VERSION ""

NS_ :

BS_:

BU_: HVESP01 HVESS

BO_ 2499750245 HVESP01_EstOcv_1: 8 HVESP01
 SG_ HVESP01_estOcv_01_1 m0: 8|14@1+ (0.001,0) [0|16.383] "Ah"  HVESP01
 SG_ HVESP01_estOcv_02_1 m0: 22|14@1+ (0.001,0) [0|16.383] "Ah"  HVESP01
 SG_ HVESP01_estOcv_03_1 m0: 36|14@1+ (0.001,0) [0|16.383] "Ah"  HVESP01
 SG_ HVESP01_estOcv_04_1 m0: 50|14@1+ (0.001,0) [0|16.383] "Ah"  HVESP01
 SG_ HVESP01_estOcv_05_1 m1: 8|14@1+ (0.001,0) [0|16.383] "Ah"  HVESP01
 SG_ HVESP01_estOcv_06_1 m1: 22|14@1+ (0.001,0) [0|16.383] "Ah"  HVESP01
 SG_ HVESP01_estOcv_07_1 m1: 36|14@1+ (0.001,0) [0|16.383] "Ah"  HVESP01
 SG_ HVESP01_estOcv_08_1 m1: 50|14@1+ (0.001,0) [0|16.383] "Ah"  HVESP01
 SG_ HVESP01_estOcv_09_1 m2: 8|14@1+ (0.001,0) [0|16.383] "Ah"  HVESP01
 SG_ HVESP01_estOcv_10_1 m2: 22|14@1+ (0.001,0) [0|16.383] "Ah"  HVESP01
 SG_ HVESP01_estOcv_11_1 m2: 36|14@1+ (0.001,0) [0|16.383] "Ah"  HVESP01
 SG_ HVESP01_estOcv_12_1 m2: 50|14@1+ (0.001,0) [0|16.383] "Ah"  HVESP01
 SG_ HVESP01_estOcv_13_1 m3: 8|14@1+ (0.001,0) [0|16.383] "Ah"  HVESP01
 SG_ HVESP01_estOcv_14_1 m3: 22|14@1+ (0.001,0) [0|16.383] "Ah"  HVESP01
 SG_ HVESP01_estOcv_15_1 m3: 36|14@1+ (0.001,0) [0|16.383] "Ah"  HVESP01
 SG_ HVESP01_estOcv_16_1 m3: 50|14@1+ (0.001,0) [0|16.383] "Ah"  HVESP01
 SG_ HVESP01_estOcv_17_1 m4: 8|14@1+ (0.001,0) [0|16.383] "Ah"  HVESP01
 SG_ HVESP01_estOcv_18_1 m4: 22|14@1+ (0.001,0) [0|16.383] "Ah"  HVESP01
 SG_ HVESP01_estOcv_19_1 m4: 36|14@1+ (0.001,0) [0|16.383] "Ah"  HVESP01
 SG_ HVESP01_estOcv_20_1 m4: 50|14@1+ (0.001,0) [0|16.383] "Ah"  HVESP01
 SG_ HVESP01_estOcv_21_1 m5: 8|14@1+ (0.001,0) [0|16.383] "Ah"  HVESP01
 SG_ HVESP01_estOcv_22_1 m5: 22|14@1+ (0.001,0) [0|16.383] "Ah"  HVESP01
 SG_ HVESP01_estOcv_23_1 m5: 36|14@1+ (0.001,0) [0|16.383] "Ah"  HVESP01
 SG_ HVESP01_estOcv_24_1 m5: 50|14@1+ (0.001,0) [0|16.383] "Ah"  HVESP01
 SG_ HVESP01_estOcv_25_1 m6: 8|14@1+ (0.001,0) [0|16.383] "Ah"  HVESP01
 SG_ HVESP01_estOcv_26_1 m6: 22|14@1+ (0.001,0) [0|16.383] "Ah"  HVESP01
 SG_ HVESP01_estOcv_27_1 m6: 36|14@1+ (0.001,0) [0|16.383] "Ah"  HVESP01
 SG_ HVESP01_estOcv_28_1 m6: 50|14@1+ (0.001,0) [0|16.383] "Ah"  HVESP01
 SG_ HVESP01_estOcv_29_1 m7: 8|14@1+ (0.001,0) [0|16.383] "Ah"  HVESP01
 SG_ HVESP01_estOcv_30_1 m7: 22|14@1+ (0.001,0) [0|16.383] "Ah"  HVESP01
 SG_ HVESP01_estOcv_31_1 m7: 36|14@1+ (0.001,0) [0|16.383] "Ah"  HVESP01
 SG_ HVESP01_estOcv_32_1 m7: 50|14@1+ (0.001,0) [0|16.383] "Ah"  HVESP01
 SG_ HVESP01_estOcv_33_1 m8: 8|14@1+ (0.001,0) [0|16.383] "Ah"  HVESP01
 SG_ HVESP01_estOcv_34_1 m8: 22|14@1+ (0.001,0) [0|16.383] "Ah"  HVESP01
 SG_ HVESP01_estOcv_35_1 m8: 36|14@1+ (0.001,0) [0|16.383] "Ah"  HVESP01
 SG_ HVESP01_estOcv_36_1 m8: 50|14@1+ (0.001,0) [0|16.383] "Ah"  HVESP01
 SG_ HVESP01_estOcv_37_1 m9: 8|14@1+ (0.001,0) [0|16.383] "Ah"  HVESP01
 SG_ HVESP01_estOcv_38_1 m9: 22|14@1+ (0.001,0) [0|16.383] "Ah"  HVESP01
 SG_ HVESP01_estOcv_39_1 m9: 36|14@1+ (0.001,0) [0|16.383] "Ah"  HVESP01
 SG_ HVESP01_estOcv_40_1 m9: 50|14@1+ (0.001,0) [0|16.383] "Ah"  HVESP01
 SG_ HVESP01_estOcv_41_1 m10: 8|14@1+ (0.001,0) [0|16.383] "Ah"  HVESP01
 SG_ HVESP01_estOcv_42_1 m10: 22|14@1+ (0.001,0) [0|16.383] "Ah"  HVESP01
 SG_ HVESP01_estOcv_43_1 m10: 36|14@1+ (0.001,0) [0|16.383] "Ah"  HVESP01
 SG_ HVESP01_estOcv_44_1 m10: 50|14@1+ (0.001,0) [0|16.383] "Ah"  HVESP01
 SG_ HVESP01_estOcv_45_1 m11: 8|14@1+ (0.001,0) [0|16.383] "Ah"  HVESP01
 SG_ HVESP01_estOcv_46_1 m11: 22|14@1+ (0.001,0) [0|16.383] "Ah"  HVESP01
 SG_ HVESP01_estOcv_47_1 m11: 36|14@1+ (0.001,0) [0|16.383] "Ah"  HVESP01
 SG_ HVESP01_estOcv_48_1 m11: 50|14@1+ (0.001,0) [0|16.383] "Ah"  HVESP01
 SG_ HVESP01_estOcv_49_1 m12: 8|14@1+ (0.001,0) [0|16.383] "Ah"  HVESP01
 SG_ HVESP01_estOcv_50_1 m12: 22|14@1+ (0.001,0) [0|16.383] "Ah"  HVESP01
 SG_ HVESP01_estOcv_51_1 m12: 36|14@1+ (0.001,0) [0|16.383] "Ah"  HVESP01
 SG_ HVESP01_estOcv_52_1 m12: 50|14@1+ (0.001,0) [0|16.383] "Ah"  HVESP01
 SG_ HVESP01_estOcv_53_1 m13: 8|14@1+ (0.001,0) [0|16.383] "Ah"  HVESP01
 SG_ HVESP01_estOcv_54_1 m13: 22|14@1+ (0.001,0) [0|16.383] "Ah"  HVESP01
 SG_ HVESP01_estOcv_55_1 m13: 36|14@1+ (0.001,0) [0|16.383] "Ah"  HVESP01
 SG_ HVESP01_estOcv_56_1 m13: 50|14@1+ (0.001,0) [0|16.383] "Ah"  HVESP01
 SG_ HVESP01_estOcv_57_1 m14: 8|14@1+ (0.001,0) [0|16.383] "Ah"  HVESP01
 SG_ HVESP01_estOcv_58_1 m14: 22|14@1+ (0.001,0) [0|16.383] "Ah"  HVESP01
 SG_ HVESP01_estOcv_59_1 m14: 36|14@1+ (0.001,0) [0|16.383] "Ah"  HVESP01
 SG_ HVESP01_estOcv_60_1 m14: 50|14@1+ (0.001,0) [0|16.383] "Ah"  HVESP01
 SG_ HVESP01_estOcv_61_1 m15: 8|14@1+ (0.001,0) [0|16.383] "Ah"  HVESP01
 SG_ HVESP01_estOcv_62_1 m15: 22|14@1+ (0.001,0) [0|16.383] "Ah"  HVESP01
 SG_ HVESP01_estOcv_63_1 m15: 36|14@1+ (0.001,0) [0|16.383] "Ah"  HVESP01
 SG_ HVESP01_estOcv_64_1 m15: 50|14@1+ (0.001,0) [0|16.383] "Ah"  HVESP01
 SG_ HVESP01_estOcv_65_1 m16: 8|14@1+ (0.001,0) [0|16.383] "Ah"  HVESP01
 SG_ HVESP01_estOcv_66_1 m16: 22|14@1+ (0.001,0) [0|16.383] "Ah"  HVESP01
 SG_ HVESP01_estOcv_67_1 m16: 36|14@1+ (0.001,0) [0|16.383] "Ah"  HVESP01
 SG_ HVESP01_estOcv_68_1 m16: 50|14@1+ (0.001,0) [0|16.383] "Ah"  HVESP01
 SG_ HVESP01_estOcv_69_1 m17: 8|14@1+ (0.001,0) [0|16.383] "Ah"  HVESP01
 SG_ HVESP01_estOcv_70_1 m17: 22|14@1+ (0.001,0) [0|16.383] "Ah"  HVESP01
 SG_ HVESP01_estOcv_71_1 m17: 36|14@1+ (0.001,0) [0|16.383] "Ah"  HVESP01
 SG_ HVESP01_estOcv_72_1 m17: 50|14@1+ (0.001,0) [0|16.383] "Ah"  HVESP01
 SG_ HVESP01_estOcv_73_1 m18: 8|14@1+ (0.001,0) [0|16.383] "Ah"  HVESP01
 SG_ HVESP01_estOcv_74_1 m18: 22|14@1+ (0.001,0) [0|16.383] "Ah"  HVESP01
 SG_ HVESP01_estOcv_75_1 m18: 36|14@1+ (0.001,0) [0|16.383] "Ah"  HVESP01
 SG_ HVESP01_estOcv_76_1 m18: 50|14@1+ (0.001,0) [0|16.383] "Ah"  HVESP01
 SG_ HVESP01_estOcv_77_1 m19: 8|14@1+ (0.001,0) [0|16.383] "Ah"  HVESP01
 SG_ HVESP01_estOcv_78_1 m19: 22|14@1+ (0.001,0) [0|16.383] "Ah"  HVESP01
 SG_ HVESP01_estOcv_79_1 m19: 36|14@1+ (0.001,0) [0|16.383] "Ah"  HVESP01
 SG_ HVESP01_estOcv_80_1 m19: 50|14@1+ (0.001,0) [0|16.383] "Ah"  HVESP01
 SG_ HVESP01_estOcv_81_1 m20: 8|14@1+ (0.001,0) [0|16.383] "Ah"  HVESP01
 SG_ HVESP01_estOcv_82_1 m20: 22|14@1+ (0.001,0) [0|16.383] "Ah"  HVESP01
 SG_ HVESP01_estOcv_83_1 m20: 36|14@1+ (0.001,0) [0|16.383] "Ah"  HVESP01
 SG_ HVESP01_estOcv_84_1 m20: 50|14@1+ (0.001,0) [0|16.383] "Ah"  HVESP01
 SG_ HVESP01_estOcv_85_1 m21: 8|14@1+ (0.001,0) [0|16.383] "Ah"  HVESP01
 SG_ HVESP01_estOcv_86_1 m21: 22|14@1+ (0.001,0) [0|16.383] "Ah"  HVESP01
 SG_ HVESP01_estOcv_87_1 m21: 36|14@1+ (0.001,0) [0|16.383] "Ah"  HVESP01
 SG_ HVESP01_estOcv_88_1 m21: 50|14@1+ (0.001,0) [0|16.383] "Ah"  HVESP01
 SG_ HVESP01_estOcv_89_1 m22: 8|14@1+ (0.001,0) [0|16.383] "Ah"  HVESP01
 SG_ HVESP01_estOcv_90_1 m22: 22|14@1+ (0.001,0) [0|16.383] "Ah"  HVESP01
 SG_ HVESP01_estOcv_91_1 m22: 36|14@1+ (0.001,0) [0|16.383] "Ah"  HVESP01
 SG_ HVESP01_estOcv_92_1 m22: 50|14@1+ (0.001,0) [0|16.383] "Ah"  HVESP01
 SG_ HVESP01_estOcv_93_1 m23: 8|14@1+ (0.001,0) [0|16.383] "Ah"  HVESP01
 SG_ HVESP01_estOcv_94_1 m23: 22|14@1+ (0.001,0) [0|16.383] "Ah"  HVESP01
 SG_ HVESP01_estOcv_95_1 m23: 36|14@1+ (0.001,0) [0|16.383] "Ah"  HVESP01
 SG_ HVESP01_estOcv_96_1 m23: 50|14@1+ (0.001,0) [0|16.383] "Ah"  HVESP01
 SG_ HVESP01_estOcv_97_1 m24: 8|14@1+ (0.001,0) [0|16.383] "Ah"  HVESP01
 SG_ HVESP01_estOcv_98_1 m24: 22|14@1+ (0.001,0) [0|16.383] "Ah"  HVESP01
 SG_ HVESP01_estOcv_99_1 m24: 36|14@1+ (0.001,0) [0|16.383] "Ah"  HVESP01
 SG_ HVESP01_estOcv_100_1 m24: 50|14@1+ (0.001,0) [0|16.383] "Ah"  HVESP01
 SG_ HVESP01_estOcv_101_1 m25: 8|14@1+ (0.001,0) [0|16.383] "Ah"  HVESP01
 SG_ HVESP01_estOcv_102_1 m25: 22|14@1+ (0.001,0) [0|16.383] "Ah"  HVESP01
 SG_ HVESP01_estOcv_103_1 m25: 36|14@1+ (0.001,0) [0|16.383] "Ah"  HVESP01
 SG_ HVESP01_estOcv_104_1 m25: 50|14@1+ (0.001,0) [0|16.383] "Ah"  HVESP01
 SG_ HVESP01_estOcv_105_1 m26: 8|14@1+ (0.001,0) [0|16.383] "Ah"  HVESP01
 SG_ HVESP01_estOcv_106_1 m26: 22|14@1+ (0.001,0) [0|16.383] "Ah"  HVESP01
 SG_ HVESP01_estOcv_107_1 m26: 36|14@1+ (0.001,0) [0|16.383] "Ah"  HVESP01
 SG_ HVESP01_estOcv_108_1 m26: 50|14@1+ (0.001,0) [0|16.383] "Ah"  HVESP01
 SG_ HVESP01_estOcv_109_1 m27: 8|14@1+ (0.001,0) [0|16.383] "Ah"  HVESP01
 SG_ HVESP01_estOcv_110_1 m27: 22|14@1+ (0.001,0) [0|16.383] "Ah"  HVESP01
 SG_ HVESP01_estOcv_111_1 m27: 36|14@1+ (0.001,0) [0|16.383] "Ah"  HVESP01
 SG_ HVESP01_estOcv_112_1 m27: 50|14@1+ (0.001,0) [0|16.383] "Ah"  HVESP01
 SG_ HVESP01_estOcv_113_1 m28: 8|14@1+ (0.001,0) [0|16.383] "Ah"  HVESP01
 SG_ HVESP01_estOcv_114_1 m28: 22|14@1+ (0.001,0) [0|16.383] "Ah"  HVESP01
 SG_ HVESP01_estOcv_115_1 m28: 36|14@1+ (0.001,0) [0|16.383] "Ah"  HVESP01
 SG_ HVESP01_estOcv_116_1 m28: 50|14@1+ (0.001,0) [0|16.383] "Ah"  HVESP01
 SG_ HVESP01_estOcv_117_1 m29: 8|14@1+ (0.001,0) [0|16.383] "Ah"  HVESP01
 SG_ HVESP01_estOcv_118_1 m29: 22|14@1+ (0.001,0) [0|16.383] "Ah"  HVESP01
 SG_ HVESP01_estOcv_119_1 m29: 36|14@1+ (0.001,0) [0|16.383] "Ah"  HVESP01
 SG_ HVESP01_estOcv_120_1 m29: 50|14@1+ (0.001,0) [0|16.383] "Ah"  HVESP01
 SG_ HVESP01_estOcv_121_1 m30: 8|14@1+ (0.001,0) [0|16.383] "Ah"  HVESP01
 SG_ HVESP01_estOcv_122_1 m30: 22|14@1+ (0.001,0) [0|16.383] "Ah"  HVESP01
 SG_ HVESP01_estOcv_123_1 m30: 36|14@1+ (0.001,0) [0|16.383] "Ah"  HVESP01
 SG_ HVESP01_estOcv_124_1 m30: 50|14@1+ (0.001,0) [0|16.383] "Ah"  HVESP01
 SG_ HVESP01_estOcv_125_1 m31: 8|14@1+ (0.001,0) [0|16.383] "Ah"  HVESP01
 SG_ HVESP01_estOcv_126_1 m31: 22|14@1+ (0.001,0) [0|16.383] "Ah"  HVESP01
 SG_ HVESP01_estOcv_127_1 m31: 36|14@1+ (0.001,0) [0|16.383] "Ah"  HVESP01
 SG_ HVESP01_estOcv_128_1 m31: 50|14@1+ (0.001,0) [0|16.383] "Ah"  HVESP01
 SG_ HVESP01_estOcv_129_1 m32: 8|14@1+ (0.001,0) [0|16.383] "Ah"  HVESP01
 SG_ HVESP01_estOcv_130_1 m32: 22|14@1+ (0.001,0) [0|16.383] "Ah"  HVESP01
 SG_ HVESP01_estOcv_131_1 m32: 36|14@1+ (0.001,0) [0|16.383] "Ah"  HVESP01
 SG_ HVESP01_estOcv_132_1 m32: 50|14@1+ (0.001,0) [0|16.383] "Ah"  HVESP01
 SG_ HVESP01_estOcv_133_1 m33: 8|14@1+ (0.001,0) [0|16.383] "Ah"  HVESP01
 SG_ HVESP01_estOcv_134_1 m33: 22|14@1+ (0.001,0) [0|16.383] "Ah"  HVESP01
 SG_ HVESP01_estOcv_135_1 m33: 36|14@1+ (0.001,0) [0|16.383] "Ah"  HVESP01
 SG_ HVESP01_estOcv_136_1 m33: 50|14@1+ (0.001,0) [0|16.383] "Ah"  HVESP01
 SG_ HVESP01_estOcv_137_1 m34: 8|14@1+ (0.001,0) [0|16.383] "Ah"  HVESP01
 SG_ HVESP01_estOcv_138_1 m34: 22|14@1+ (0.001,0) [0|16.383] "Ah"  HVESP01
 SG_ HVESP01_estOcv_139_1 m34: 36|14@1+ (0.001,0) [0|16.383] "Ah"  HVESP01
 SG_ HVESP01_estOcv_140_1 m34: 50|14@1+ (0.001,0) [0|16.383] "Ah"  HVESP01
 SG_ HVESP01_estOcv_141_1 m35: 8|14@1+ (0.001,0) [0|16.383] "Ah"  HVESP01
 SG_ HVESP01_estOcv_142_1 m35: 22|14@1+ (0.001,0) [0|16.383] "Ah"  HVESP01
 SG_ HVESP01_estOcv_143_1 m35: 36|14@1+ (0.001,0) [0|16.383] "Ah"  HVESP01
 SG_ HVESP01_estOcv_144_1 m35: 50|14@1+ (0.001,0) [0|16.383] "Ah"  HVESP01
 SG_ HVESP01_estOcv_145_1 m36: 8|14@1+ (0.001,0) [0|16.383] "Ah"  HVESP01
 SG_ HVESP01_estOcv_146_1 m36: 22|14@1+ (0.001,0) [0|16.383] "Ah"  HVESP01
 SG_ HVESP01_estOcv_147_1 m36: 36|14@1+ (0.001,0) [0|16.383] "Ah"  HVESP01
 SG_ HVESP01_estOcv_148_1 m36: 50|14@1+ (0.001,0) [0|16.383] "Ah"  HVESP01
 SG_ HVESP01_estOcv_149_1 m37: 8|14@1+ (0.001,0) [0|16.383] "Ah"  HVESP01
 SG_ HVESP01_estOcv_150_1 m37: 22|14@1+ (0.001,0) [0|16.383] "Ah"  HVESP01
 SG_ HVESP01_estOcv_151_1 m37: 36|14@1+ (0.001,0) [0|16.383] "Ah"  HVESP01
 SG_ HVESP01_estOcv_152_1 m37: 50|14@1+ (0.001,0) [0|16.383] "Ah"  HVESP01
 SG_ HVESP01_estOcv_153_1 m38: 8|14@1+ (0.001,0) [0|16.383] "Ah"  HVESP01
 SG_ HVESP01_estOcv_154_1 m38: 22|14@1+ (0.001,0) [0|16.383] "Ah"  HVESP01
 SG_ HVESP01_estOcv_155_1 m38: 36|14@1+ (0.001,0) [0|16.383] "Ah"  HVESP01
 SG_ HVESP01_estOcv_156_1 m38: 50|14@1+ (0.001,0) [0|16.383] "Ah"  HVESP01
 SG_ HVESP01_estOcv_157_1 m39: 8|14@1+ (0.001,0) [0|16.383] "Ah"  HVESP01
 SG_ HVESP01_estOcv_158_1 m39: 22|14@1+ (0.001,0) [0|16.383] "Ah"  HVESP01
 SG_ HVESP01_estOcv_159_1 m39: 36|14@1+ (0.001,0) [0|16.383] "Ah"  HVESP01
 SG_ HVESP01_estOcv_160_1 m39: 50|14@1+ (0.001,0) [0|16.383] "Ah"  HVESP01
 SG_ HVESP01_estOcv_161_1 m40: 8|14@1+ (0.001,0) [0|16.383] "Ah"  HVESP01
 SG_ HVESP01_estOcv_162_1 m40: 22|14@1+ (0.001,0) [0|16.383] "Ah"  HVESP01
 SG_ HVESP01_estOcv_163_1 m40: 36|14@1+ (0.001,0) [0|16.383] "Ah"  HVESP01
 SG_ HVESP01_estOcv_164_1 m40: 50|14@1+ (0.001,0) [0|16.383] "Ah"  HVESP01
 SG_ HVESP01_estOcv_165_1 m41: 8|14@1+ (0.001,0) [0|16.383] "Ah"  HVESP01
 SG_ HVESP01_estOcv_166_1 m41: 22|14@1+ (0.001,0) [0|16.383] "Ah"  HVESP01
 SG_ HVESP01_estOcv_167_1 m41: 36|14@1+ (0.001,0) [0|16.383] "Ah"  HVESP01
 SG_ HVESP01_estOcv_168_1 m41: 50|14@1+ (0.001,0) [0|16.383] "Ah"  HVESP01
 SG_ HVESP01_estOcv_169_1 m42: 8|14@1+ (0.001,0) [0|16.383] "Ah"  HVESP01
 SG_ HVESP01_estOcv_170_1 m42: 22|14@1+ (0.001,0) [0|16.383] "Ah"  HVESP01
 SG_ HVESP01_estOcv_171_1 m42: 36|14@1+ (0.001,0) [0|16.383] "Ah"  HVESP01
 SG_ HVESP01_estOcv_172_1 m42: 50|14@1+ (0.001,0) [0|16.383] "Ah"  HVESP01
 SG_ HVESP01_estOcv_173_1 m43: 8|14@1+ (0.001,0) [0|16.383] "Ah"  HVESP01
 SG_ HVESP01_estOcv_174_1 m43: 22|14@1+ (0.001,0) [0|16.383] "Ah"  HVESP01
 SG_ HVESP01_estOcv_175_1 m43: 36|14@1+ (0.001,0) [0|16.383] "Ah"  HVESP01
 SG_ HVESP01_estOcv_176_1 m43: 50|14@1+ (0.001,0) [0|16.383] "Ah"  HVESP01
 SG_ HVESP01_estOcv_177_1 m44: 8|14@1+ (0.001,0) [0|16.383] "Ah"  HVESP01
 SG_ HVESP01_estOcv_178_1 m44: 22|14@1+ (0.001,0) [0|16.383] "Ah"  HVESP01
 SG_ HVESP01_estOcv_179_1 m44: 36|14@1+ (0.001,0) [0|16.383] "Ah"  HVESP01
 SG_ HVESP01_estOcv_180_1 m44: 50|14@1+ (0.001,0) [0|16.383] "Ah"  HVESP01
 SG_ HVESP01_estOcv_181_1 m45: 8|14@1+ (0.001,0) [0|16.383] "Ah"  HVESP01
 SG_ HVESP01_estOcv_182_1 m45: 22|14@1+ (0.001,0) [0|16.383] "Ah"  HVESP01
 SG_ HVESP01_estOcv_183_1 m45: 36|14@1+ (0.001,0) [0|16.383] "Ah"  HVESP01
 SG_ HVESP01_estOcv_184_1 m45: 50|14@1+ (0.001,0) [0|16.383] "Ah"  HVESP01
 SG_ HVESP01_estOcv_185_1 m46: 8|14@1+ (0.001,0) [0|16.383] "Ah"  HVESP01
 SG_ HVESP01_estOcv_186_1 m46: 22|14@1+ (0.001,0) [0|16.383] "Ah"  HVESP01
 SG_ HVESP01_estOcv_187_1 m46: 36|14@1+ (0.001,0) [0|16.383] "Ah"  HVESP01
 SG_ HVESP01_estOcv_188_1 m46: 50|14@1+ (0.001,0) [0|16.383] "Ah"  HVESP01
 SG_ HVESP01_estOcv_189_1 m47: 8|14@1+ (0.001,0) [0|16.383] "Ah"  HVESP01
 SG_ HVESP01_estOcv_190_1 m47: 22|14@1+ (0.001,0) [0|16.383] "Ah"  HVESP01
 SG_ HVESP01_estOcv_191_1 m47: 36|14@1+ (0.001,0) [0|16.383] "Ah"  HVESP01
 SG_ HVESP01_estOcv_192_1 m47: 50|14@1+ (0.001,0) [0|16.383] "Ah"  HVESP01
 SG_ multiplexoreo_1 M: 0|8@1+ (1,0) [0|255] ""  HVESP01

BO_ 2499750246 HVESP01_EstOcv_2: 8 HVESP01
 SG_ HVESP01_estOcv_01_2 m0: 8|14@1+ (0.001,0) [0|16.383] "Ah"  HVESP01
 SG_ HVESP01_estOcv_02_2 m0: 22|14@1+ (0.001,0) [0|16.383] "Ah"  HVESP01
 SG_ HVESP01_estOcv_03_2 m0: 36|14@1+ (0.001,0) [0|16.383] "Ah"  HVESP01
 SG_ HVESP01_estOcv_04_2 m0: 50|14@1+ (0.001,0) [0|16.383] "Ah"  HVESP01
 SG_ HVESP01_estOcv_05_2 m1: 8|14@1+ (0.001,0) [0|16.383] "Ah"  HVESP01
 SG_ HVESP01_estOcv_06_2 m1: 22|14@1+ (0.001,0) [0|16.383] "Ah"  HVESP01
 SG_ HVESP01_estOcv_07_2 m1: 36|14@1+ (0.001,0) [0|16.383] "Ah"  HVESP01
 SG_ HVESP01_estOcv_08_2 m1: 50|14@1+ (0.001,0) [0|16.383] "Ah"  HVESP01
 SG_ HVESP01_estOcv_09_2 m2: 8|14@1+ (0.001,0) [0|16.383] "Ah"  HVESP01
 SG_ HVESP01_estOcv_10_2 m2: 22|14@1+ (0.001,0) [0|16.383] "Ah"  HVESP01
 SG_ HVESP01_estOcv_11_2 m2: 36|14@1+ (0.001,0) [0|16.383] "Ah"  HVESP01
 SG_ HVESP01_estOcv_12_2 m2: 50|14@1+ (0.001,0) [0|16.383] "Ah"  HVESP01
 SG_ HVESP01_estOcv_13_2 m3: 8|14@1+ (0.001,0) [0|16.383] "Ah"  HVESP01
 SG_ HVESP01_estOcv_14_2 m3: 22|14@1+ (0.001,0) [0|16.383] "Ah"  HVESP01
 SG_ HVESP01_estOcv_15_2 m3: 36|14@1+ (0.001,0) [0|16.383] "Ah"  HVESP01
 SG_ HVESP01_estOcv_16_2 m3: 50|14@1+ (0.001,0) [0|16.383] "Ah"  HVESP01
 SG_ HVESP01_estOcv_17_2 m4: 8|14@1+ (0.001,0) [0|16.383] "Ah"  HVESP01
 SG_ HVESP01_estOcv_18_2 m4: 22|14@1+ (0.001,0) [0|16.383] "Ah"  HVESP01
 SG_ HVESP01_estOcv_19_2 m4: 36|14@1+ (0.001,0) [0|16.383] "Ah"  HVESP01
 SG_ HVESP01_estOcv_20_2 m4: 50|14@1+ (0.001,0) [0|16.383] "Ah"  HVESP01
 SG_ HVESP01_estOcv_21_2 m5: 8|14@1+ (0.001,0) [0|16.383] "Ah"  HVESP01
 SG_ HVESP01_estOcv_22_2 m5: 22|14@1+ (0.001,0) [0|16.383] "Ah"  HVESP01
 SG_ HVESP01_estOcv_23_2 m5: 36|14@1+ (0.001,0) [0|16.383] "Ah"  HVESP01
 SG_ HVESP01_estOcv_24_2 m5: 50|14@1+ (0.001,0) [0|16.383] "Ah"  HVESP01
 SG_ HVESP01_estOcv_25_2 m6: 8|14@1+ (0.001,0) [0|16.383] "Ah"  HVESP01
 SG_ HVESP01_estOcv_26_2 m6: 22|14@1+ (0.001,0) [0|16.383] "Ah"  HVESP01
 SG_ HVESP01_estOcv_27_2 m6: 36|14@1+ (0.001,0) [0|16.383] "Ah"  HVESP01
 SG_ HVESP01_estOcv_28_2 m6: 50|14@1+ (0.001,0) [0|16.383] "Ah"  HVESP01
 SG_ HVESP01_estOcv_29_2 m7: 8|14@1+ (0.001,0) [0|16.383] "Ah"  HVESP01
 SG_ HVESP01_estOcv_30_2 m7: 22|14@1+ (0.001,0) [0|16.383] "Ah"  HVESP01
 SG_ HVESP01_estOcv_31_2 m7: 36|14@1+ (0.001,0) [0|16.383] "Ah"  HVESP01
 SG_ HVESP01_estOcv_32_2 m7: 50|14@1+ (0.001,0) [0|16.383] "Ah"  HVESP01
 SG_ HVESP01_estOcv_33_2 m8: 8|14@1+ (0.001,0) [0|16.383] "Ah"  HVESP01
 SG_ HVESP01_estOcv_34_2 m8: 22|14@1+ (0.001,0) [0|16.383] "Ah"  HVESP01
 SG_ HVESP01_estOcv_35_2 m8: 36|14@1+ (0.001,0) [0|16.383] "Ah"  HVESP01
 SG_ HVESP01_estOcv_36_2 m8: 50|14@1+ (0.001,0) [0|16.383] "Ah"  HVESP01
 SG_ HVESP01_estOcv_37_2 m9: 8|14@1+ (0.001,0) [0|16.383] "Ah"  HVESP01
 SG_ HVESP01_estOcv_38_2 m9: 22|14@1+ (0.001,0) [0|16.383] "Ah"  HVESP01
 SG_ HVESP01_estOcv_39_2 m9: 36|14@1+ (0.001,0) [0|16.383] "Ah"  HVESP01
 SG_ HVESP01_estOcv_40_2 m9: 50|14@1+ (0.001,0) [0|16.383] "Ah"  HVESP01
 SG_ HVESP01_estOcv_41_2 m10: 8|14@1+ (0.001,0) [0|16.383] "Ah"  HVESP01
 SG_ HVESP01_estOcv_42_2 m10: 22|14@1+ (0.001,0) [0|16.383] "Ah"  HVESP01
 SG_ HVESP01_estOcv_43_2 m10: 36|14@1+ (0.001,0) [0|16.383] "Ah"  HVESP01
 SG_ HVESP01_estOcv_44_2 m10: 50|14@1+ (0.001,0) [0|16.383] "Ah"  HVESP01
 SG_ HVESP01_estOcv_45_2 m11: 8|14@1+ (0.001,0) [0|16.383] "Ah"  HVESP01
 SG_ HVESP01_estOcv_46_2 m11: 22|14@1+ (0.001,0) [0|16.383] "Ah"  HVESP01
 SG_ HVESP01_estOcv_47_2 m11: 36|14@1+ (0.001,0) [0|16.383] "Ah"  HVESP01
 SG_ HVESP01_estOcv_48_2 m11: 50|14@1+ (0.001,0) [0|16.383] "Ah"  HVESP01
 SG_ HVESP01_estOcv_49_2 m12: 8|14@1+ (0.001,0) [0|16.383] "Ah"  HVESP01
 SG_ HVESP01_estOcv_50_2 m12: 22|14@1+ (0.001,0) [0|16.383] "Ah"  HVESP01
 SG_ HVESP01_estOcv_51_2 m12: 36|14@1+ (0.001,0) [0|16.383] "Ah"  HVESP01
 SG_ HVESP01_estOcv_52_2 m12: 50|14@1+ (0.001,0) [0|16.383] "Ah"  HVESP01
 SG_ HVESP01_estOcv_53_2 m13: 8|14@1+ (0.001,0) [0|16.383] "Ah"  HVESP01
 SG_ HVESP01_estOcv_54_2 m13: 22|14@1+ (0.001,0) [0|16.383] "Ah"  HVESP01
 SG_ HVESP01_estOcv_55_2 m13: 36|14@1+ (0.001,0) [0|16.383] "Ah"  HVESP01
 SG_ HVESP01_estOcv_56_2 m13: 50|14@1+ (0.001,0) [0|16.383] "Ah"  HVESP01
 SG_ HVESP01_estOcv_57_2 m14: 8|14@1+ (0.001,0) [0|16.383] "Ah"  HVESP01
 SG_ HVESP01_estOcv_58_2 m14: 22|14@1+ (0.001,0) [0|16.383] "Ah"  HVESP01
 SG_ HVESP01_estOcv_59_2 m14: 36|14@1+ (0.001,0) [0|16.383] "Ah"  HVESP01
 SG_ HVESP01_estOcv_60_2 m14: 50|14@1+ (0.001,0) [0|16.383] "Ah"  HVESP01
 SG_ HVESP01_estOcv_61_2 m15: 8|14@1+ (0.001,0) [0|16.383] "Ah"  HVESP01
 SG_ HVESP01_estOcv_62_2 m15: 22|14@1+ (0.001,0) [0|16.383] "Ah"  HVESP01
 SG_ HVESP01_estOcv_63_2 m15: 36|14@1+ (0.001,0) [0|16.383] "Ah"  HVESP01
 SG_ HVESP01_estOcv_64_2 m15: 50|14@1+ (0.001,0) [0|16.383] "Ah"  HVESP01
 SG_ HVESP01_estOcv_65_2 m16: 8|14@1+ (0.001,0) [0|16.383] "Ah"  HVESP01
 SG_ HVESP01_estOcv_66_2 m16: 22|14@1+ (0.001,0) [0|16.383] "Ah"  HVESP01
 SG_ HVESP01_estOcv_67_2 m16: 36|14@1+ (0.001,0) [0|16.383] "Ah"  HVESP01
 SG_ HVESP01_estOcv_68_2 m16: 50|14@1+ (0.001,0) [0|16.383] "Ah"  HVESP01
 SG_ HVESP01_estOcv_69_2 m17: 8|14@1+ (0.001,0) [0|16.383] "Ah"  HVESP01
 SG_ HVESP01_estOcv_70_2 m17: 22|14@1+ (0.001,0) [0|16.383] "Ah"  HVESP01
 SG_ HVESP01_estOcv_71_2 m17: 36|14@1+ (0.001,0) [0|16.383] "Ah"  HVESP01
 SG_ HVESP01_estOcv_72_2 m17: 50|14@1+ (0.001,0) [0|16.383] "Ah"  HVESP01
 SG_ HVESP01_estOcv_73_2 m18: 8|14@1+ (0.001,0) [0|16.383] "Ah"  HVESP01
 SG_ HVESP01_estOcv_74_2 m18: 22|14@1+ (0.001,0) [0|16.383] "Ah"  HVESP01
 SG_ HVESP01_estOcv_75_2 m18: 36|14@1+ (0.001,0) [0|16.383] "Ah"  HVESP01
 SG_ HVESP01_estOcv_76_2 m18: 50|14@1+ (0.001,0) [0|16.383] "Ah"  HVESP01
 SG_ HVESP01_estOcv_77_2 m19: 8|14@1+ (0.001,0) [0|16.383] "Ah"  HVESP01
 SG_ HVESP01_estOcv_78_2 m19: 22|14@1+ (0.001,0) [0|16.383] "Ah"  HVESP01
 SG_ HVESP01_estOcv_79_2 m19: 36|14@1+ (0.001,0) [0|16.383] "Ah"  HVESP01
 SG_ HVESP01_estOcv_80_2 m19: 50|14@1+ (0.001,0) [0|16.383] "Ah"  HVESP01
 SG_ HVESP01_estOcv_81_2 m20: 8|14@1+ (0.001,0) [0|16.383] "Ah"  HVESP01
 SG_ HVESP01_estOcv_82_2 m20: 22|14@1+ (0.001,0) [0|16.383] "Ah"  HVESP01
 SG_ HVESP01_estOcv_83_2 m20: 36|14@1+ (0.001,0) [0|16.383] "Ah"  HVESP01
 SG_ HVESP01_estOcv_84_2 m20: 50|14@1+ (0.001,0) [0|16.383] "Ah"  HVESP01
 SG_ HVESP01_estOcv_85_2 m21: 8|14@1+ (0.001,0) [0|16.383] "Ah"  HVESP01
 SG_ HVESP01_estOcv_86_2 m21: 22|14@1+ (0.001,0) [0|16.383] "Ah"  HVESP01
 SG_ HVESP01_estOcv_87_2 m21: 36|14@1+ (0.001,0) [0|16.383] "Ah"  HVESP01
 SG_ HVESP01_estOcv_88_2 m21: 50|14@1+ (0.001,0) [0|16.383] "Ah"  HVESP01
 SG_ HVESP01_estOcv_89_2 m22: 8|14@1+ (0.001,0) [0|16.383] "Ah"  HVESP01
 SG_ HVESP01_estOcv_90_2 m22: 22|14@1+ (0.001,0) [0|16.383] "Ah"  HVESP01
 SG_ HVESP01_estOcv_91_2 m22: 36|14@1+ (0.001,0) [0|16.383] "Ah"  HVESP01
 SG_ HVESP01_estOcv_92_2 m22: 50|14@1+ (0.001,0) [0|16.383] "Ah"  HVESP01
 SG_ HVESP01_estOcv_93_2 m23: 8|14@1+ (0.001,0) [0|16.383] "Ah"  HVESP01
 SG_ HVESP01_estOcv_94_2 m23: 22|14@1+ (0.001,0) [0|16.383] "Ah"  HVESP01
 SG_ HVESP01_estOcv_95_2 m23: 36|14@1+ (0.001,0) [0|16.383] "Ah"  HVESP01
 SG_ HVESP01_estOcv_96_2 m23: 50|14@1+ (0.001,0) [0|16.383] "Ah"  HVESP01
 SG_ HVESP01_estOcv_97_2 m24: 8|14@1+ (0.001,0) [0|16.383] "Ah"  HVESP01
 SG_ HVESP01_estOcv_98_2 m24: 22|14@1+ (0.001,0) [0|16.383] "Ah"  HVESP01
 SG_ HVESP01_estOcv_99_2 m24: 36|14@1+ (0.001,0) [0|16.383] "Ah"  HVESP01
 SG_ HVESP01_estOcv_100_2 m24: 50|14@1+ (0.001,0) [0|16.383] "Ah"  HVESP01
 SG_ HVESP01_estOcv_101_2 m25: 8|14@1+ (0.001,0) [0|16.383] "Ah"  HVESP01
 SG_ HVESP01_estOcv_102_2 m25: 22|14@1+ (0.001,0) [0|16.383] "Ah"  HVESP01
 SG_ HVESP01_estOcv_103_2 m25: 36|14@1+ (0.001,0) [0|16.383] "Ah"  HVESP01
 SG_ HVESP01_estOcv_104_2 m25: 50|14@1+ (0.001,0) [0|16.383] "Ah"  HVESP01
 SG_ HVESP01_estOcv_105_2 m26: 8|14@1+ (0.001,0) [0|16.383] "Ah"  HVESP01
 SG_ HVESP01_estOcv_106_2 m26: 22|14@1+ (0.001,0) [0|16.383] "Ah"  HVESP01
 SG_ HVESP01_estOcv_107_2 m26: 36|14@1+ (0.001,0) [0|16.383] "Ah"  HVESP01
 SG_ HVESP01_estOcv_108_2 m26: 50|14@1+ (0.001,0) [0|16.383] "Ah"  HVESP01
 SG_ HVESP01_estOcv_109_2 m27: 8|14@1+ (0.001,0) [0|16.383] "Ah"  HVESP01
 SG_ HVESP01_estOcv_110_2 m27: 22|14@1+ (0.001,0) [0|16.383] "Ah"  HVESP01
 SG_ HVESP01_estOcv_111_2 m27: 36|14@1+ (0.001,0) [0|16.383] "Ah"  HVESP01
 SG_ HVESP01_estOcv_112_2 m27: 50|14@1+ (0.001,0) [0|16.383] "Ah"  HVESP01
 SG_ HVESP01_estOcv_113_2 m28: 8|14@1+ (0.001,0) [0|16.383] "Ah"  HVESP01
 SG_ HVESP01_estOcv_114_2 m28: 22|14@1+ (0.001,0) [0|16.383] "Ah"  HVESP01
 SG_ HVESP01_estOcv_115_2 m28: 36|14@1+ (0.001,0) [0|16.383] "Ah"  HVESP01
 SG_ HVESP01_estOcv_116_2 m28: 50|14@1+ (0.001,0) [0|16.383] "Ah"  HVESP01
 SG_ HVESP01_estOcv_117_2 m29: 8|14@1+ (0.001,0) [0|16.383] "Ah"  HVESP01
 SG_ HVESP01_estOcv_118_2 m29: 22|14@1+ (0.001,0) [0|16.383] "Ah"  HVESP01
 SG_ HVESP01_estOcv_119_2 m29: 36|14@1+ (0.001,0) [0|16.383] "Ah"  HVESP01
 SG_ HVESP01_estOcv_120_2 m29: 50|14@1+ (0.001,0) [0|16.383] "Ah"  HVESP01
 SG_ HVESP01_estOcv_121_2 m30: 8|14@1+ (0.001,0) [0|16.383] "Ah"  HVESP01
 SG_ HVESP01_estOcv_122_2 m30: 22|14@1+ (0.001,0) [0|16.383] "Ah"  HVESP01
 SG_ HVESP01_estOcv_123_2 m30: 36|14@1+ (0.001,0) [0|16.383] "Ah"  HVESP01
 SG_ HVESP01_estOcv_124_2 m30: 50|14@1+ (0.001,0) [0|16.383] "Ah"  HVESP01
 SG_ HVESP01_estOcv_125_2 m31: 8|14@1+ (0.001,0) [0|16.383] "Ah"  HVESP01
 SG_ HVESP01_estOcv_126_2 m31: 22|14@1+ (0.001,0) [0|16.383] "Ah"  HVESP01
 SG_ HVESP01_estOcv_127_2 m31: 36|14@1+ (0.001,0) [0|16.383] "Ah"  HVESP01
 SG_ HVESP01_estOcv_128_2 m31: 50|14@1+ (0.001,0) [0|16.383] "Ah"  HVESP01
 SG_ HVESP01_estOcv_129_2 m32: 8|14@1+ (0.001,0) [0|16.383] "Ah"  HVESP01
 SG_ HVESP01_estOcv_130_2 m32: 22|14@1+ (0.001,0) [0|16.383] "Ah"  HVESP01
 SG_ HVESP01_estOcv_131_2 m32: 36|14@1+ (0.001,0) [0|16.383] "Ah"  HVESP01
 SG_ HVESP01_estOcv_132_2 m32: 50|14@1+ (0.001,0) [0|16.383] "Ah"  HVESP01
 SG_ HVESP01_estOcv_133_2 m33: 8|14@1+ (0.001,0) [0|16.383] "Ah"  HVESP01
 SG_ HVESP01_estOcv_134_2 m33: 22|14@1+ (0.001,0) [0|16.383] "Ah"  HVESP01
 SG_ HVESP01_estOcv_135_2 m33: 36|14@1+ (0.001,0) [0|16.383] "Ah"  HVESP01
 SG_ HVESP01_estOcv_136_2 m33: 50|14@1+ (0.001,0) [0|16.383] "Ah"  HVESP01
 SG_ HVESP01_estOcv_137_2 m34: 8|14@1+ (0.001,0) [0|16.383] "Ah"  HVESP01
 SG_ HVESP01_estOcv_138_2 m34: 22|14@1+ (0.001,0) [0|16.383] "Ah"  HVESP01
 SG_ HVESP01_estOcv_139_2 m34: 36|14@1+ (0.001,0) [0|16.383] "Ah"  HVESP01
 SG_ HVESP01_estOcv_140_2 m34: 50|14@1+ (0.001,0) [0|16.383] "Ah"  HVESP01
 SG_ HVESP01_estOcv_141_2 m35: 8|14@1+ (0.001,0) [0|16.383] "Ah"  HVESP01
 SG_ HVESP01_estOcv_142_2 m35: 22|14@1+ (0.001,0) [0|16.383] "Ah"  HVESP01
 SG_ HVESP01_estOcv_143_2 m35: 36|14@1+ (0.001,0) [0|16.383] "Ah"  HVESP01
 SG_ HVESP01_estOcv_144_2 m35: 50|14@1+ (0.001,0) [0|16.383] "Ah"  HVESP01
 SG_ HVESP01_estOcv_145_2 m36: 8|14@1+ (0.001,0) [0|16.383] "Ah"  HVESP01
 SG_ HVESP01_estOcv_146_2 m36: 22|14@1+ (0.001,0) [0|16.383] "Ah"  HVESP01
 SG_ HVESP01_estOcv_147_2 m36: 36|14@1+ (0.001,0) [0|16.383] "Ah"  HVESP01
 SG_ HVESP01_estOcv_148_2 m36: 50|14@1+ (0.001,0) [0|16.383] "Ah"  HVESP01
 SG_ HVESP01_estOcv_149_2 m37: 8|14@1+ (0.001,0) [0|16.383] "Ah"  HVESP01
 SG_ HVESP01_estOcv_150_2 m37: 22|14@1+ (0.001,0) [0|16.383] "Ah"  HVESP01
 SG_ HVESP01_estOcv_151_2 m37: 36|14@1+ (0.001,0) [0|16.383] "Ah"  HVESP01
 SG_ HVESP01_estOcv_152_2 m37: 50|14@1+ (0.001,0) [0|16.383] "Ah"  HVESP01
 SG_ HVESP01_estOcv_153_2 m38: 8|14@1+ (0.001,0) [0|16.383] "Ah"  HVESP01
 SG_ HVESP01_estOcv_154_2 m38: 22|14@1+ (0.001,0) [0|16.383] "Ah"  HVESP01
 SG_ HVESP01_estOcv_155_2 m38: 36|14@1+ (0.001,0) [0|16.383] "Ah"  HVESP01
 SG_ HVESP01_estOcv_156_2 m38: 50|14@1+ (0.001,0) [0|16.383] "Ah"  HVESP01
 SG_ HVESP01_estOcv_157_2 m39: 8|14@1+ (0.001,0) [0|16.383] "Ah"  HVESP01
 SG_ HVESP01_estOcv_158_2 m39: 22|14@1+ (0.001,0) [0|16.383] "Ah"  HVESP01
 SG_ HVESP01_estOcv_159_2 m39: 36|14@1+ (0.001,0) [0|16.383] "Ah"  HVESP01
 SG_ HVESP01_estOcv_160_2 m39: 50|14@1+ (0.001,0) [0|16.383] "Ah"  HVESP01
 SG_ HVESP01_estOcv_161_2 m40: 8|14@1+ (0.001,0) [0|16.383] "Ah"  HVESP01
 SG_ HVESP01_estOcv_162_2 m40: 22|14@1+ (0.001,0) [0|16.383] "Ah"  HVESP01
 SG_ HVESP01_estOcv_163_2 m40: 36|14@1+ (0.001,0) [0|16.383] "Ah"  HVESP01
 SG_ HVESP01_estOcv_164_2 m40: 50|14@1+ (0.001,0) [0|16.383] "Ah"  HVESP01
 SG_ HVESP01_estOcv_165_2 m41: 8|14@1+ (0.001,0) [0|16.383] "Ah"  HVESP01
 SG_ HVESP01_estOcv_166_2 m41: 22|14@1+ (0.001,0) [0|16.383] "Ah"  HVESP01
 SG_ HVESP01_estOcv_167_2 m41: 36|14@1+ (0.001,0) [0|16.383] "Ah"  HVESP01
 SG_ HVESP01_estOcv_168_2 m41: 50|14@1+ (0.001,0) [0|16.383] "Ah"  HVESP01
 SG_ HVESP01_estOcv_169_2 m42: 8|14@1+ (0.001,0) [0|16.383] "Ah"  HVESP01
 SG_ HVESP01_estOcv_170_2 m42: 22|14@1+ (0.001,0) [0|16.383] "Ah"  HVESP01
 SG_ HVESP01_estOcv_171_2 m42: 36|14@1+ (0.001,0) [0|16.383] "Ah"  HVESP01
 SG_ HVESP01_estOcv_172_2 m42: 50|14@1+ (0.001,0) [0|16.383] "Ah"  HVESP01
 SG_ HVESP01_estOcv_173_2 m43: 8|14@1+ (0.001,0) [0|16.383] "Ah"  HVESP01
 SG_ HVESP01_estOcv_174_2 m43: 22|14@1+ (0.001,0) [0|16.383] "Ah"  HVESP01
 SG_ HVESP01_estOcv_175_2 m43: 36|14@1+ (0.001,0) [0|16.383] "Ah"  HVESP01
 SG_ HVESP01_estOcv_176_2 m43: 50|14@1+ (0.001,0) [0|16.383] "Ah"  HVESP01
 SG_ HVESP01_estOcv_177_2 m44: 8|14@1+ (0.001,0) [0|16.383] "Ah"  HVESP01
 SG_ HVESP01_estOcv_178_2 m44: 22|14@1+ (0.001,0) [0|16.383] "Ah"  HVESP01
 SG_ HVESP01_estOcv_179_2 m44: 36|14@1+ (0.001,0) [0|16.383] "Ah"  HVESP01
 SG_ HVESP01_estOcv_180_2 m44: 50|14@1+ (0.001,0) [0|16.383] "Ah"  HVESP01
 SG_ HVESP01_estOcv_181_2 m45: 8|14@1+ (0.001,0) [0|16.383] "Ah"  HVESP01
 SG_ HVESP01_estOcv_182_2 m45: 22|14@1+ (0.001,0) [0|16.383] "Ah"  HVESP01
 SG_ HVESP01_estOcv_183_2 m45: 36|14@1+ (0.001,0) [0|16.383] "Ah"  HVESP01
 SG_ HVESP01_estOcv_184_2 m45: 50|14@1+ (0.001,0) [0|16.383] "Ah"  HVESP01
 SG_ HVESP01_estOcv_185_2 m46: 8|14@1+ (0.001,0) [0|16.383] "Ah"  HVESP01
 SG_ HVESP01_estOcv_186_2 m46: 22|14@1+ (0.001,0) [0|16.383] "Ah"  HVESP01
 SG_ HVESP01_estOcv_187_2 m46: 36|14@1+ (0.001,0) [0|16.383] "Ah"  HVESP01
 SG_ HVESP01_estOcv_188_2 m46: 50|14@1+ (0.001,0) [0|16.383] "Ah"  HVESP01
 SG_ HVESP01_estOcv_189_2 m47: 8|14@1+ (0.001,0) [0|16.383] "Ah"  HVESP01
 SG_ HVESP01_estOcv_190_2 m47: 22|14@1+ (0.001,0) [0|16.383] "Ah"  HVESP01
 SG_ HVESP01_estOcv_191_2 m47: 36|14@1+ (0.001,0) [0|16.383] "Ah"  HVESP01
 SG_ HVESP01_estOcv_192_2 m47: 50|14@1+ (0.001,0) [0|16.383] "Ah"  HVESP01
 SG_ multiplexoreo_2 M: 0|8@1+ (1,0) [0|255] ""  HVESP01

BO_ 2499750247 HVESP01_EstOcv_3: 8 HVESP01
 SG_ HVESP01_estOcv_01_3 m0: 8|14@1+ (0.001,0) [0|16.383] "Ah"  HVESP01
 SG_ HVESP01_estOcv_02_3 m0: 22|14@1+ (0.001,0) [0|16.383] "Ah"  HVESP01
 SG_ HVESP01_estOcv_03_3 m0: 36|14@1+ (0.001,0) [0|16.383] "Ah"  HVESP01
 SG_ HVESP01_estOcv_04_3 m0: 50|14@1+ (0.001,0) [0|16.383] "Ah"  HVESP01
 SG_ HVESP01_estOcv_05_3 m1: 8|14@1+ (0.001,0) [0|16.383] "Ah"  HVESP01
 SG_ HVESP01_estOcv_06_3 m1: 22|14@1+ (0.001,0) [0|16.383] "Ah"  HVESP01
 SG_ HVESP01_estOcv_07_3 m1: 36|14@1+ (0.001,0) [0|16.383] "Ah"  HVESP01
 SG_ HVESP01_estOcv_08_3 m1: 50|14@1+ (0.001,0) [0|16.383] "Ah"  HVESP01
 SG_ HVESP01_estOcv_09_3 m2: 8|14@1+ (0.001,0) [0|16.383] "Ah"  HVESP01
 SG_ HVESP01_estOcv_10_3 m2: 22|14@1+ (0.001,0) [0|16.383] "Ah"  HVESP01
 SG_ HVESP01_estOcv_11_3 m2: 36|14@1+ (0.001,0) [0|16.383] "Ah"  HVESP01
 SG_ HVESP01_estOcv_12_3 m2: 50|14@1+ (0.001,0) [0|16.383] "Ah"  HVESP01
 SG_ HVESP01_estOcv_13_3 m3: 8|14@1+ (0.001,0) [0|16.383] "Ah"  HVESP01
 SG_ HVESP01_estOcv_14_3 m3: 22|14@1+ (0.001,0) [0|16.383] "Ah"  HVESP01
 SG_ HVESP01_estOcv_15_3 m3: 36|14@1+ (0.001,0) [0|16.383] "Ah"  HVESP01
 SG_ HVESP01_estOcv_16_3 m3: 50|14@1+ (0.001,0) [0|16.383] "Ah"  HVESP01
 SG_ HVESP01_estOcv_17_3 m4: 8|14@1+ (0.001,0) [0|16.383] "Ah"  HVESP01
 SG_ HVESP01_estOcv_18_3 m4: 22|14@1+ (0.001,0) [0|16.383] "Ah"  HVESP01
 SG_ HVESP01_estOcv_19_3 m4: 36|14@1+ (0.001,0) [0|16.383] "Ah"  HVESP01
 SG_ HVESP01_estOcv_20_3 m4: 50|14@1+ (0.001,0) [0|16.383] "Ah"  HVESP01
 SG_ HVESP01_estOcv_21_3 m5: 8|14@1+ (0.001,0) [0|16.383] "Ah"  HVESP01
 SG_ HVESP01_estOcv_22_3 m5: 22|14@1+ (0.001,0) [0|16.383] "Ah"  HVESP01
 SG_ HVESP01_estOcv_23_3 m5: 36|14@1+ (0.001,0) [0|16.383] "Ah"  HVESP01
 SG_ HVESP01_estOcv_24_3 m5: 50|14@1+ (0.001,0) [0|16.383] "Ah"  HVESP01
 SG_ HVESP01_estOcv_25_3 m6: 8|14@1+ (0.001,0) [0|16.383] "Ah"  HVESP01
 SG_ HVESP01_estOcv_26_3 m6: 22|14@1+ (0.001,0) [0|16.383] "Ah"  HVESP01
 SG_ HVESP01_estOcv_27_3 m6: 36|14@1+ (0.001,0) [0|16.383] "Ah"  HVESP01
 SG_ HVESP01_estOcv_28_3 m6: 50|14@1+ (0.001,0) [0|16.383] "Ah"  HVESP01
 SG_ HVESP01_estOcv_29_3 m7: 8|14@1+ (0.001,0) [0|16.383] "Ah"  HVESP01
 SG_ HVESP01_estOcv_30_3 m7: 22|14@1+ (0.001,0) [0|16.383] "Ah"  HVESP01
 SG_ HVESP01_estOcv_31_3 m7: 36|14@1+ (0.001,0) [0|16.383] "Ah"  HVESP01
 SG_ HVESP01_estOcv_32_3 m7: 50|14@1+ (0.001,0) [0|16.383] "Ah"  HVESP01
 SG_ HVESP01_estOcv_33_3 m8: 8|14@1+ (0.001,0) [0|16.383] "Ah"  HVESP01
 SG_ HVESP01_estOcv_34_3 m8: 22|14@1+ (0.001,0) [0|16.383] "Ah"  HVESP01
 SG_ HVESP01_estOcv_35_3 m8: 36|14@1+ (0.001,0) [0|16.383] "Ah"  HVESP01
 SG_ HVESP01_estOcv_36_3 m8: 50|14@1+ (0.001,0) [0|16.383] "Ah"  HVESP01
 SG_ HVESP01_estOcv_37_3 m9: 8|14@1+ (0.001,0) [0|16.383] "Ah"  HVESP01
 SG_ HVESP01_estOcv_38_3 m9: 22|14@1+ (0.001,0) [0|16.383] "Ah"  HVESP01
 SG_ HVESP01_estOcv_39_3 m9: 36|14@1+ (0.001,0) [0|16.383] "Ah"  HVESP01
 SG_ HVESP01_estOcv_40_3 m9: 50|14@1+ (0.001,0) [0|16.383] "Ah"  HVESP01
 SG_ HVESP01_estOcv_41_3 m10: 8|14@1+ (0.001,0) [0|16.383] "Ah"  HVESP01
 SG_ HVESP01_estOcv_42_3 m10: 22|14@1+ (0.001,0) [0|16.383] "Ah"  HVESP01
 SG_ HVESP01_estOcv_43_3 m10: 36|14@1+ (0.001,0) [0|16.383] "Ah"  HVESP01
 SG_ HVESP01_estOcv_44_3 m10: 50|14@1+ (0.001,0) [0|16.383] "Ah"  HVESP01
 SG_ HVESP01_estOcv_45_3 m11: 8|14@1+ (0.001,0) [0|16.383] "Ah"  HVESP01
 SG_ HVESP01_estOcv_46_3 m11: 22|14@1+ (0.001,0) [0|16.383] "Ah"  HVESP01
 SG_ HVESP01_estOcv_47_3 m11: 36|14@1+ (0.001,0) [0|16.383] "Ah"  HVESP01
 SG_ HVESP01_estOcv_48_3 m11: 50|14@1+ (0.001,0) [0|16.383] "Ah"  HVESP01
 SG_ HVESP01_estOcv_49_3 m12: 8|14@1+ (0.001,0) [0|16.383] "Ah"  HVESP01
 SG_ HVESP01_estOcv_50_3 m12: 22|14@1+ (0.001,0) [0|16.383] "Ah"  HVESP01
 SG_ HVESP01_estOcv_51_3 m12: 36|14@1+ (0.001,0) [0|16.383] "Ah"  HVESP01
 SG_ HVESP01_estOcv_52_3 m12: 50|14@1+ (0.001,0) [0|16.383] "Ah"  HVESP01
 SG_ HVESP01_estOcv_53_3 m13: 8|14@1+ (0.001,0) [0|16.383] "Ah"  HVESP01
 SG_ HVESP01_estOcv_54_3 m13: 22|14@1+ (0.001,0) [0|16.383] "Ah"  HVESP01
 SG_ HVESP01_estOcv_55_3 m13: 36|14@1+ (0.001,0) [0|16.383] "Ah"  HVESP01
 SG_ HVESP01_estOcv_56_3 m13: 50|14@1+ (0.001,0) [0|16.383] "Ah"  HVESP01
 SG_ HVESP01_estOcv_57_3 m14: 8|14@1+ (0.001,0) [0|16.383] "Ah"  HVESP01
 SG_ HVESP01_estOcv_58_3 m14: 22|14@1+ (0.001,0) [0|16.383] "Ah"  HVESP01
 SG_ HVESP01_estOcv_59_3 m14: 36|14@1+ (0.001,0) [0|16.383] "Ah"  HVESP01
 SG_ HVESP01_estOcv_60_3 m14: 50|14@1+ (0.001,0) [0|16.383] "Ah"  HVESP01
 SG_ HVESP01_estOcv_61_3 m15: 8|14@1+ (0.001,0) [0|16.383] "Ah"  HVESP01
 SG_ HVESP01_estOcv_62_3 m15: 22|14@1+ (0.001,0) [0|16.383] "Ah"  HVESP01
 SG_ HVESP01_estOcv_63_3 m15: 36|14@1+ (0.001,0) [0|16.383] "Ah"  HVESP01
 SG_ HVESP01_estOcv_64_3 m15: 50|14@1+ (0.001,0) [0|16.383] "Ah"  HVESP01
 SG_ HVESP01_estOcv_65_3 m16: 8|14@1+ (0.001,0) [0|16.383] "Ah"  HVESP01
 SG_ HVESP01_estOcv_66_3 m16: 22|14@1+ (0.001,0) [0|16.383] "Ah"  HVESP01
 SG_ HVESP01_estOcv_67_3 m16: 36|14@1+ (0.001,0) [0|16.383] "Ah"  HVESP01
 SG_ HVESP01_estOcv_68_3 m16: 50|14@1+ (0.001,0) [0|16.383] "Ah"  HVESP01
 SG_ HVESP01_estOcv_69_3 m17: 8|14@1+ (0.001,0) [0|16.383] "Ah"  HVESP01
 SG_ HVESP01_estOcv_70_3 m17: 22|14@1+ (0.001,0) [0|16.383] "Ah"  HVESP01
 SG_ HVESP01_estOcv_71_3 m17: 36|14@1+ (0.001,0) [0|16.383] "Ah"  HVESP01
 SG_ HVESP01_estOcv_72_3 m17: 50|14@1+ (0.001,0) [0|16.383] "Ah"  HVESP01
 SG_ HVESP01_estOcv_73_3 m18: 8|14@1+ (0.001,0) [0|16.383] "Ah"  HVESP01
 SG_ HVESP01_estOcv_74_3 m18: 22|14@1+ (0.001,0) [0|16.383] "Ah"  HVESP01
 SG_ HVESP01_estOcv_75_3 m18: 36|14@1+ (0.001,0) [0|16.383] "Ah"  HVESP01
 SG_ HVESP01_estOcv_76_3 m18: 50|14@1+ (0.001,0) [0|16.383] "Ah"  HVESP01
 SG_ HVESP01_estOcv_77_3 m19: 8|14@1+ (0.001,0) [0|16.383] "Ah"  HVESP01
 SG_ HVESP01_estOcv_78_3 m19: 22|14@1+ (0.001,0) [0|16.383] "Ah"  HVESP01
 SG_ HVESP01_estOcv_79_3 m19: 36|14@1+ (0.001,0) [0|16.383] "Ah"  HVESP01
 SG_ HVESP01_estOcv_80_3 m19: 50|14@1+ (0.001,0) [0|16.383] "Ah"  HVESP01
 SG_ HVESP01_estOcv_81_3 m20: 8|14@1+ (0.001,0) [0|16.383] "Ah"  HVESP01
 SG_ HVESP01_estOcv_82_3 m20: 22|14@1+ (0.001,0) [0|16.383] "Ah"  HVESP01
 SG_ HVESP01_estOcv_83_3 m20: 36|14@1+ (0.001,0) [0|16.383] "Ah"  HVESP01
 SG_ HVESP01_estOcv_84_3 m20: 50|14@1+ (0.001,0) [0|16.383] "Ah"  HVESP01
 SG_ HVESP01_estOcv_85_3 m21: 8|14@1+ (0.001,0) [0|16.383] "Ah"  HVESP01
 SG_ HVESP01_estOcv_86_3 m21: 22|14@1+ (0.001,0) [0|16.383] "Ah"  HVESP01
 SG_ HVESP01_estOcv_87_3 m21: 36|14@1+ (0.001,0) [0|16.383] "Ah"  HVESP01
 SG_ HVESP01_estOcv_88_3 m21: 50|14@1+ (0.001,0) [0|16.383] "Ah"  HVESP01
 SG_ HVESP01_estOcv_89_3 m22: 8|14@1+ (0.001,0) [0|16.383] "Ah"  HVESP01
 SG_ HVESP01_estOcv_90_3 m22: 22|14@1+ (0.001,0) [0|16.383] "Ah"  HVESP01
 SG_ HVESP01_estOcv_91_3 m22: 36|14@1+ (0.001,0) [0|16.383] "Ah"  HVESP01
 SG_ HVESP01_estOcv_92_3 m22: 50|14@1+ (0.001,0) [0|16.383] "Ah"  HVESP01
 SG_ HVESP01_estOcv_93_3 m23: 8|14@1+ (0.001,0) [0|16.383] "Ah"  HVESP01
 SG_ HVESP01_estOcv_94_3 m23: 22|14@1+ (0.001,0) [0|16.383] "Ah"  HVESP01
 SG_ HVESP01_estOcv_95_3 m23: 36|14@1+ (0.001,0) [0|16.383] "Ah"  HVESP01
 SG_ HVESP01_estOcv_96_3 m23: 50|14@1+ (0.001,0) [0|16.383] "Ah"  HVESP01
 SG_ HVESP01_estOcv_97_3 m24: 8|14@1+ (0.001,0) [0|16.383] "Ah"  HVESP01
 SG_ HVESP01_estOcv_98_3 m24: 22|14@1+ (0.001,0) [0|16.383] "Ah"  HVESP01
 SG_ HVESP01_estOcv_99_3 m24: 36|14@1+ (0.001,0) [0|16.383] "Ah"  HVESP01
 SG_ HVESP01_estOcv_100_3 m24: 50|14@1+ (0.001,0) [0|16.383] "Ah"  HVESP01
 SG_ HVESP01_estOcv_101_3 m25: 8|14@1+ (0.001,0) [0|16.383] "Ah"  HVESP01
 SG_ HVESP01_estOcv_102_3 m25: 22|14@1+ (0.001,0) [0|16.383] "Ah"  HVESP01
 SG_ HVESP01_estOcv_103_3 m25: 36|14@1+ (0.001,0) [0|16.383] "Ah"  HVESP01
 SG_ HVESP01_estOcv_104_3 m25: 50|14@1+ (0.001,0) [0|16.383] "Ah"  HVESP01
 SG_ HVESP01_estOcv_105_3 m26: 8|14@1+ (0.001,0) [0|16.383] "Ah"  HVESP01
 SG_ HVESP01_estOcv_106_3 m26: 22|14@1+ (0.001,0) [0|16.383] "Ah"  HVESP01
 SG_ HVESP01_estOcv_107_3 m26: 36|14@1+ (0.001,0) [0|16.383] "Ah"  HVESP01
 SG_ HVESP01_estOcv_108_3 m26: 50|14@1+ (0.001,0) [0|16.383] "Ah"  HVESP01
 SG_ HVESP01_estOcv_109_3 m27: 8|14@1+ (0.001,0) [0|16.383] "Ah"  HVESP01
 SG_ HVESP01_estOcv_110_3 m27: 22|14@1+ (0.001,0) [0|16.383] "Ah"  HVESP01
 SG_ HVESP01_estOcv_111_3 m27: 36|14@1+ (0.001,0) [0|16.383] "Ah"  HVESP01
 SG_ HVESP01_estOcv_112_3 m27: 50|14@1+ (0.001,0) [0|16.383] "Ah"  HVESP01
 SG_ HVESP01_estOcv_113_3 m28: 8|14@1+ (0.001,0) [0|16.383] "Ah"  HVESP01
 SG_ HVESP01_estOcv_114_3 m28: 22|14@1+ (0.001,0) [0|16.383] "Ah"  HVESP01
 SG_ HVESP01_estOcv_115_3 m28: 36|14@1+ (0.001,0) [0|16.383] "Ah"  HVESP01
 SG_ HVESP01_estOcv_116_3 m28: 50|14@1+ (0.001,0) [0|16.383] "Ah"  HVESP01
 SG_ HVESP01_estOcv_117_3 m29: 8|14@1+ (0.001,0) [0|16.383] "Ah"  HVESP01
 SG_ HVESP01_estOcv_118_3 m29: 22|14@1+ (0.001,0) [0|16.383] "Ah"  HVESP01
 SG_ HVESP01_estOcv_119_3 m29: 36|14@1+ (0.001,0) [0|16.383] "Ah"  HVESP01
 SG_ HVESP01_estOcv_120_3 m29: 50|14@1+ (0.001,0) [0|16.383] "Ah"  HVESP01
 SG_ HVESP01_estOcv_121_3 m30: 8|14@1+ (0.001,0) [0|16.383] "Ah"  HVESP01
 SG_ HVESP01_estOcv_122_3 m30: 22|14@1+ (0.001,0) [0|16.383] "Ah"  HVESP01
 SG_ HVESP01_estOcv_123_3 m30: 36|14@1+ (0.001,0) [0|16.383] "Ah"  HVESP01
 SG_ HVESP01_estOcv_124_3 m30: 50|14@1+ (0.001,0) [0|16.383] "Ah"  HVESP01
 SG_ HVESP01_estOcv_125_3 m31: 8|14@1+ (0.001,0) [0|16.383] "Ah"  HVESP01
 SG_ HVESP01_estOcv_126_3 m31: 22|14@1+ (0.001,0) [0|16.383] "Ah"  HVESP01
 SG_ HVESP01_estOcv_127_3 m31: 36|14@1+ (0.001,0) [0|16.383] "Ah"  HVESP01
 SG_ HVESP01_estOcv_128_3 m31: 50|14@1+ (0.001,0) [0|16.383] "Ah"  HVESP01
 SG_ HVESP01_estOcv_129_3 m32: 8|14@1+ (0.001,0) [0|16.383] "Ah"  HVESP01
 SG_ HVESP01_estOcv_130_3 m32: 22|14@1+ (0.001,0) [0|16.383] "Ah"  HVESP01
 SG_ HVESP01_estOcv_131_3 m32: 36|14@1+ (0.001,0) [0|16.383] "Ah"  HVESP01
 SG_ HVESP01_estOcv_132_3 m32: 50|14@1+ (0.001,0) [0|16.383] "Ah"  HVESP01
 SG_ HVESP01_estOcv_133_3 m33: 8|14@1+ (0.001,0) [0|16.383] "Ah"  HVESP01
 SG_ HVESP01_estOcv_134_3 m33: 22|14@1+ (0.001,0) [0|16.383] "Ah"  HVESP01
 SG_ HVESP01_estOcv_135_3 m33: 36|14@1+ (0.001,0) [0|16.383] "Ah"  HVESP01
 SG_ HVESP01_estOcv_136_3 m33: 50|14@1+ (0.001,0) [0|16.383] "Ah"  HVESP01
 SG_ HVESP01_estOcv_137_3 m34: 8|14@1+ (0.001,0) [0|16.383] "Ah"  HVESP01
 SG_ HVESP01_estOcv_138_3 m34: 22|14@1+ (0.001,0) [0|16.383] "Ah"  HVESP01
 SG_ HVESP01_estOcv_139_3 m34: 36|14@1+ (0.001,0) [0|16.383] "Ah"  HVESP01
 SG_ HVESP01_estOcv_140_3 m34: 50|14@1+ (0.001,0) [0|16.383] "Ah"  HVESP01
 SG_ HVESP01_estOcv_141_3 m35: 8|14@1+ (0.001,0) [0|16.383] "Ah"  HVESP01
 SG_ HVESP01_estOcv_142_3 m35: 22|14@1+ (0.001,0) [0|16.383] "Ah"  HVESP01
 SG_ HVESP01_estOcv_143_3 m35: 36|14@1+ (0.001,0) [0|16.383] "Ah"  HVESP01
 SG_ HVESP01_estOcv_144_3 m35: 50|14@1+ (0.001,0) [0|16.383] "Ah"  HVESP01
 SG_ HVESP01_estOcv_145_3 m36: 8|14@1+ (0.001,0) [0|16.383] "Ah"  HVESP01
 SG_ HVESP01_estOcv_146_3 m36: 22|14@1+ (0.001,0) [0|16.383] "Ah"  HVESP01
 SG_ HVESP01_estOcv_147_3 m36: 36|14@1+ (0.001,0) [0|16.383] "Ah"  HVESP01
 SG_ HVESP01_estOcv_148_3 m36: 50|14@1+ (0.001,0) [0|16.383] "Ah"  HVESP01
 SG_ HVESP01_estOcv_149_3 m37: 8|14@1+ (0.001,0) [0|16.383] "Ah"  HVESP01
 SG_ HVESP01_estOcv_150_3 m37: 22|14@1+ (0.001,0) [0|16.383] "Ah"  HVESP01
 SG_ HVESP01_estOcv_151_3 m37: 36|14@1+ (0.001,0) [0|16.383] "Ah"  HVESP01
 SG_ HVESP01_estOcv_152_3 m37: 50|14@1+ (0.001,0) [0|16.383] "Ah"  HVESP01
 SG_ HVESP01_estOcv_153_3 m38: 8|14@1+ (0.001,0) [0|16.383] "Ah"  HVESP01
 SG_ HVESP01_estOcv_154_3 m38: 22|14@1+ (0.001,0) [0|16.383] "Ah"  HVESP01
 SG_ HVESP01_estOcv_155_3 m38: 36|14@1+ (0.001,0) [0|16.383] "Ah"  HVESP01
 SG_ HVESP01_estOcv_156_3 m38: 50|14@1+ (0.001,0) [0|16.383] "Ah"  HVESP01
 SG_ HVESP01_estOcv_157_3 m39: 8|14@1+ (0.001,0) [0|16.383] "Ah"  HVESP01
 SG_ HVESP01_estOcv_158_3 m39: 22|14@1+ (0.001,0) [0|16.383] "Ah"  HVESP01
 SG_ HVESP01_estOcv_159_3 m39: 36|14@1+ (0.001,0) [0|16.383] "Ah"  HVESP01
 SG_ HVESP01_estOcv_160_3 m39: 50|14@1+ (0.001,0) [0|16.383] "Ah"  HVESP01
 SG_ HVESP01_estOcv_161_3 m40: 8|14@1+ (0.001,0) [0|16.383] "Ah"  HVESP01
 SG_ HVESP01_estOcv_162_3 m40: 22|14@1+ (0.001,0) [0|16.383] "Ah"  HVESP01
 SG_ HVESP01_estOcv_163_3 m40: 36|14@1+ (0.001,0) [0|16.383] "Ah"  HVESP01
 SG_ HVESP01_estOcv_164_3 m40: 50|14@1+ (0.001,0) [0|16.383] "Ah"  HVESP01
 SG_ HVESP01_estOcv_165_3 m41: 8|14@1+ (0.001,0) [0|16.383] "Ah"  HVESP01
 SG_ HVESP01_estOcv_166_3 m41: 22|14@1+ (0.001,0) [0|16.383] "Ah"  HVESP01
 SG_ HVESP01_estOcv_167_3 m41: 36|14@1+ (0.001,0) [0|16.383] "Ah"  HVESP01
 SG_ HVESP01_estOcv_168_3 m41: 50|14@1+ (0.001,0) [0|16.383] "Ah"  HVESP01
 SG_ HVESP01_estOcv_169_3 m42: 8|14@1+ (0.001,0) [0|16.383] "Ah"  HVESP01
 SG_ HVESP01_estOcv_170_3 m42: 22|14@1+ (0.001,0) [0|16.383] "Ah"  HVESP01
 SG_ HVESP01_estOcv_171_3 m42: 36|14@1+ (0.001,0) [0|16.383] "Ah"  HVESP01
 SG_ HVESP01_estOcv_172_3 m42: 50|14@1+ (0.001,0) [0|16.383] "Ah"  HVESP01
 SG_ HVESP01_estOcv_173_3 m43: 8|14@1+ (0.001,0) [0|16.383] "Ah"  HVESP01
 SG_ HVESP01_estOcv_174_3 m43: 22|14@1+ (0.001,0) [0|16.383] "Ah"  HVESP01
 SG_ HVESP01_estOcv_175_3 m43: 36|14@1+ (0.001,0) [0|16.383] "Ah"  HVESP01
 SG_ HVESP01_estOcv_176_3 m43: 50|14@1+ (0.001,0) [0|16.383] "Ah"  HVESP01
 SG_ HVESP01_estOcv_177_3 m44: 8|14@1+ (0.001,0) [0|16.383] "Ah"  HVESP01
 SG_ HVESP01_estOcv_178_3 m44: 22|14@1+ (0.001,0) [0|16.383] "Ah"  HVESP01
 SG_ HVESP01_estOcv_179_3 m44: 36|14@1+ (0.001,0) [0|16.383] "Ah"  HVESP01
 SG_ HVESP01_estOcv_180_3 m44: 50|14@1+ (0.001,0) [0|16.383] "Ah"  HVESP01
 SG_ HVESP01_estOcv_181_3 m45: 8|14@1+ (0.001,0) [0|16.383] "Ah"  HVESP01
 SG_ HVESP01_estOcv_182_3 m45: 22|14@1+ (0.001,0) [0|16.383] "Ah"  HVESP01
 SG_ HVESP01_estOcv_183_3 m45: 36|14@1+ (0.001,0) [0|16.383] "Ah"  HVESP01
 SG_ HVESP01_estOcv_184_3 m45: 50|14@1+ (0.001,0) [0|16.383] "Ah"  HVESP01
 SG_ HVESP01_estOcv_185_3 m46: 8|14@1+ (0.001,0) [0|16.383] "Ah"  HVESP01
 SG_ HVESP01_estOcv_186_3 m46: 22|14@1+ (0.001,0) [0|16.383] "Ah"  HVESP01
 SG_ HVESP01_estOcv_187_3 m46: 36|14@1+ (0.001,0) [0|16.383] "Ah"  HVESP01
 SG_ HVESP01_estOcv_188_3 m46: 50|14@1+ (0.001,0) [0|16.383] "Ah"  HVESP01
 SG_ HVESP01_estOcv_189_3 m47: 8|14@1+ (0.001,0) [0|16.383] "Ah"  HVESP01
 SG_ HVESP01_estOcv_190_3 m47: 22|14@1+ (0.001,0) [0|16.383] "Ah"  HVESP01
 SG_ HVESP01_estOcv_191_3 m47: 36|14@1+ (0.001,0) [0|16.383] "Ah"  HVESP01
 SG_ HVESP01_estOcv_192_3 m47: 50|14@1+ (0.001,0) [0|16.383] "Ah"  HVESP01
 SG_ multiplexoreo_3 M: 0|8@1+ (1,0) [0|255] ""  HVESP01

BO_ 2499750248 HVESP01_EstOcv_4: 8 HVESP01
 SG_ HVESP01_estOcv_01_4 m0: 8|14@1+ (0.001,0) [0|16.383] "Ah"  HVESP01
 SG_ HVESP01_estOcv_02_4 m0: 22|14@1+ (0.001,0) [0|16.383] "Ah"  HVESP01
 SG_ HVESP01_estOcv_03_4 m0: 36|14@1+ (0.001,0) [0|16.383] "Ah"  HVESP01
 SG_ HVESP01_estOcv_04_4 m0: 50|14@1+ (0.001,0) [0|16.383] "Ah"  HVESP01
 SG_ HVESP01_estOcv_05_4 m1: 8|14@1+ (0.001,0) [0|16.383] "Ah"  HVESP01
 SG_ HVESP01_estOcv_06_4 m1: 22|14@1+ (0.001,0) [0|16.383] "Ah"  HVESP01
 SG_ HVESP01_estOcv_07_4 m1: 36|14@1+ (0.001,0) [0|16.383] "Ah"  HVESP01
 SG_ HVESP01_estOcv_08_4 m1: 50|14@1+ (0.001,0) [0|16.383] "Ah"  HVESP01
 SG_ HVESP01_estOcv_09_4 m2: 8|14@1+ (0.001,0) [0|16.383] "Ah"  HVESP01
 SG_ HVESP01_estOcv_10_4 m2: 22|14@1+ (0.001,0) [0|16.383] "Ah"  HVESP01
 SG_ HVESP01_estOcv_11_4 m2: 36|14@1+ (0.001,0) [0|16.383] "Ah"  HVESP01
 SG_ HVESP01_estOcv_12_4 m2: 50|14@1+ (0.001,0) [0|16.383] "Ah"  HVESP01
 SG_ HVESP01_estOcv_13_4 m3: 8|14@1+ (0.001,0) [0|16.383] "Ah"  HVESP01
 SG_ HVESP01_estOcv_14_4 m3: 22|14@1+ (0.001,0) [0|16.383] "Ah"  HVESP01
 SG_ HVESP01_estOcv_15_4 m3: 36|14@1+ (0.001,0) [0|16.383] "Ah"  HVESP01
 SG_ HVESP01_estOcv_16_4 m3: 50|14@1+ (0.001,0) [0|16.383] "Ah"  HVESP01
 SG_ HVESP01_estOcv_17_4 m4: 8|14@1+ (0.001,0) [0|16.383] "Ah"  HVESP01
 SG_ HVESP01_estOcv_18_4 m4: 22|14@1+ (0.001,0) [0|16.383] "Ah"  HVESP01
 SG_ HVESP01_estOcv_19_4 m4: 36|14@1+ (0.001,0) [0|16.383] "Ah"  HVESP01
 SG_ HVESP01_estOcv_20_4 m4: 50|14@1+ (0.001,0) [0|16.383] "Ah"  HVESP01
 SG_ HVESP01_estOcv_21_4 m5: 8|14@1+ (0.001,0) [0|16.383] "Ah"  HVESP01
 SG_ HVESP01_estOcv_22_4 m5: 22|14@1+ (0.001,0) [0|16.383] "Ah"  HVESP01
 SG_ HVESP01_estOcv_23_4 m5: 36|14@1+ (0.001,0) [0|16.383] "Ah"  HVESP01
 SG_ HVESP01_estOcv_24_4 m5: 50|14@1+ (0.001,0) [0|16.383] "Ah"  HVESP01
 SG_ HVESP01_estOcv_25_4 m6: 8|14@1+ (0.001,0) [0|16.383] "Ah"  HVESP01
 SG_ HVESP01_estOcv_26_4 m6: 22|14@1+ (0.001,0) [0|16.383] "Ah"  HVESP01
 SG_ HVESP01_estOcv_27_4 m6: 36|14@1+ (0.001,0) [0|16.383] "Ah"  HVESP01
 SG_ HVESP01_estOcv_28_4 m6: 50|14@1+ (0.001,0) [0|16.383] "Ah"  HVESP01
 SG_ HVESP01_estOcv_29_4 m7: 8|14@1+ (0.001,0) [0|16.383] "Ah"  HVESP01
 SG_ HVESP01_estOcv_30_4 m7: 22|14@1+ (0.001,0) [0|16.383] "Ah"  HVESP01
 SG_ HVESP01_estOcv_31_4 m7: 36|14@1+ (0.001,0) [0|16.383] "Ah"  HVESP01
 SG_ HVESP01_estOcv_32_4 m7: 50|14@1+ (0.001,0) [0|16.383] "Ah"  HVESP01
 SG_ HVESP01_estOcv_33_4 m8: 8|14@1+ (0.001,0) [0|16.383] "Ah"  HVESP01
 SG_ HVESP01_estOcv_34_4 m8: 22|14@1+ (0.001,0) [0|16.383] "Ah"  HVESP01
 SG_ HVESP01_estOcv_35_4 m8: 36|14@1+ (0.001,0) [0|16.383] "Ah"  HVESP01
 SG_ HVESP01_estOcv_36_4 m8: 50|14@1+ (0.001,0) [0|16.383] "Ah"  HVESP01
 SG_ HVESP01_estOcv_37_4 m9: 8|14@1+ (0.001,0) [0|16.383] "Ah"  HVESP01
 SG_ HVESP01_estOcv_38_4 m9: 22|14@1+ (0.001,0) [0|16.383] "Ah"  HVESP01
 SG_ HVESP01_estOcv_39_4 m9: 36|14@1+ (0.001,0) [0|16.383] "Ah"  HVESP01
 SG_ HVESP01_estOcv_40_4 m9: 50|14@1+ (0.001,0) [0|16.383] "Ah"  HVESP01
 SG_ HVESP01_estOcv_41_4 m10: 8|14@1+ (0.001,0) [0|16.383] "Ah"  HVESP01
 SG_ HVESP01_estOcv_42_4 m10: 22|14@1+ (0.001,0) [0|16.383] "Ah"  HVESP01
 SG_ HVESP01_estOcv_43_4 m10: 36|14@1+ (0.001,0) [0|16.383] "Ah"  HVESP01
 SG_ HVESP01_estOcv_44_4 m10: 50|14@1+ (0.001,0) [0|16.383] "Ah"  HVESP01
 SG_ HVESP01_estOcv_45_4 m11: 8|14@1+ (0.001,0) [0|16.383] "Ah"  HVESP01
 SG_ HVESP01_estOcv_46_4 m11: 22|14@1+ (0.001,0) [0|16.383] "Ah"  HVESP01
 SG_ HVESP01_estOcv_47_4 m11: 36|14@1+ (0.001,0) [0|16.383] "Ah"  HVESP01
 SG_ HVESP01_estOcv_48_4 m11: 50|14@1+ (0.001,0) [0|16.383] "Ah"  HVESP01
 SG_ HVESP01_estOcv_49_4 m12: 8|14@1+ (0.001,0) [0|16.383] "Ah"  HVESP01
 SG_ HVESP01_estOcv_50_4 m12: 22|14@1+ (0.001,0) [0|16.383] "Ah"  HVESP01
 SG_ HVESP01_estOcv_51_4 m12: 36|14@1+ (0.001,0) [0|16.383] "Ah"  HVESP01
 SG_ HVESP01_estOcv_52_4 m12: 50|14@1+ (0.001,0) [0|16.383] "Ah"  HVESP01
 SG_ HVESP01_estOcv_53_4 m13: 8|14@1+ (0.001,0) [0|16.383] "Ah"  HVESP01
 SG_ HVESP01_estOcv_54_4 m13: 22|14@1+ (0.001,0) [0|16.383] "Ah"  HVESP01
 SG_ HVESP01_estOcv_55_4 m13: 36|14@1+ (0.001,0) [0|16.383] "Ah"  HVESP01
 SG_ HVESP01_estOcv_56_4 m13: 50|14@1+ (0.001,0) [0|16.383] "Ah"  HVESP01
 SG_ HVESP01_estOcv_57_4 m14: 8|14@1+ (0.001,0) [0|16.383] "Ah"  HVESP01
 SG_ HVESP01_estOcv_58_4 m14: 22|14@1+ (0.001,0) [0|16.383] "Ah"  HVESP01
 SG_ HVESP01_estOcv_59_4 m14: 36|14@1+ (0.001,0) [0|16.383] "Ah"  HVESP01
 SG_ HVESP01_estOcv_60_4 m14: 50|14@1+ (0.001,0) [0|16.383] "Ah"  HVESP01
 SG_ HVESP01_estOcv_61_4 m15: 8|14@1+ (0.001,0) [0|16.383] "Ah"  HVESP01
 SG_ HVESP01_estOcv_62_4 m15: 22|14@1+ (0.001,0) [0|16.383] "Ah"  HVESP01
 SG_ HVESP01_estOcv_63_4 m15: 36|14@1+ (0.001,0) [0|16.383] "Ah"  HVESP01
 SG_ HVESP01_estOcv_64_4 m15: 50|14@1+ (0.001,0) [0|16.383] "Ah"  HVESP01
 SG_ HVESP01_estOcv_65_4 m16: 8|14@1+ (0.001,0) [0|16.383] "Ah"  HVESP01
 SG_ HVESP01_estOcv_66_4 m16: 22|14@1+ (0.001,0) [0|16.383] "Ah"  HVESP01
 SG_ HVESP01_estOcv_67_4 m16: 36|14@1+ (0.001,0) [0|16.383] "Ah"  HVESP01
 SG_ HVESP01_estOcv_68_4 m16: 50|14@1+ (0.001,0) [0|16.383] "Ah"  HVESP01
 SG_ HVESP01_estOcv_69_4 m17: 8|14@1+ (0.001,0) [0|16.383] "Ah"  HVESP01
 SG_ HVESP01_estOcv_70_4 m17: 22|14@1+ (0.001,0) [0|16.383] "Ah"  HVESP01
 SG_ HVESP01_estOcv_71_4 m17: 36|14@1+ (0.001,0) [0|16.383] "Ah"  HVESP01
 SG_ HVESP01_estOcv_72_4 m17: 50|14@1+ (0.001,0) [0|16.383] "Ah"  HVESP01
 SG_ HVESP01_estOcv_73_4 m18: 8|14@1+ (0.001,0) [0|16.383] "Ah"  HVESP01
 SG_ HVESP01_estOcv_74_4 m18: 22|14@1+ (0.001,0) [0|16.383] "Ah"  HVESP01
 SG_ HVESP01_estOcv_75_4 m18: 36|14@1+ (0.001,0) [0|16.383] "Ah"  HVESP01
 SG_ HVESP01_estOcv_76_4 m18: 50|14@1+ (0.001,0) [0|16.383] "Ah"  HVESP01
 SG_ HVESP01_estOcv_77_4 m19: 8|14@1+ (0.001,0) [0|16.383] "Ah"  HVESP01
 SG_ HVESP01_estOcv_78_4 m19: 22|14@1+ (0.001,0) [0|16.383] "Ah"  HVESP01
 SG_ HVESP01_estOcv_79_4 m19: 36|14@1+ (0.001,0) [0|16.383] "Ah"  HVESP01
 SG_ HVESP01_estOcv_80_4 m19: 50|14@1+ (0.001,0) [0|16.383] "Ah"  HVESP01
 SG_ HVESP01_estOcv_81_4 m20: 8|14@1+ (0.001,0) [0|16.383] "Ah"  HVESP01
 SG_ HVESP01_estOcv_82_4 m20: 22|14@1+ (0.001,0) [0|16.383] "Ah"  HVESP01
 SG_ HVESP01_estOcv_83_4 m20: 36|14@1+ (0.001,0) [0|16.383] "Ah"  HVESP01
 SG_ HVESP01_estOcv_84_4 m20: 50|14@1+ (0.001,0) [0|16.383] "Ah"  HVESP01
 SG_ HVESP01_estOcv_85_4 m21: 8|14@1+ (0.001,0) [0|16.383] "Ah"  HVESP01
 SG_ HVESP01_estOcv_86_4 m21: 22|14@1+ (0.001,0) [0|16.383] "Ah"  HVESP01
 SG_ HVESP01_estOcv_87_4 m21: 36|14@1+ (0.001,0) [0|16.383] "Ah"  HVESP01
 SG_ HVESP01_estOcv_88_4 m21: 50|14@1+ (0.001,0) [0|16.383] "Ah"  HVESP01
 SG_ HVESP01_estOcv_89_4 m22: 8|14@1+ (0.001,0) [0|16.383] "Ah"  HVESP01
 SG_ HVESP01_estOcv_90_4 m22: 22|14@1+ (0.001,0) [0|16.383] "Ah"  HVESP01
 SG_ HVESP01_estOcv_91_4 m22: 36|14@1+ (0.001,0) [0|16.383] "Ah"  HVESP01
 SG_ HVESP01_estOcv_92_4 m22: 50|14@1+ (0.001,0) [0|16.383] "Ah"  HVESP01
 SG_ HVESP01_estOcv_93_4 m23: 8|14@1+ (0.001,0) [0|16.383] "Ah"  HVESP01
 SG_ HVESP01_estOcv_94_4 m23: 22|14@1+ (0.001,0) [0|16.383] "Ah"  HVESP01
 SG_ HVESP01_estOcv_95_4 m23: 36|14@1+ (0.001,0) [0|16.383] "Ah"  HVESP01
 SG_ HVESP01_estOcv_96_4 m23: 50|14@1+ (0.001,0) [0|16.383] "Ah"  HVESP01
 SG_ HVESP01_estOcv_97_4 m24: 8|14@1+ (0.001,0) [0|16.383] "Ah"  HVESP01
 SG_ HVESP01_estOcv_98_4 m24: 22|14@1+ (0.001,0) [0|16.383] "Ah"  HVESP01
 SG_ HVESP01_estOcv_99_4 m24: 36|14@1+ (0.001,0) [0|16.383] "Ah"  HVESP01
 SG_ HVESP01_estOcv_100_4 m24: 50|14@1+ (0.001,0) [0|16.383] "Ah"  HVESP01
 SG_ HVESP01_estOcv_101_4 m25: 8|14@1+ (0.001,0) [0|16.383] "Ah"  HVESP01
 SG_ HVESP01_estOcv_102_4 m25: 22|14@1+ (0.001,0) [0|16.383] "Ah"  HVESP01
 SG_ HVESP01_estOcv_103_4 m25: 36|14@1+ (0.001,0) [0|16.383] "Ah"  HVESP01
 SG_ HVESP01_estOcv_104_4 m25: 50|14@1+ (0.001,0) [0|16.383] "Ah"  HVESP01
 SG_ HVESP01_estOcv_105_4 m26: 8|14@1+ (0.001,0) [0|16.383] "Ah"  HVESP01
 SG_ HVESP01_estOcv_106_4 m26: 22|14@1+ (0.001,0) [0|16.383] "Ah"  HVESP01
 SG_ HVESP01_estOcv_107_4 m26: 36|14@1+ (0.001,0) [0|16.383] "Ah"  HVESP01
 SG_ HVESP01_estOcv_108_4 m26: 50|14@1+ (0.001,0) [0|16.383] "Ah"  HVESP01
 SG_ HVESP01_estOcv_109_4 m27: 8|14@1+ (0.001,0) [0|16.383] "Ah"  HVESP01
 SG_ HVESP01_estOcv_110_4 m27: 22|14@1+ (0.001,0) [0|16.383] "Ah"  HVESP01
 SG_ HVESP01_estOcv_111_4 m27: 36|14@1+ (0.001,0) [0|16.383] "Ah"  HVESP01
 SG_ HVESP01_estOcv_112_4 m27: 50|14@1+ (0.001,0) [0|16.383] "Ah"  HVESP01
 SG_ HVESP01_estOcv_113_4 m28: 8|14@1+ (0.001,0) [0|16.383] "Ah"  HVESP01
 SG_ HVESP01_estOcv_114_4 m28: 22|14@1+ (0.001,0) [0|16.383] "Ah"  HVESP01
 SG_ HVESP01_estOcv_115_4 m28: 36|14@1+ (0.001,0) [0|16.383] "Ah"  HVESP01
 SG_ HVESP01_estOcv_116_4 m28: 50|14@1+ (0.001,0) [0|16.383] "Ah"  HVESP01
 SG_ HVESP01_estOcv_117_4 m29: 8|14@1+ (0.001,0) [0|16.383] "Ah"  HVESP01
 SG_ HVESP01_estOcv_118_4 m29: 22|14@1+ (0.001,0) [0|16.383] "Ah"  HVESP01
 SG_ HVESP01_estOcv_119_4 m29: 36|14@1+ (0.001,0) [0|16.383] "Ah"  HVESP01
 SG_ HVESP01_estOcv_120_4 m29: 50|14@1+ (0.001,0) [0|16.383] "Ah"  HVESP01
 SG_ HVESP01_estOcv_121_4 m30: 8|14@1+ (0.001,0) [0|16.383] "Ah"  HVESP01
 SG_ HVESP01_estOcv_122_4 m30: 22|14@1+ (0.001,0) [0|16.383] "Ah"  HVESP01
 SG_ HVESP01_estOcv_123_4 m30: 36|14@1+ (0.001,0) [0|16.383] "Ah"  HVESP01
 SG_ HVESP01_estOcv_124_4 m30: 50|14@1+ (0.001,0) [0|16.383] "Ah"  HVESP01
 SG_ HVESP01_estOcv_125_4 m31: 8|14@1+ (0.001,0) [0|16.383] "Ah"  HVESP01
 SG_ HVESP01_estOcv_126_4 m31: 22|14@1+ (0.001,0) [0|16.383] "Ah"  HVESP01
 SG_ HVESP01_estOcv_127_4 m31: 36|14@1+ (0.001,0) [0|16.383] "Ah"  HVESP01
 SG_ HVESP01_estOcv_128_4 m31: 50|14@1+ (0.001,0) [0|16.383] "Ah"  HVESP01
 SG_ HVESP01_estOcv_129_4 m32: 8|14@1+ (0.001,0) [0|16.383] "Ah"  HVESP01
 SG_ HVESP01_estOcv_130_4 m32: 22|14@1+ (0.001,0) [0|16.383] "Ah"  HVESP01
 SG_ HVESP01_estOcv_131_4 m32: 36|14@1+ (0.001,0) [0|16.383] "Ah"  HVESP01
 SG_ HVESP01_estOcv_132_4 m32: 50|14@1+ (0.001,0) [0|16.383] "Ah"  HVESP01
 SG_ HVESP01_estOcv_133_4 m33: 8|14@1+ (0.001,0) [0|16.383] "Ah"  HVESP01
 SG_ HVESP01_estOcv_134_4 m33: 22|14@1+ (0.001,0) [0|16.383] "Ah"  HVESP01
 SG_ HVESP01_estOcv_135_4 m33: 36|14@1+ (0.001,0) [0|16.383] "Ah"  HVESP01
 SG_ HVESP01_estOcv_136_4 m33: 50|14@1+ (0.001,0) [0|16.383] "Ah"  HVESP01
 SG_ HVESP01_estOcv_137_4 m34: 8|14@1+ (0.001,0) [0|16.383] "Ah"  HVESP01
 SG_ HVESP01_estOcv_138_4 m34: 22|14@1+ (0.001,0) [0|16.383] "Ah"  HVESP01
 SG_ HVESP01_estOcv_139_4 m34: 36|14@1+ (0.001,0) [0|16.383] "Ah"  HVESP01
 SG_ HVESP01_estOcv_140_4 m34: 50|14@1+ (0.001,0) [0|16.383] "Ah"  HVESP01
 SG_ HVESP01_estOcv_141_4 m35: 8|14@1+ (0.001,0) [0|16.383] "Ah"  HVESP01
 SG_ HVESP01_estOcv_142_4 m35: 22|14@1+ (0.001,0) [0|16.383] "Ah"  HVESP01
 SG_ HVESP01_estOcv_143_4 m35: 36|14@1+ (0.001,0) [0|16.383] "Ah"  HVESP01
 SG_ HVESP01_estOcv_144_4 m35: 50|14@1+ (0.001,0) [0|16.383] "Ah"  HVESP01
 SG_ HVESP01_estOcv_145_4 m36: 8|14@1+ (0.001,0) [0|16.383] "Ah"  HVESP01
 SG_ HVESP01_estOcv_146_4 m36: 22|14@1+ (0.001,0) [0|16.383] "Ah"  HVESP01
 SG_ HVESP01_estOcv_147_4 m36: 36|14@1+ (0.001,0) [0|16.383] "Ah"  HVESP01
 SG_ HVESP01_estOcv_148_4 m36: 50|14@1+ (0.001,0) [0|16.383] "Ah"  HVESP01
 SG_ HVESP01_estOcv_149_4 m37: 8|14@1+ (0.001,0) [0|16.383] "Ah"  HVESP01
 SG_ HVESP01_estOcv_150_4 m37: 22|14@1+ (0.001,0) [0|16.383] "Ah"  HVESP01
 SG_ HVESP01_estOcv_151_4 m37: 36|14@1+ (0.001,0) [0|16.383] "Ah"  HVESP01
 SG_ HVESP01_estOcv_152_4 m37: 50|14@1+ (0.001,0) [0|16.383] "Ah"  HVESP01
 SG_ HVESP01_estOcv_153_4 m38: 8|14@1+ (0.001,0) [0|16.383] "Ah"  HVESP01
 SG_ HVESP01_estOcv_154_4 m38: 22|14@1+ (0.001,0) [0|16.383] "Ah"  HVESP01
 SG_ HVESP01_estOcv_155_4 m38: 36|14@1+ (0.001,0) [0|16.383] "Ah"  HVESP01
 SG_ HVESP01_estOcv_156_4 m38: 50|14@1+ (0.001,0) [0|16.383] "Ah"  HVESP01
 SG_ HVESP01_estOcv_157_4 m39: 8|14@1+ (0.001,0) [0|16.383] "Ah"  HVESP01
 SG_ HVESP01_estOcv_158_4 m39: 22|14@1+ (0.001,0) [0|16.383] "Ah"  HVESP01
 SG_ HVESP01_estOcv_159_4 m39: 36|14@1+ (0.001,0) [0|16.383] "Ah"  HVESP01
 SG_ HVESP01_estOcv_160_4 m39: 50|14@1+ (0.001,0) [0|16.383] "Ah"  HVESP01
 SG_ HVESP01_estOcv_161_4 m40: 8|14@1+ (0.001,0) [0|16.383] "Ah"  HVESP01
 SG_ HVESP01_estOcv_162_4 m40: 22|14@1+ (0.001,0) [0|16.383] "Ah"  HVESP01
 SG_ HVESP01_estOcv_163_4 m40: 36|14@1+ (0.001,0) [0|16.383] "Ah"  HVESP01
 SG_ HVESP01_estOcv_164_4 m40: 50|14@1+ (0.001,0) [0|16.383] "Ah"  HVESP01
 SG_ HVESP01_estOcv_165_4 m41: 8|14@1+ (0.001,0) [0|16.383] "Ah"  HVESP01
 SG_ HVESP01_estOcv_166_4 m41: 22|14@1+ (0.001,0) [0|16.383] "Ah"  HVESP01
 SG_ HVESP01_estOcv_167_4 m41: 36|14@1+ (0.001,0) [0|16.383] "Ah"  HVESP01
 SG_ HVESP01_estOcv_168_4 m41: 50|14@1+ (0.001,0) [0|16.383] "Ah"  HVESP01
 SG_ HVESP01_estOcv_169_4 m42: 8|14@1+ (0.001,0) [0|16.383] "Ah"  HVESP01
 SG_ HVESP01_estOcv_170_4 m42: 22|14@1+ (0.001,0) [0|16.383] "Ah"  HVESP01
 SG_ HVESP01_estOcv_171_4 m42: 36|14@1+ (0.001,0) [0|16.383] "Ah"  HVESP01
 SG_ HVESP01_estOcv_172_4 m42: 50|14@1+ (0.001,0) [0|16.383] "Ah"  HVESP01
 SG_ HVESP01_estOcv_173_4 m43: 8|14@1+ (0.001,0) [0|16.383] "Ah"  HVESP01
 SG_ HVESP01_estOcv_174_4 m43: 22|14@1+ (0.001,0) [0|16.383] "Ah"  HVESP01
 SG_ HVESP01_estOcv_175_4 m43: 36|14@1+ (0.001,0) [0|16.383] "Ah"  HVESP01
 SG_ HVESP01_estOcv_176_4 m43: 50|14@1+ (0.001,0) [0|16.383] "Ah"  HVESP01
 SG_ HVESP01_estOcv_177_4 m44: 8|14@1+ (0.001,0) [0|16.383] "Ah"  HVESP01
 SG_ HVESP01_estOcv_178_4 m44: 22|14@1+ (0.001,0) [0|16.383] "Ah"  HVESP01
 SG_ HVESP01_estOcv_179_4 m44: 36|14@1+ (0.001,0) [0|16.383] "Ah"  HVESP01
 SG_ HVESP01_estOcv_180_4 m44: 50|14@1+ (0.001,0) [0|16.383] "Ah"  HVESP01
 SG_ HVESP01_estOcv_181_4 m45: 8|14@1+ (0.001,0) [0|16.383] "Ah"  HVESP01
 SG_ HVESP01_estOcv_182_4 m45: 22|14@1+ (0.001,0) [0|16.383] "Ah"  HVESP01
 SG_ HVESP01_estOcv_183_4 m45: 36|14@1+ (0.001,0) [0|16.383] "Ah"  HVESP01
 SG_ HVESP01_estOcv_184_4 m45: 50|14@1+ (0.001,0) [0|16.383] "Ah"  HVESP01
 SG_ HVESP01_estOcv_185_4 m46: 8|14@1+ (0.001,0) [0|16.383] "Ah"  HVESP01
 SG_ HVESP01_estOcv_186_4 m46: 22|14@1+ (0.001,0) [0|16.383] "Ah"  HVESP01
 SG_ HVESP01_estOcv_187_4 m46: 36|14@1+ (0.001,0) [0|16.383] "Ah"  HVESP01
 SG_ HVESP01_estOcv_188_4 m46: 50|14@1+ (0.001,0) [0|16.383] "Ah"  HVESP01
 SG_ HVESP01_estOcv_189_4 m47: 8|14@1+ (0.001,0) [0|16.383] "Ah"  HVESP01
 SG_ HVESP01_estOcv_190_4 m47: 22|14@1+ (0.001,0) [0|16.383] "Ah"  HVESP01
 SG_ HVESP01_estOcv_191_4 m47: 36|14@1+ (0.001,0) [0|16.383] "Ah"  HVESP01
 SG_ HVESP01_estOcv_192_4 m47: 50|14@1+ (0.001,0) [0|16.383] "Ah"  HVESP01
 SG_ multiplexoreo_4 M: 0|8@1+ (1,0) [0|255] ""  HVESP01

BO_ 2499750249 HVESP01_EstOcv_5: 8 HVESP01
 SG_ HVESP01_estOcv_01_5 m0: 8|14@1+ (0.001,0) [0|16.383] "Ah"  HVESP01
 SG_ HVESP01_estOcv_02_5 m0: 22|14@1+ (0.001,0) [0|16.383] "Ah"  HVESP01
 SG_ HVESP01_estOcv_03_5 m0: 36|14@1+ (0.001,0) [0|16.383] "Ah"  HVESP01
 SG_ HVESP01_estOcv_04_5 m0: 50|14@1+ (0.001,0) [0|16.383] "Ah"  HVESP01
 SG_ HVESP01_estOcv_05_5 m1: 8|14@1+ (0.001,0) [0|16.383] "Ah"  HVESP01
 SG_ HVESP01_estOcv_06_5 m1: 22|14@1+ (0.001,0) [0|16.383] "Ah"  HVESP01
 SG_ HVESP01_estOcv_07_5 m1: 36|14@1+ (0.001,0) [0|16.383] "Ah"  HVESP01
 SG_ HVESP01_estOcv_08_5 m1: 50|14@1+ (0.001,0) [0|16.383] "Ah"  HVESP01
 SG_ HVESP01_estOcv_09_5 m2: 8|14@1+ (0.001,0) [0|16.383] "Ah"  HVESP01
 SG_ HVESP01_estOcv_10_5 m2: 22|14@1+ (0.001,0) [0|16.383] "Ah"  HVESP01
 SG_ HVESP01_estOcv_11_5 m2: 36|14@1+ (0.001,0) [0|16.383] "Ah"  HVESP01
 SG_ HVESP01_estOcv_12_5 m2: 50|14@1+ (0.001,0) [0|16.383] "Ah"  HVESP01
 SG_ HVESP01_estOcv_13_5 m3: 8|14@1+ (0.001,0) [0|16.383] "Ah"  HVESP01
 SG_ HVESP01_estOcv_14_5 m3: 22|14@1+ (0.001,0) [0|16.383] "Ah"  HVESP01
 SG_ HVESP01_estOcv_15_5 m3: 36|14@1+ (0.001,0) [0|16.383] "Ah"  HVESP01
 SG_ HVESP01_estOcv_16_5 m3: 50|14@1+ (0.001,0) [0|16.383] "Ah"  HVESP01
 SG_ HVESP01_estOcv_17_5 m4: 8|14@1+ (0.001,0) [0|16.383] "Ah"  HVESP01
 SG_ HVESP01_estOcv_18_5 m4: 22|14@1+ (0.001,0) [0|16.383] "Ah"  HVESP01
 SG_ HVESP01_estOcv_19_5 m4: 36|14@1+ (0.001,0) [0|16.383] "Ah"  HVESP01
 SG_ HVESP01_estOcv_20_5 m4: 50|14@1+ (0.001,0) [0|16.383] "Ah"  HVESP01
 SG_ HVESP01_estOcv_21_5 m5: 8|14@1+ (0.001,0) [0|16.383] "Ah"  HVESP01
 SG_ HVESP01_estOcv_22_5 m5: 22|14@1+ (0.001,0) [0|16.383] "Ah"  HVESP01
 SG_ HVESP01_estOcv_23_5 m5: 36|14@1+ (0.001,0) [0|16.383] "Ah"  HVESP01
 SG_ HVESP01_estOcv_24_5 m5: 50|14@1+ (0.001,0) [0|16.383] "Ah"  HVESP01
 SG_ HVESP01_estOcv_25_5 m6: 8|14@1+ (0.001,0) [0|16.383] "Ah"  HVESP01
 SG_ HVESP01_estOcv_26_5 m6: 22|14@1+ (0.001,0) [0|16.383] "Ah"  HVESP01
 SG_ HVESP01_estOcv_27_5 m6: 36|14@1+ (0.001,0) [0|16.383] "Ah"  HVESP01
 SG_ HVESP01_estOcv_28_5 m6: 50|14@1+ (0.001,0) [0|16.383] "Ah"  HVESP01
 SG_ HVESP01_estOcv_29_5 m7: 8|14@1+ (0.001,0) [0|16.383] "Ah"  HVESP01
 SG_ HVESP01_estOcv_30_5 m7: 22|14@1+ (0.001,0) [0|16.383] "Ah"  HVESP01
 SG_ HVESP01_estOcv_31_5 m7: 36|14@1+ (0.001,0) [0|16.383] "Ah"  HVESP01
 SG_ HVESP01_estOcv_32_5 m7: 50|14@1+ (0.001,0) [0|16.383] "Ah"  HVESP01
 SG_ HVESP01_estOcv_33_5 m8: 8|14@1+ (0.001,0) [0|16.383] "Ah"  HVESP01
 SG_ HVESP01_estOcv_34_5 m8: 22|14@1+ (0.001,0) [0|16.383] "Ah"  HVESP01
 SG_ HVESP01_estOcv_35_5 m8: 36|14@1+ (0.001,0) [0|16.383] "Ah"  HVESP01
 SG_ HVESP01_estOcv_36_5 m8: 50|14@1+ (0.001,0) [0|16.383] "Ah"  HVESP01
 SG_ HVESP01_estOcv_37_5 m9: 8|14@1+ (0.001,0) [0|16.383] "Ah"  HVESP01
 SG_ HVESP01_estOcv_38_5 m9: 22|14@1+ (0.001,0) [0|16.383] "Ah"  HVESP01
 SG_ HVESP01_estOcv_39_5 m9: 36|14@1+ (0.001,0) [0|16.383] "Ah"  HVESP01
 SG_ HVESP01_estOcv_40_5 m9: 50|14@1+ (0.001,0) [0|16.383] "Ah"  HVESP01
 SG_ HVESP01_estOcv_41_5 m10: 8|14@1+ (0.001,0) [0|16.383] "Ah"  HVESP01
 SG_ HVESP01_estOcv_42_5 m10: 22|14@1+ (0.001,0) [0|16.383] "Ah"  HVESP01
 SG_ HVESP01_estOcv_43_5 m10: 36|14@1+ (0.001,0) [0|16.383] "Ah"  HVESP01
 SG_ HVESP01_estOcv_44_5 m10: 50|14@1+ (0.001,0) [0|16.383] "Ah"  HVESP01
 SG_ HVESP01_estOcv_45_5 m11: 8|14@1+ (0.001,0) [0|16.383] "Ah"  HVESP01
 SG_ HVESP01_estOcv_46_5 m11: 22|14@1+ (0.001,0) [0|16.383] "Ah"  HVESP01
 SG_ HVESP01_estOcv_47_5 m11: 36|14@1+ (0.001,0) [0|16.383] "Ah"  HVESP01
 SG_ HVESP01_estOcv_48_5 m11: 50|14@1+ (0.001,0) [0|16.383] "Ah"  HVESP01
 SG_ HVESP01_estOcv_49_5 m12: 8|14@1+ (0.001,0) [0|16.383] "Ah"  HVESP01
 SG_ HVESP01_estOcv_50_5 m12: 22|14@1+ (0.001,0) [0|16.383] "Ah"  HVESP01
 SG_ HVESP01_estOcv_51_5 m12: 36|14@1+ (0.001,0) [0|16.383] "Ah"  HVESP01
 SG_ HVESP01_estOcv_52_5 m12: 50|14@1+ (0.001,0) [0|16.383] "Ah"  HVESP01
 SG_ HVESP01_estOcv_53_5 m13: 8|14@1+ (0.001,0) [0|16.383] "Ah"  HVESP01
 SG_ HVESP01_estOcv_54_5 m13: 22|14@1+ (0.001,0) [0|16.383] "Ah"  HVESP01
 SG_ HVESP01_estOcv_55_5 m13: 36|14@1+ (0.001,0) [0|16.383] "Ah"  HVESP01
 SG_ HVESP01_estOcv_56_5 m13: 50|14@1+ (0.001,0) [0|16.383] "Ah"  HVESP01
 SG_ HVESP01_estOcv_57_5 m14: 8|14@1+ (0.001,0) [0|16.383] "Ah"  HVESP01
 SG_ HVESP01_estOcv_58_5 m14: 22|14@1+ (0.001,0) [0|16.383] "Ah"  HVESP01
 SG_ HVESP01_estOcv_59_5 m14: 36|14@1+ (0.001,0) [0|16.383] "Ah"  HVESP01
 SG_ HVESP01_estOcv_60_5 m14: 50|14@1+ (0.001,0) [0|16.383] "Ah"  HVESP01
 SG_ HVESP01_estOcv_61_5 m15: 8|14@1+ (0.001,0) [0|16.383] "Ah"  HVESP01
 SG_ HVESP01_estOcv_62_5 m15: 22|14@1+ (0.001,0) [0|16.383] "Ah"  HVESP01
 SG_ HVESP01_estOcv_63_5 m15: 36|14@1+ (0.001,0) [0|16.383] "Ah"  HVESP01
 SG_ HVESP01_estOcv_64_5 m15: 50|14@1+ (0.001,0) [0|16.383] "Ah"  HVESP01
 SG_ HVESP01_estOcv_65_5 m16: 8|14@1+ (0.001,0) [0|16.383] "Ah"  HVESP01
 SG_ HVESP01_estOcv_66_5 m16: 22|14@1+ (0.001,0) [0|16.383] "Ah"  HVESP01
 SG_ HVESP01_estOcv_67_5 m16: 36|14@1+ (0.001,0) [0|16.383] "Ah"  HVESP01
 SG_ HVESP01_estOcv_68_5 m16: 50|14@1+ (0.001,0) [0|16.383] "Ah"  HVESP01
 SG_ HVESP01_estOcv_69_5 m17: 8|14@1+ (0.001,0) [0|16.383] "Ah"  HVESP01
 SG_ HVESP01_estOcv_70_5 m17: 22|14@1+ (0.001,0) [0|16.383] "Ah"  HVESP01
 SG_ HVESP01_estOcv_71_5 m17: 36|14@1+ (0.001,0) [0|16.383] "Ah"  HVESP01
 SG_ HVESP01_estOcv_72_5 m17: 50|14@1+ (0.001,0) [0|16.383] "Ah"  HVESP01
 SG_ HVESP01_estOcv_73_5 m18: 8|14@1+ (0.001,0) [0|16.383] "Ah"  HVESP01
 SG_ HVESP01_estOcv_74_5 m18: 22|14@1+ (0.001,0) [0|16.383] "Ah"  HVESP01
 SG_ HVESP01_estOcv_75_5 m18: 36|14@1+ (0.001,0) [0|16.383] "Ah"  HVESP01
 SG_ HVESP01_estOcv_76_5 m18: 50|14@1+ (0.001,0) [0|16.383] "Ah"  HVESP01
 SG_ HVESP01_estOcv_77_5 m19: 8|14@1+ (0.001,0) [0|16.383] "Ah"  HVESP01
 SG_ HVESP01_estOcv_78_5 m19: 22|14@1+ (0.001,0) [0|16.383] "Ah"  HVESP01
 SG_ HVESP01_estOcv_79_5 m19: 36|14@1+ (0.001,0) [0|16.383] "Ah"  HVESP01
 SG_ HVESP01_estOcv_80_5 m19: 50|14@1+ (0.001,0) [0|16.383] "Ah"  HVESP01
 SG_ HVESP01_estOcv_81_5 m20: 8|14@1+ (0.001,0) [0|16.383] "Ah"  HVESP01
 SG_ HVESP01_estOcv_82_5 m20: 22|14@1+ (0.001,0) [0|16.383] "Ah"  HVESP01
 SG_ HVESP01_estOcv_83_5 m20: 36|14@1+ (0.001,0) [0|16.383] "Ah"  HVESP01
 SG_ HVESP01_estOcv_84_5 m20: 50|14@1+ (0.001,0) [0|16.383] "Ah"  HVESP01
 SG_ HVESP01_estOcv_85_5 m21: 8|14@1+ (0.001,0) [0|16.383] "Ah"  HVESP01
 SG_ HVESP01_estOcv_86_5 m21: 22|14@1+ (0.001,0) [0|16.383] "Ah"  HVESP01
 SG_ HVESP01_estOcv_87_5 m21: 36|14@1+ (0.001,0) [0|16.383] "Ah"  HVESP01
 SG_ HVESP01_estOcv_88_5 m21: 50|14@1+ (0.001,0) [0|16.383] "Ah"  HVESP01
 SG_ HVESP01_estOcv_89_5 m22: 8|14@1+ (0.001,0) [0|16.383] "Ah"  HVESP01
 SG_ HVESP01_estOcv_90_5 m22: 22|14@1+ (0.001,0) [0|16.383] "Ah"  HVESP01
 SG_ HVESP01_estOcv_91_5 m22: 36|14@1+ (0.001,0) [0|16.383] "Ah"  HVESP01
 SG_ HVESP01_estOcv_92_5 m22: 50|14@1+ (0.001,0) [0|16.383] "Ah"  HVESP01
 SG_ HVESP01_estOcv_93_5 m23: 8|14@1+ (0.001,0) [0|16.383] "Ah"  HVESP01
 SG_ HVESP01_estOcv_94_5 m23: 22|14@1+ (0.001,0) [0|16.383] "Ah"  HVESP01
 SG_ HVESP01_estOcv_95_5 m23: 36|14@1+ (0.001,0) [0|16.383] "Ah"  HVESP01
 SG_ HVESP01_estOcv_96_5 m23: 50|14@1+ (0.001,0) [0|16.383] "Ah"  HVESP01
 SG_ HVESP01_estOcv_97_5 m24: 8|14@1+ (0.001,0) [0|16.383] "Ah"  HVESP01
 SG_ HVESP01_estOcv_98_5 m24: 22|14@1+ (0.001,0) [0|16.383] "Ah"  HVESP01
 SG_ HVESP01_estOcv_99_5 m24: 36|14@1+ (0.001,0) [0|16.383] "Ah"  HVESP01
 SG_ HVESP01_estOcv_100_5 m24: 50|14@1+ (0.001,0) [0|16.383] "Ah"  HVESP01
 SG_ HVESP01_estOcv_101_5 m25: 8|14@1+ (0.001,0) [0|16.383] "Ah"  HVESP01
 SG_ HVESP01_estOcv_102_5 m25: 22|14@1+ (0.001,0) [0|16.383] "Ah"  HVESP01
 SG_ HVESP01_estOcv_103_5 m25: 36|14@1+ (0.001,0) [0|16.383] "Ah"  HVESP01
 SG_ HVESP01_estOcv_104_5 m25: 50|14@1+ (0.001,0) [0|16.383] "Ah"  HVESP01
 SG_ HVESP01_estOcv_105_5 m26: 8|14@1+ (0.001,0) [0|16.383] "Ah"  HVESP01
 SG_ HVESP01_estOcv_106_5 m26: 22|14@1+ (0.001,0) [0|16.383] "Ah"  HVESP01
 SG_ HVESP01_estOcv_107_5 m26: 36|14@1+ (0.001,0) [0|16.383] "Ah"  HVESP01
 SG_ HVESP01_estOcv_108_5 m26: 50|14@1+ (0.001,0) [0|16.383] "Ah"  HVESP01
 SG_ HVESP01_estOcv_109_5 m27: 8|14@1+ (0.001,0) [0|16.383] "Ah"  HVESP01
 SG_ HVESP01_estOcv_110_5 m27: 22|14@1+ (0.001,0) [0|16.383] "Ah"  HVESP01
 SG_ HVESP01_estOcv_111_5 m27: 36|14@1+ (0.001,0) [0|16.383] "Ah"  HVESP01
 SG_ HVESP01_estOcv_112_5 m27: 50|14@1+ (0.001,0) [0|16.383] "Ah"  HVESP01
 SG_ HVESP01_estOcv_113_5 m28: 8|14@1+ (0.001,0) [0|16.383] "Ah"  HVESP01
 SG_ HVESP01_estOcv_114_5 m28: 22|14@1+ (0.001,0) [0|16.383] "Ah"  HVESP01
 SG_ HVESP01_estOcv_115_5 m28: 36|14@1+ (0.001,0) [0|16.383] "Ah"  HVESP01
 SG_ HVESP01_estOcv_116_5 m28: 50|14@1+ (0.001,0) [0|16.383] "Ah"  HVESP01
 SG_ HVESP01_estOcv_117_5 m29: 8|14@1+ (0.001,0) [0|16.383] "Ah"  HVESP01
 SG_ HVESP01_estOcv_118_5 m29: 22|14@1+ (0.001,0) [0|16.383] "Ah"  HVESP01
 SG_ HVESP01_estOcv_119_5 m29: 36|14@1+ (0.001,0) [0|16.383] "Ah"  HVESP01
 SG_ HVESP01_estOcv_120_5 m29: 50|14@1+ (0.001,0) [0|16.383] "Ah"  HVESP01
 SG_ HVESP01_estOcv_121_5 m30: 8|14@1+ (0.001,0) [0|16.383] "Ah"  HVESP01
 SG_ HVESP01_estOcv_122_5 m30: 22|14@1+ (0.001,0) [0|16.383] "Ah"  HVESP01
 SG_ HVESP01_estOcv_123_5 m30: 36|14@1+ (0.001,0) [0|16.383] "Ah"  HVESP01
 SG_ HVESP01_estOcv_124_5 m30: 50|14@1+ (0.001,0) [0|16.383] "Ah"  HVESP01
 SG_ HVESP01_estOcv_125_5 m31: 8|14@1+ (0.001,0) [0|16.383] "Ah"  HVESP01
 SG_ HVESP01_estOcv_126_5 m31: 22|14@1+ (0.001,0) [0|16.383] "Ah"  HVESP01
 SG_ HVESP01_estOcv_127_5 m31: 36|14@1+ (0.001,0) [0|16.383] "Ah"  HVESP01
 SG_ HVESP01_estOcv_128_5 m31: 50|14@1+ (0.001,0) [0|16.383] "Ah"  HVESP01
 SG_ HVESP01_estOcv_129_5 m32: 8|14@1+ (0.001,0) [0|16.383] "Ah"  HVESP01
 SG_ HVESP01_estOcv_130_5 m32: 22|14@1+ (0.001,0) [0|16.383] "Ah"  HVESP01
 SG_ HVESP01_estOcv_131_5 m32: 36|14@1+ (0.001,0) [0|16.383] "Ah"  HVESP01
 SG_ HVESP01_estOcv_132_5 m32: 50|14@1+ (0.001,0) [0|16.383] "Ah"  HVESP01
 SG_ HVESP01_estOcv_133_5 m33: 8|14@1+ (0.001,0) [0|16.383] "Ah"  HVESP01
 SG_ HVESP01_estOcv_134_5 m33: 22|14@1+ (0.001,0) [0|16.383] "Ah"  HVESP01
 SG_ HVESP01_estOcv_135_5 m33: 36|14@1+ (0.001,0) [0|16.383] "Ah"  HVESP01
 SG_ HVESP01_estOcv_136_5 m33: 50|14@1+ (0.001,0) [0|16.383] "Ah"  HVESP01
 SG_ HVESP01_estOcv_137_5 m34: 8|14@1+ (0.001,0) [0|16.383] "Ah"  HVESP01
 SG_ HVESP01_estOcv_138_5 m34: 22|14@1+ (0.001,0) [0|16.383] "Ah"  HVESP01
 SG_ HVESP01_estOcv_139_5 m34: 36|14@1+ (0.001,0) [0|16.383] "Ah"  HVESP01
 SG_ HVESP01_estOcv_140_5 m34: 50|14@1+ (0.001,0) [0|16.383] "Ah"  HVESP01
 SG_ HVESP01_estOcv_141_5 m35: 8|14@1+ (0.001,0) [0|16.383] "Ah"  HVESP01
 SG_ HVESP01_estOcv_142_5 m35: 22|14@1+ (0.001,0) [0|16.383] "Ah"  HVESP01
 SG_ HVESP01_estOcv_143_5 m35: 36|14@1+ (0.001,0) [0|16.383] "Ah"  HVESP01
 SG_ HVESP01_estOcv_144_5 m35: 50|14@1+ (0.001,0) [0|16.383] "Ah"  HVESP01
 SG_ HVESP01_estOcv_145_5 m36: 8|14@1+ (0.001,0) [0|16.383] "Ah"  HVESP01
 SG_ HVESP01_estOcv_146_5 m36: 22|14@1+ (0.001,0) [0|16.383] "Ah"  HVESP01
 SG_ HVESP01_estOcv_147_5 m36: 36|14@1+ (0.001,0) [0|16.383] "Ah"  HVESP01
 SG_ HVESP01_estOcv_148_5 m36: 50|14@1+ (0.001,0) [0|16.383] "Ah"  HVESP01
 SG_ HVESP01_estOcv_149_5 m37: 8|14@1+ (0.001,0) [0|16.383] "Ah"  HVESP01
 SG_ HVESP01_estOcv_150_5 m37: 22|14@1+ (0.001,0) [0|16.383] "Ah"  HVESP01
 SG_ HVESP01_estOcv_151_5 m37: 36|14@1+ (0.001,0) [0|16.383] "Ah"  HVESP01
 SG_ HVESP01_estOcv_152_5 m37: 50|14@1+ (0.001,0) [0|16.383] "Ah"  HVESP01
 SG_ HVESP01_estOcv_153_5 m38: 8|14@1+ (0.001,0) [0|16.383] "Ah"  HVESP01
 SG_ HVESP01_estOcv_154_5 m38: 22|14@1+ (0.001,0) [0|16.383] "Ah"  HVESP01
 SG_ HVESP01_estOcv_155_5 m38: 36|14@1+ (0.001,0) [0|16.383] "Ah"  HVESP01
 SG_ HVESP01_estOcv_156_5 m38: 50|14@1+ (0.001,0) [0|16.383] "Ah"  HVESP01
 SG_ HVESP01_estOcv_157_5 m39: 8|14@1+ (0.001,0) [0|16.383] "Ah"  HVESP01
 SG_ HVESP01_estOcv_158_5 m39: 22|14@1+ (0.001,0) [0|16.383] "Ah"  HVESP01
 SG_ HVESP01_estOcv_159_5 m39: 36|14@1+ (0.001,0) [0|16.383] "Ah"  HVESP01
 SG_ HVESP01_estOcv_160_5 m39: 50|14@1+ (0.001,0) [0|16.383] "Ah"  HVESP01
 SG_ HVESP01_estOcv_161_5 m40: 8|14@1+ (0.001,0) [0|16.383] "Ah"  HVESP01
 SG_ HVESP01_estOcv_162_5 m40: 22|14@1+ (0.001,0) [0|16.383] "Ah"  HVESP01
 SG_ HVESP01_estOcv_163_5 m40: 36|14@1+ (0.001,0) [0|16.383] "Ah"  HVESP01
 SG_ HVESP01_estOcv_164_5 m40: 50|14@1+ (0.001,0) [0|16.383] "Ah"  HVESP01
 SG_ HVESP01_estOcv_165_5 m41: 8|14@1+ (0.001,0) [0|16.383] "Ah"  HVESP01
 SG_ HVESP01_estOcv_166_5 m41: 22|14@1+ (0.001,0) [0|16.383] "Ah"  HVESP01
 SG_ HVESP01_estOcv_167_5 m41: 36|14@1+ (0.001,0) [0|16.383] "Ah"  HVESP01
 SG_ HVESP01_estOcv_168_5 m41: 50|14@1+ (0.001,0) [0|16.383] "Ah"  HVESP01
 SG_ HVESP01_estOcv_169_5 m42: 8|14@1+ (0.001,0) [0|16.383] "Ah"  HVESP01
 SG_ HVESP01_estOcv_170_5 m42: 22|14@1+ (0.001,0) [0|16.383] "Ah"  HVESP01
 SG_ HVESP01_estOcv_171_5 m42: 36|14@1+ (0.001,0) [0|16.383] "Ah"  HVESP01
 SG_ HVESP01_estOcv_172_5 m42: 50|14@1+ (0.001,0) [0|16.383] "Ah"  HVESP01
 SG_ HVESP01_estOcv_173_5 m43: 8|14@1+ (0.001,0) [0|16.383] "Ah"  HVESP01
 SG_ HVESP01_estOcv_174_5 m43: 22|14@1+ (0.001,0) [0|16.383] "Ah"  HVESP01
 SG_ HVESP01_estOcv_175_5 m43: 36|14@1+ (0.001,0) [0|16.383] "Ah"  HVESP01
 SG_ HVESP01_estOcv_176_5 m43: 50|14@1+ (0.001,0) [0|16.383] "Ah"  HVESP01
 SG_ HVESP01_estOcv_177_5 m44: 8|14@1+ (0.001,0) [0|16.383] "Ah"  HVESP01
 SG_ HVESP01_estOcv_178_5 m44: 22|14@1+ (0.001,0) [0|16.383] "Ah"  HVESP01
 SG_ HVESP01_estOcv_179_5 m44: 36|14@1+ (0.001,0) [0|16.383] "Ah"  HVESP01
 SG_ HVESP01_estOcv_180_5 m44: 50|14@1+ (0.001,0) [0|16.383] "Ah"  HVESP01
 SG_ HVESP01_estOcv_181_5 m45: 8|14@1+ (0.001,0) [0|16.383] "Ah"  HVESP01
 SG_ HVESP01_estOcv_182_5 m45: 22|14@1+ (0.001,0) [0|16.383] "Ah"  HVESP01
 SG_ HVESP01_estOcv_183_5 m45: 36|14@1+ (0.001,0) [0|16.383] "Ah"  HVESP01
 SG_ HVESP01_estOcv_184_5 m45: 50|14@1+ (0.001,0) [0|16.383] "Ah"  HVESP01
 SG_ HVESP01_estOcv_185_5 m46: 8|14@1+ (0.001,0) [0|16.383] "Ah"  HVESP01
 SG_ HVESP01_estOcv_186_5 m46: 22|14@1+ (0.001,0) [0|16.383] "Ah"  HVESP01
 SG_ HVESP01_estOcv_187_5 m46: 36|14@1+ (0.001,0) [0|16.383] "Ah"  HVESP01
 SG_ HVESP01_estOcv_188_5 m46: 50|14@1+ (0.001,0) [0|16.383] "Ah"  HVESP01
 SG_ HVESP01_estOcv_189_5 m47: 8|14@1+ (0.001,0) [0|16.383] "Ah"  HVESP01
 SG_ HVESP01_estOcv_190_5 m47: 22|14@1+ (0.001,0) [0|16.383] "Ah"  HVESP01
 SG_ HVESP01_estOcv_191_5 m47: 36|14@1+ (0.001,0) [0|16.383] "Ah"  HVESP01
 SG_ HVESP01_estOcv_192_5 m47: 50|14@1+ (0.001,0) [0|16.383] "Ah"  HVESP01
 SG_ multiplexoreo_5 M: 0|8@1+ (1,0) [0|255] ""  HVESP01

BO_ 2499750250 HVESP01_EstOcv_6: 8 HVESP01
 SG_ HVESP01_estOcv_01_6 m0: 8|14@1+ (0.001,0) [0|16.383] "Ah"  HVESP01
 SG_ HVESP01_estOcv_02_6 m0: 22|14@1+ (0.001,0) [0|16.383] "Ah"  HVESP01
 SG_ HVESP01_estOcv_03_6 m0: 36|14@1+ (0.001,0) [0|16.383] "Ah"  HVESP01
 SG_ HVESP01_estOcv_04_6 m0: 50|14@1+ (0.001,0) [0|16.383] "Ah"  HVESP01
 SG_ HVESP01_estOcv_05_6 m1: 8|14@1+ (0.001,0) [0|16.383] "Ah"  HVESP01
 SG_ HVESP01_estOcv_06_6 m1: 22|14@1+ (0.001,0) [0|16.383] "Ah"  HVESP01
 SG_ HVESP01_estOcv_07_6 m1: 36|14@1+ (0.001,0) [0|16.383] "Ah"  HVESP01
 SG_ HVESP01_estOcv_08_6 m1: 50|14@1+ (0.001,0) [0|16.383] "Ah"  HVESP01
 SG_ HVESP01_estOcv_09_6 m2: 8|14@1+ (0.001,0) [0|16.383] "Ah"  HVESP01
 SG_ HVESP01_estOcv_10_6 m2: 22|14@1+ (0.001,0) [0|16.383] "Ah"  HVESP01
 SG_ HVESP01_estOcv_11_6 m2: 36|14@1+ (0.001,0) [0|16.383] "Ah"  HVESP01
 SG_ HVESP01_estOcv_12_6 m2: 50|14@1+ (0.001,0) [0|16.383] "Ah"  HVESP01
 SG_ HVESP01_estOcv_13_6 m3: 8|14@1+ (0.001,0) [0|16.383] "Ah"  HVESP01
 SG_ HVESP01_estOcv_14_6 m3: 22|14@1+ (0.001,0) [0|16.383] "Ah"  HVESP01
 SG_ HVESP01_estOcv_15_6 m3: 36|14@1+ (0.001,0) [0|16.383] "Ah"  HVESP01
 SG_ HVESP01_estOcv_16_6 m3: 50|14@1+ (0.001,0) [0|16.383] "Ah"  HVESP01
 SG_ HVESP01_estOcv_17_6 m4: 8|14@1+ (0.001,0) [0|16.383] "Ah"  HVESP01
 SG_ HVESP01_estOcv_18_6 m4: 22|14@1+ (0.001,0) [0|16.383] "Ah"  HVESP01
 SG_ HVESP01_estOcv_19_6 m4: 36|14@1+ (0.001,0) [0|16.383] "Ah"  HVESP01
 SG_ HVESP01_estOcv_20_6 m4: 50|14@1+ (0.001,0) [0|16.383] "Ah"  HVESP01
 SG_ HVESP01_estOcv_21_6 m5: 8|14@1+ (0.001,0) [0|16.383] "Ah"  HVESP01
 SG_ HVESP01_estOcv_22_6 m5: 22|14@1+ (0.001,0) [0|16.383] "Ah"  HVESP01
 SG_ HVESP01_estOcv_23_6 m5: 36|14@1+ (0.001,0) [0|16.383] "Ah"  HVESP01
 SG_ HVESP01_estOcv_24_6 m5: 50|14@1+ (0.001,0) [0|16.383] "Ah"  HVESP01
 SG_ HVESP01_estOcv_25_6 m6: 8|14@1+ (0.001,0) [0|16.383] "Ah"  HVESP01
 SG_ HVESP01_estOcv_26_6 m6: 22|14@1+ (0.001,0) [0|16.383] "Ah"  HVESP01
 SG_ HVESP01_estOcv_27_6 m6: 36|14@1+ (0.001,0) [0|16.383] "Ah"  HVESP01
 SG_ HVESP01_estOcv_28_6 m6: 50|14@1+ (0.001,0) [0|16.383] "Ah"  HVESP01
 SG_ HVESP01_estOcv_29_6 m7: 8|14@1+ (0.001,0) [0|16.383] "Ah"  HVESP01
 SG_ HVESP01_estOcv_30_6 m7: 22|14@1+ (0.001,0) [0|16.383] "Ah"  HVESP01
 SG_ HVESP01_estOcv_31_6 m7: 36|14@1+ (0.001,0) [0|16.383] "Ah"  HVESP01
 SG_ HVESP01_estOcv_32_6 m7: 50|14@1+ (0.001,0) [0|16.383] "Ah"  HVESP01
 SG_ HVESP01_estOcv_33_6 m8: 8|14@1+ (0.001,0) [0|16.383] "Ah"  HVESP01
 SG_ HVESP01_estOcv_34_6 m8: 22|14@1+ (0.001,0) [0|16.383] "Ah"  HVESP01
 SG_ HVESP01_estOcv_35_6 m8: 36|14@1+ (0.001,0) [0|16.383] "Ah"  HVESP01
 SG_ HVESP01_estOcv_36_6 m8: 50|14@1+ (0.001,0) [0|16.383] "Ah"  HVESP01
 SG_ HVESP01_estOcv_37_6 m9: 8|14@1+ (0.001,0) [0|16.383] "Ah"  HVESP01
 SG_ HVESP01_estOcv_38_6 m9: 22|14@1+ (0.001,0) [0|16.383] "Ah"  HVESP01
 SG_ HVESP01_estOcv_39_6 m9: 36|14@1+ (0.001,0) [0|16.383] "Ah"  HVESP01
 SG_ HVESP01_estOcv_40_6 m9: 50|14@1+ (0.001,0) [0|16.383] "Ah"  HVESP01
 SG_ HVESP01_estOcv_41_6 m10: 8|14@1+ (0.001,0) [0|16.383] "Ah"  HVESP01
 SG_ HVESP01_estOcv_42_6 m10: 22|14@1+ (0.001,0) [0|16.383] "Ah"  HVESP01
 SG_ HVESP01_estOcv_43_6 m10: 36|14@1+ (0.001,0) [0|16.383] "Ah"  HVESP01
 SG_ HVESP01_estOcv_44_6 m10: 50|14@1+ (0.001,0) [0|16.383] "Ah"  HVESP01
 SG_ HVESP01_estOcv_45_6 m11: 8|14@1+ (0.001,0) [0|16.383] "Ah"  HVESP01
 SG_ HVESP01_estOcv_46_6 m11: 22|14@1+ (0.001,0) [0|16.383] "Ah"  HVESP01
 SG_ HVESP01_estOcv_47_6 m11: 36|14@1+ (0.001,0) [0|16.383] "Ah"  HVESP01
 SG_ HVESP01_estOcv_48_6 m11: 50|14@1+ (0.001,0) [0|16.383] "Ah"  HVESP01
 SG_ HVESP01_estOcv_49_6 m12: 8|14@1+ (0.001,0) [0|16.383] "Ah"  HVESP01
 SG_ HVESP01_estOcv_50_6 m12: 22|14@1+ (0.001,0) [0|16.383] "Ah"  HVESP01
 SG_ HVESP01_estOcv_51_6 m12: 36|14@1+ (0.001,0) [0|16.383] "Ah"  HVESP01
 SG_ HVESP01_estOcv_52_6 m12: 50|14@1+ (0.001,0) [0|16.383] "Ah"  HVESP01
 SG_ HVESP01_estOcv_53_6 m13: 8|14@1+ (0.001,0) [0|16.383] "Ah"  HVESP01
 SG_ HVESP01_estOcv_54_6 m13: 22|14@1+ (0.001,0) [0|16.383] "Ah"  HVESP01
 SG_ HVESP01_estOcv_55_6 m13: 36|14@1+ (0.001,0) [0|16.383] "Ah"  HVESP01
 SG_ HVESP01_estOcv_56_6 m13: 50|14@1+ (0.001,0) [0|16.383] "Ah"  HVESP01
 SG_ HVESP01_estOcv_57_6 m14: 8|14@1+ (0.001,0) [0|16.383] "Ah"  HVESP01
 SG_ HVESP01_estOcv_58_6 m14: 22|14@1+ (0.001,0) [0|16.383] "Ah"  HVESP01
 SG_ HVESP01_estOcv_59_6 m14: 36|14@1+ (0.001,0) [0|16.383] "Ah"  HVESP01
 SG_ HVESP01_estOcv_60_6 m14: 50|14@1+ (0.001,0) [0|16.383] "Ah"  HVESP01
 SG_ HVESP01_estOcv_61_6 m15: 8|14@1+ (0.001,0) [0|16.383] "Ah"  HVESP01
 SG_ HVESP01_estOcv_62_6 m15: 22|14@1+ (0.001,0) [0|16.383] "Ah"  HVESP01
 SG_ HVESP01_estOcv_63_6 m15: 36|14@1+ (0.001,0) [0|16.383] "Ah"  HVESP01
 SG_ HVESP01_estOcv_64_6 m15: 50|14@1+ (0.001,0) [0|16.383] "Ah"  HVESP01
 SG_ HVESP01_estOcv_65_6 m16: 8|14@1+ (0.001,0) [0|16.383] "Ah"  HVESP01
 SG_ HVESP01_estOcv_66_6 m16: 22|14@1+ (0.001,0) [0|16.383] "Ah"  HVESP01
 SG_ HVESP01_estOcv_67_6 m16: 36|14@1+ (0.001,0) [0|16.383] "Ah"  HVESP01
 SG_ HVESP01_estOcv_68_6 m16: 50|14@1+ (0.001,0) [0|16.383] "Ah"  HVESP01
 SG_ HVESP01_estOcv_69_6 m17: 8|14@1+ (0.001,0) [0|16.383] "Ah"  HVESP01
 SG_ HVESP01_estOcv_70_6 m17: 22|14@1+ (0.001,0) [0|16.383] "Ah"  HVESP01
 SG_ HVESP01_estOcv_71_6 m17: 36|14@1+ (0.001,0) [0|16.383] "Ah"  HVESP01
 SG_ HVESP01_estOcv_72_6 m17: 50|14@1+ (0.001,0) [0|16.383] "Ah"  HVESP01
 SG_ HVESP01_estOcv_73_6 m18: 8|14@1+ (0.001,0) [0|16.383] "Ah"  HVESP01
 SG_ HVESP01_estOcv_74_6 m18: 22|14@1+ (0.001,0) [0|16.383] "Ah"  HVESP01
 SG_ HVESP01_estOcv_75_6 m18: 36|14@1+ (0.001,0) [0|16.383] "Ah"  HVESP01
 SG_ HVESP01_estOcv_76_6 m18: 50|14@1+ (0.001,0) [0|16.383] "Ah"  HVESP01
 SG_ HVESP01_estOcv_77_6 m19: 8|14@1+ (0.001,0) [0|16.383] "Ah"  HVESP01
 SG_ HVESP01_estOcv_78_6 m19: 22|14@1+ (0.001,0) [0|16.383] "Ah"  HVESP01
 SG_ HVESP01_estOcv_79_6 m19: 36|14@1+ (0.001,0) [0|16.383] "Ah"  HVESP01
 SG_ HVESP01_estOcv_80_6 m19: 50|14@1+ (0.001,0) [0|16.383] "Ah"  HVESP01
 SG_ HVESP01_estOcv_81_6 m20: 8|14@1+ (0.001,0) [0|16.383] "Ah"  HVESP01
 SG_ HVESP01_estOcv_82_6 m20: 22|14@1+ (0.001,0) [0|16.383] "Ah"  HVESP01
 SG_ HVESP01_estOcv_83_6 m20: 36|14@1+ (0.001,0) [0|16.383] "Ah"  HVESP01
 SG_ HVESP01_estOcv_84_6 m20: 50|14@1+ (0.001,0) [0|16.383] "Ah"  HVESP01
 SG_ HVESP01_estOcv_85_6 m21: 8|14@1+ (0.001,0) [0|16.383] "Ah"  HVESP01
 SG_ HVESP01_estOcv_86_6 m21: 22|14@1+ (0.001,0) [0|16.383] "Ah"  HVESP01
 SG_ HVESP01_estOcv_87_6 m21: 36|14@1+ (0.001,0) [0|16.383] "Ah"  HVESP01
 SG_ HVESP01_estOcv_88_6 m21: 50|14@1+ (0.001,0) [0|16.383] "Ah"  HVESP01
 SG_ HVESP01_estOcv_89_6 m22: 8|14@1+ (0.001,0) [0|16.383] "Ah"  HVESP01
 SG_ HVESP01_estOcv_90_6 m22: 22|14@1+ (0.001,0) [0|16.383] "Ah"  HVESP01
 SG_ HVESP01_estOcv_91_6 m22: 36|14@1+ (0.001,0) [0|16.383] "Ah"  HVESP01
 SG_ HVESP01_estOcv_92_6 m22: 50|14@1+ (0.001,0) [0|16.383] "Ah"  HVESP01
 SG_ HVESP01_estOcv_93_6 m23: 8|14@1+ (0.001,0) [0|16.383] "Ah"  HVESP01
 SG_ HVESP01_estOcv_94_6 m23: 22|14@1+ (0.001,0) [0|16.383] "Ah"  HVESP01
 SG_ HVESP01_estOcv_95_6 m23: 36|14@1+ (0.001,0) [0|16.383] "Ah"  HVESP01
 SG_ HVESP01_estOcv_96_6 m23: 50|14@1+ (0.001,0) [0|16.383] "Ah"  HVESP01
 SG_ HVESP01_estOcv_97_6 m24: 8|14@1+ (0.001,0) [0|16.383] "Ah"  HVESP01
 SG_ HVESP01_estOcv_98_6 m24: 22|14@1+ (0.001,0) [0|16.383] "Ah"  HVESP01
 SG_ HVESP01_estOcv_99_6 m24: 36|14@1+ (0.001,0) [0|16.383] "Ah"  HVESP01
 SG_ HVESP01_estOcv_100_6 m24: 50|14@1+ (0.001,0) [0|16.383] "Ah"  HVESP01
 SG_ HVESP01_estOcv_101_6 m25: 8|14@1+ (0.001,0) [0|16.383] "Ah"  HVESP01
 SG_ HVESP01_estOcv_102_6 m25: 22|14@1+ (0.001,0) [0|16.383] "Ah"  HVESP01
 SG_ HVESP01_estOcv_103_6 m25: 36|14@1+ (0.001,0) [0|16.383] "Ah"  HVESP01
 SG_ HVESP01_estOcv_104_6 m25: 50|14@1+ (0.001,0) [0|16.383] "Ah"  HVESP01
 SG_ HVESP01_estOcv_105_6 m26: 8|14@1+ (0.001,0) [0|16.383] "Ah"  HVESP01
 SG_ HVESP01_estOcv_106_6 m26: 22|14@1+ (0.001,0) [0|16.383] "Ah"  HVESP01
 SG_ HVESP01_estOcv_107_6 m26: 36|14@1+ (0.001,0) [0|16.383] "Ah"  HVESP01
 SG_ HVESP01_estOcv_108_6 m26: 50|14@1+ (0.001,0) [0|16.383] "Ah"  HVESP01
 SG_ HVESP01_estOcv_109_6 m27: 8|14@1+ (0.001,0) [0|16.383] "Ah"  HVESP01
 SG_ HVESP01_estOcv_110_6 m27: 22|14@1+ (0.001,0) [0|16.383] "Ah"  HVESP01
 SG_ HVESP01_estOcv_111_6 m27: 36|14@1+ (0.001,0) [0|16.383] "Ah"  HVESP01
 SG_ HVESP01_estOcv_112_6 m27: 50|14@1+ (0.001,0) [0|16.383] "Ah"  HVESP01
 SG_ HVESP01_estOcv_113_6 m28: 8|14@1+ (0.001,0) [0|16.383] "Ah"  HVESP01
 SG_ HVESP01_estOcv_114_6 m28: 22|14@1+ (0.001,0) [0|16.383] "Ah"  HVESP01
 SG_ HVESP01_estOcv_115_6 m28: 36|14@1+ (0.001,0) [0|16.383] "Ah"  HVESP01
 SG_ HVESP01_estOcv_116_6 m28: 50|14@1+ (0.001,0) [0|16.383] "Ah"  HVESP01
 SG_ HVESP01_estOcv_117_6 m29: 8|14@1+ (0.001,0) [0|16.383] "Ah"  HVESP01
 SG_ HVESP01_estOcv_118_6 m29: 22|14@1+ (0.001,0) [0|16.383] "Ah"  HVESP01
 SG_ HVESP01_estOcv_119_6 m29: 36|14@1+ (0.001,0) [0|16.383] "Ah"  HVESP01
 SG_ HVESP01_estOcv_120_6 m29: 50|14@1+ (0.001,0) [0|16.383] "Ah"  HVESP01
 SG_ HVESP01_estOcv_121_6 m30: 8|14@1+ (0.001,0) [0|16.383] "Ah"  HVESP01
 SG_ HVESP01_estOcv_122_6 m30: 22|14@1+ (0.001,0) [0|16.383] "Ah"  HVESP01
 SG_ HVESP01_estOcv_123_6 m30: 36|14@1+ (0.001,0) [0|16.383] "Ah"  HVESP01
 SG_ HVESP01_estOcv_124_6 m30: 50|14@1+ (0.001,0) [0|16.383] "Ah"  HVESP01
 SG_ HVESP01_estOcv_125_6 m31: 8|14@1+ (0.001,0) [0|16.383] "Ah"  HVESP01
 SG_ HVESP01_estOcv_126_6 m31: 22|14@1+ (0.001,0) [0|16.383] "Ah"  HVESP01
 SG_ HVESP01_estOcv_127_6 m31: 36|14@1+ (0.001,0) [0|16.383] "Ah"  HVESP01
 SG_ HVESP01_estOcv_128_6 m31: 50|14@1+ (0.001,0) [0|16.383] "Ah"  HVESP01
 SG_ HVESP01_estOcv_129_6 m32: 8|14@1+ (0.001,0) [0|16.383] "Ah"  HVESP01
 SG_ HVESP01_estOcv_130_6 m32: 22|14@1+ (0.001,0) [0|16.383] "Ah"  HVESP01
 SG_ HVESP01_estOcv_131_6 m32: 36|14@1+ (0.001,0) [0|16.383] "Ah"  HVESP01
 SG_ HVESP01_estOcv_132_6 m32: 50|14@1+ (0.001,0) [0|16.383] "Ah"  HVESP01
 SG_ HVESP01_estOcv_133_6 m33: 8|14@1+ (0.001,0) [0|16.383] "Ah"  HVESP01
 SG_ HVESP01_estOcv_134_6 m33: 22|14@1+ (0.001,0) [0|16.383] "Ah"  HVESP01
 SG_ HVESP01_estOcv_135_6 m33: 36|14@1+ (0.001,0) [0|16.383] "Ah"  HVESP01
 SG_ HVESP01_estOcv_136_6 m33: 50|14@1+ (0.001,0) [0|16.383] "Ah"  HVESP01
 SG_ HVESP01_estOcv_137_6 m34: 8|14@1+ (0.001,0) [0|16.383] "Ah"  HVESP01
 SG_ HVESP01_estOcv_138_6 m34: 22|14@1+ (0.001,0) [0|16.383] "Ah"  HVESP01
 SG_ HVESP01_estOcv_139_6 m34: 36|14@1+ (0.001,0) [0|16.383] "Ah"  HVESP01
 SG_ HVESP01_estOcv_140_6 m34: 50|14@1+ (0.001,0) [0|16.383] "Ah"  HVESP01
 SG_ HVESP01_estOcv_141_6 m35: 8|14@1+ (0.001,0) [0|16.383] "Ah"  HVESP01
 SG_ HVESP01_estOcv_142_6 m35: 22|14@1+ (0.001,0) [0|16.383] "Ah"  HVESP01
 SG_ HVESP01_estOcv_143_6 m35: 36|14@1+ (0.001,0) [0|16.383] "Ah"  HVESP01
 SG_ HVESP01_estOcv_144_6 m35: 50|14@1+ (0.001,0) [0|16.383] "Ah"  HVESP01
 SG_ HVESP01_estOcv_145_6 m36: 8|14@1+ (0.001,0) [0|16.383] "Ah"  HVESP01
 SG_ HVESP01_estOcv_146_6 m36: 22|14@1+ (0.001,0) [0|16.383] "Ah"  HVESP01
 SG_ HVESP01_estOcv_147_6 m36: 36|14@1+ (0.001,0) [0|16.383] "Ah"  HVESP01
 SG_ HVESP01_estOcv_148_6 m36: 50|14@1+ (0.001,0) [0|16.383] "Ah"  HVESP01
 SG_ HVESP01_estOcv_149_6 m37: 8|14@1+ (0.001,0) [0|16.383] "Ah"  HVESP01
 SG_ HVESP01_estOcv_150_6 m37: 22|14@1+ (0.001,0) [0|16.383] "Ah"  HVESP01
 SG_ HVESP01_estOcv_151_6 m37: 36|14@1+ (0.001,0) [0|16.383] "Ah"  HVESP01
 SG_ HVESP01_estOcv_152_6 m37: 50|14@1+ (0.001,0) [0|16.383] "Ah"  HVESP01
 SG_ HVESP01_estOcv_153_6 m38: 8|14@1+ (0.001,0) [0|16.383] "Ah"  HVESP01
 SG_ HVESP01_estOcv_154_6 m38: 22|14@1+ (0.001,0) [0|16.383] "Ah"  HVESP01
 SG_ HVESP01_estOcv_155_6 m38: 36|14@1+ (0.001,0) [0|16.383] "Ah"  HVESP01
 SG_ HVESP01_estOcv_156_6 m38: 50|14@1+ (0.001,0) [0|16.383] "Ah"  HVESP01
 SG_ HVESP01_estOcv_157_6 m39: 8|14@1+ (0.001,0) [0|16.383] "Ah"  HVESP01
 SG_ HVESP01_estOcv_158_6 m39: 22|14@1+ (0.001,0) [0|16.383] "Ah"  HVESP01
 SG_ HVESP01_estOcv_159_6 m39: 36|14@1+ (0.001,0) [0|16.383] "Ah"  HVESP01
 SG_ HVESP01_estOcv_160_6 m39: 50|14@1+ (0.001,0) [0|16.383] "Ah"  HVESP01
 SG_ HVESP01_estOcv_161_6 m40: 8|14@1+ (0.001,0) [0|16.383] "Ah"  HVESP01
 SG_ HVESP01_estOcv_162_6 m40: 22|14@1+ (0.001,0) [0|16.383] "Ah"  HVESP01
 SG_ HVESP01_estOcv_163_6 m40: 36|14@1+ (0.001,0) [0|16.383] "Ah"  HVESP01
 SG_ HVESP01_estOcv_164_6 m40: 50|14@1+ (0.001,0) [0|16.383] "Ah"  HVESP01
 SG_ HVESP01_estOcv_165_6 m41: 8|14@1+ (0.001,0) [0|16.383] "Ah"  HVESP01
 SG_ HVESP01_estOcv_166_6 m41: 22|14@1+ (0.001,0) [0|16.383] "Ah"  HVESP01
 SG_ HVESP01_estOcv_167_6 m41: 36|14@1+ (0.001,0) [0|16.383] "Ah"  HVESP01
 SG_ HVESP01_estOcv_168_6 m41: 50|14@1+ (0.001,0) [0|16.383] "Ah"  HVESP01
 SG_ HVESP01_estOcv_169_6 m42: 8|14@1+ (0.001,0) [0|16.383] "Ah"  HVESP01
 SG_ HVESP01_estOcv_170_6 m42: 22|14@1+ (0.001,0) [0|16.383] "Ah"  HVESP01
 SG_ HVESP01_estOcv_171_6 m42: 36|14@1+ (0.001,0) [0|16.383] "Ah"  HVESP01
 SG_ HVESP01_estOcv_172_6 m42: 50|14@1+ (0.001,0) [0|16.383] "Ah"  HVESP01
 SG_ HVESP01_estOcv_173_6 m43: 8|14@1+ (0.001,0) [0|16.383] "Ah"  HVESP01
 SG_ HVESP01_estOcv_174_6 m43: 22|14@1+ (0.001,0) [0|16.383] "Ah"  HVESP01
 SG_ HVESP01_estOcv_175_6 m43: 36|14@1+ (0.001,0) [0|16.383] "Ah"  HVESP01
 SG_ HVESP01_estOcv_176_6 m43: 50|14@1+ (0.001,0) [0|16.383] "Ah"  HVESP01
 SG_ HVESP01_estOcv_177_6 m44: 8|14@1+ (0.001,0) [0|16.383] "Ah"  HVESP01
 SG_ HVESP01_estOcv_178_6 m44: 22|14@1+ (0.001,0) [0|16.383] "Ah"  HVESP01
 SG_ HVESP01_estOcv_179_6 m44: 36|14@1+ (0.001,0) [0|16.383] "Ah"  HVESP01
 SG_ HVESP01_estOcv_180_6 m44: 50|14@1+ (0.001,0) [0|16.383] "Ah"  HVESP01
 SG_ HVESP01_estOcv_181_6 m45: 8|14@1+ (0.001,0) [0|16.383] "Ah"  HVESP01
 SG_ HVESP01_estOcv_182_6 m45: 22|14@1+ (0.001,0) [0|16.383] "Ah"  HVESP01
 SG_ HVESP01_estOcv_183_6 m45: 36|14@1+ (0.001,0) [0|16.383] "Ah"  HVESP01
 SG_ HVESP01_estOcv_184_6 m45: 50|14@1+ (0.001,0) [0|16.383] "Ah"  HVESP01
 SG_ HVESP01_estOcv_185_6 m46: 8|14@1+ (0.001,0) [0|16.383] "Ah"  HVESP01
 SG_ HVESP01_estOcv_186_6 m46: 22|14@1+ (0.001,0) [0|16.383] "Ah"  HVESP01
 SG_ HVESP01_estOcv_187_6 m46: 36|14@1+ (0.001,0) [0|16.383] "Ah"  HVESP01
 SG_ HVESP01_estOcv_188_6 m46: 50|14@1+ (0.001,0) [0|16.383] "Ah"  HVESP01
 SG_ HVESP01_estOcv_189_6 m47: 8|14@1+ (0.001,0) [0|16.383] "Ah"  HVESP01
 SG_ HVESP01_estOcv_190_6 m47: 22|14@1+ (0.001,0) [0|16.383] "Ah"  HVESP01
 SG_ HVESP01_estOcv_191_6 m47: 36|14@1+ (0.001,0) [0|16.383] "Ah"  HVESP01
 SG_ HVESP01_estOcv_192_6 m47: 50|14@1+ (0.001,0) [0|16.383] "Ah"  HVESP01
 SG_ multiplexoreo_6 M: 0|8@1+ (1,0) [0|255] ""  HVESP01

BO_ 2499750251 HVESP01_EstOcv_7: 8 HVESP01
 SG_ HVESP01_estOcv_01_7 m0: 8|14@1+ (0.001,0) [0|16.383] "Ah"  HVESP01
 SG_ HVESP01_estOcv_02_7 m0: 22|14@1+ (0.001,0) [0|16.383] "Ah"  HVESP01
 SG_ HVESP01_estOcv_03_7 m0: 36|14@1+ (0.001,0) [0|16.383] "Ah"  HVESP01
 SG_ HVESP01_estOcv_04_7 m0: 50|14@1+ (0.001,0) [0|16.383] "Ah"  HVESP01
 SG_ HVESP01_estOcv_05_7 m1: 8|14@1+ (0.001,0) [0|16.383] "Ah"  HVESP01
 SG_ HVESP01_estOcv_06_7 m1: 22|14@1+ (0.001,0) [0|16.383] "Ah"  HVESP01
 SG_ HVESP01_estOcv_07_7 m1: 36|14@1+ (0.001,0) [0|16.383] "Ah"  HVESP01
 SG_ HVESP01_estOcv_08_7 m1: 50|14@1+ (0.001,0) [0|16.383] "Ah"  HVESP01
 SG_ HVESP01_estOcv_09_7 m2: 8|14@1+ (0.001,0) [0|16.383] "Ah"  HVESP01
 SG_ HVESP01_estOcv_10_7 m2: 22|14@1+ (0.001,0) [0|16.383] "Ah"  HVESP01
 SG_ HVESP01_estOcv_11_7 m2: 36|14@1+ (0.001,0) [0|16.383] "Ah"  HVESP01
 SG_ HVESP01_estOcv_12_7 m2: 50|14@1+ (0.001,0) [0|16.383] "Ah"  HVESP01
 SG_ HVESP01_estOcv_13_7 m3: 8|14@1+ (0.001,0) [0|16.383] "Ah"  HVESP01
 SG_ HVESP01_estOcv_14_7 m3: 22|14@1+ (0.001,0) [0|16.383] "Ah"  HVESP01
 SG_ HVESP01_estOcv_15_7 m3: 36|14@1+ (0.001,0) [0|16.383] "Ah"  HVESP01
 SG_ HVESP01_estOcv_16_7 m3: 50|14@1+ (0.001,0) [0|16.383] "Ah"  HVESP01
 SG_ HVESP01_estOcv_17_7 m4: 8|14@1+ (0.001,0) [0|16.383] "Ah"  HVESP01
 SG_ HVESP01_estOcv_18_7 m4: 22|14@1+ (0.001,0) [0|16.383] "Ah"  HVESP01
 SG_ HVESP01_estOcv_19_7 m4: 36|14@1+ (0.001,0) [0|16.383] "Ah"  HVESP01
 SG_ HVESP01_estOcv_20_7 m4: 50|14@1+ (0.001,0) [0|16.383] "Ah"  HVESP01
 SG_ HVESP01_estOcv_21_7 m5: 8|14@1+ (0.001,0) [0|16.383] "Ah"  HVESP01
 SG_ HVESP01_estOcv_22_7 m5: 22|14@1+ (0.001,0) [0|16.383] "Ah"  HVESP01
 SG_ HVESP01_estOcv_23_7 m5: 36|14@1+ (0.001,0) [0|16.383] "Ah"  HVESP01
 SG_ HVESP01_estOcv_24_7 m5: 50|14@1+ (0.001,0) [0|16.383] "Ah"  HVESP01
 SG_ HVESP01_estOcv_25_7 m6: 8|14@1+ (0.001,0) [0|16.383] "Ah"  HVESP01
 SG_ HVESP01_estOcv_26_7 m6: 22|14@1+ (0.001,0) [0|16.383] "Ah"  HVESP01
 SG_ HVESP01_estOcv_27_7 m6: 36|14@1+ (0.001,0) [0|16.383] "Ah"  HVESP01
 SG_ HVESP01_estOcv_28_7 m6: 50|14@1+ (0.001,0) [0|16.383] "Ah"  HVESP01
 SG_ HVESP01_estOcv_29_7 m7: 8|14@1+ (0.001,0) [0|16.383] "Ah"  HVESP01
 SG_ HVESP01_estOcv_30_7 m7: 22|14@1+ (0.001,0) [0|16.383] "Ah"  HVESP01
 SG_ HVESP01_estOcv_31_7 m7: 36|14@1+ (0.001,0) [0|16.383] "Ah"  HVESP01
 SG_ HVESP01_estOcv_32_7 m7: 50|14@1+ (0.001,0) [0|16.383] "Ah"  HVESP01
 SG_ HVESP01_estOcv_33_7 m8: 8|14@1+ (0.001,0) [0|16.383] "Ah"  HVESP01
 SG_ HVESP01_estOcv_34_7 m8: 22|14@1+ (0.001,0) [0|16.383] "Ah"  HVESP01
 SG_ HVESP01_estOcv_35_7 m8: 36|14@1+ (0.001,0) [0|16.383] "Ah"  HVESP01
 SG_ HVESP01_estOcv_36_7 m8: 50|14@1+ (0.001,0) [0|16.383] "Ah"  HVESP01
 SG_ HVESP01_estOcv_37_7 m9: 8|14@1+ (0.001,0) [0|16.383] "Ah"  HVESP01
 SG_ HVESP01_estOcv_38_7 m9: 22|14@1+ (0.001,0) [0|16.383] "Ah"  HVESP01
 SG_ HVESP01_estOcv_39_7 m9: 36|14@1+ (0.001,0) [0|16.383] "Ah"  HVESP01
 SG_ HVESP01_estOcv_40_7 m9: 50|14@1+ (0.001,0) [0|16.383] "Ah"  HVESP01
 SG_ HVESP01_estOcv_41_7 m10: 8|14@1+ (0.001,0) [0|16.383] "Ah"  HVESP01
 SG_ HVESP01_estOcv_42_7 m10: 22|14@1+ (0.001,0) [0|16.383] "Ah"  HVESP01
 SG_ HVESP01_estOcv_43_7 m10: 36|14@1+ (0.001,0) [0|16.383] "Ah"  HVESP01
 SG_ HVESP01_estOcv_44_7 m10: 50|14@1+ (0.001,0) [0|16.383] "Ah"  HVESP01
 SG_ HVESP01_estOcv_45_7 m11: 8|14@1+ (0.001,0) [0|16.383] "Ah"  HVESP01
 SG_ HVESP01_estOcv_46_7 m11: 22|14@1+ (0.001,0) [0|16.383] "Ah"  HVESP01
 SG_ HVESP01_estOcv_47_7 m11: 36|14@1+ (0.001,0) [0|16.383] "Ah"  HVESP01
 SG_ HVESP01_estOcv_48_7 m11: 50|14@1+ (0.001,0) [0|16.383] "Ah"  HVESP01
 SG_ HVESP01_estOcv_49_7 m12: 8|14@1+ (0.001,0) [0|16.383] "Ah"  HVESP01
 SG_ HVESP01_estOcv_50_7 m12: 22|14@1+ (0.001,0) [0|16.383] "Ah"  HVESP01
 SG_ HVESP01_estOcv_51_7 m12: 36|14@1+ (0.001,0) [0|16.383] "Ah"  HVESP01
 SG_ HVESP01_estOcv_52_7 m12: 50|14@1+ (0.001,0) [0|16.383] "Ah"  HVESP01
 SG_ HVESP01_estOcv_53_7 m13: 8|14@1+ (0.001,0) [0|16.383] "Ah"  HVESP01
 SG_ HVESP01_estOcv_54_7 m13: 22|14@1+ (0.001,0) [0|16.383] "Ah"  HVESP01
 SG_ HVESP01_estOcv_55_7 m13: 36|14@1+ (0.001,0) [0|16.383] "Ah"  HVESP01
 SG_ HVESP01_estOcv_56_7 m13: 50|14@1+ (0.001,0) [0|16.383] "Ah"  HVESP01
 SG_ HVESP01_estOcv_57_7 m14: 8|14@1+ (0.001,0) [0|16.383] "Ah"  HVESP01
 SG_ HVESP01_estOcv_58_7 m14: 22|14@1+ (0.001,0) [0|16.383] "Ah"  HVESP01
 SG_ HVESP01_estOcv_59_7 m14: 36|14@1+ (0.001,0) [0|16.383] "Ah"  HVESP01
 SG_ HVESP01_estOcv_60_7 m14: 50|14@1+ (0.001,0) [0|16.383] "Ah"  HVESP01
 SG_ HVESP01_estOcv_61_7 m15: 8|14@1+ (0.001,0) [0|16.383] "Ah"  HVESP01
 SG_ HVESP01_estOcv_62_7 m15: 22|14@1+ (0.001,0) [0|16.383] "Ah"  HVESP01
 SG_ HVESP01_estOcv_63_7 m15: 36|14@1+ (0.001,0) [0|16.383] "Ah"  HVESP01
 SG_ HVESP01_estOcv_64_7 m15: 50|14@1+ (0.001,0) [0|16.383] "Ah"  HVESP01
 SG_ HVESP01_estOcv_65_7 m16: 8|14@1+ (0.001,0) [0|16.383] "Ah"  HVESP01
 SG_ HVESP01_estOcv_66_7 m16: 22|14@1+ (0.001,0) [0|16.383] "Ah"  HVESP01
 SG_ HVESP01_estOcv_67_7 m16: 36|14@1+ (0.001,0) [0|16.383] "Ah"  HVESP01
 SG_ HVESP01_estOcv_68_7 m16: 50|14@1+ (0.001,0) [0|16.383] "Ah"  HVESP01
 SG_ HVESP01_estOcv_69_7 m17: 8|14@1+ (0.001,0) [0|16.383] "Ah"  HVESP01
 SG_ HVESP01_estOcv_70_7 m17: 22|14@1+ (0.001,0) [0|16.383] "Ah"  HVESP01
 SG_ HVESP01_estOcv_71_7 m17: 36|14@1+ (0.001,0) [0|16.383] "Ah"  HVESP01
 SG_ HVESP01_estOcv_72_7 m17: 50|14@1+ (0.001,0) [0|16.383] "Ah"  HVESP01
 SG_ HVESP01_estOcv_73_7 m18: 8|14@1+ (0.001,0) [0|16.383] "Ah"  HVESP01
 SG_ HVESP01_estOcv_74_7 m18: 22|14@1+ (0.001,0) [0|16.383] "Ah"  HVESP01
 SG_ HVESP01_estOcv_75_7 m18: 36|14@1+ (0.001,0) [0|16.383] "Ah"  HVESP01
 SG_ HVESP01_estOcv_76_7 m18: 50|14@1+ (0.001,0) [0|16.383] "Ah"  HVESP01
 SG_ HVESP01_estOcv_77_7 m19: 8|14@1+ (0.001,0) [0|16.383] "Ah"  HVESP01
 SG_ HVESP01_estOcv_78_7 m19: 22|14@1+ (0.001,0) [0|16.383] "Ah"  HVESP01
 SG_ HVESP01_estOcv_79_7 m19: 36|14@1+ (0.001,0) [0|16.383] "Ah"  HVESP01
 SG_ HVESP01_estOcv_80_7 m19: 50|14@1+ (0.001,0) [0|16.383] "Ah"  HVESP01
 SG_ HVESP01_estOcv_81_7 m20: 8|14@1+ (0.001,0) [0|16.383] "Ah"  HVESP01
 SG_ HVESP01_estOcv_82_7 m20: 22|14@1+ (0.001,0) [0|16.383] "Ah"  HVESP01
 SG_ HVESP01_estOcv_83_7 m20: 36|14@1+ (0.001,0) [0|16.383] "Ah"  HVESP01
 SG_ HVESP01_estOcv_84_7 m20: 50|14@1+ (0.001,0) [0|16.383] "Ah"  HVESP01
 SG_ HVESP01_estOcv_85_7 m21: 8|14@1+ (0.001,0) [0|16.383] "Ah"  HVESP01
 SG_ HVESP01_estOcv_86_7 m21: 22|14@1+ (0.001,0) [0|16.383] "Ah"  HVESP01
 SG_ HVESP01_estOcv_87_7 m21: 36|14@1+ (0.001,0) [0|16.383] "Ah"  HVESP01
 SG_ HVESP01_estOcv_88_7 m21: 50|14@1+ (0.001,0) [0|16.383] "Ah"  HVESP01
 SG_ HVESP01_estOcv_89_7 m22: 8|14@1+ (0.001,0) [0|16.383] "Ah"  HVESP01
 SG_ HVESP01_estOcv_90_7 m22: 22|14@1+ (0.001,0) [0|16.383] "Ah"  HVESP01
 SG_ HVESP01_estOcv_91_7 m22: 36|14@1+ (0.001,0) [0|16.383] "Ah"  HVESP01
 SG_ HVESP01_estOcv_92_7 m22: 50|14@1+ (0.001,0) [0|16.383] "Ah"  HVESP01
 SG_ HVESP01_estOcv_93_7 m23: 8|14@1+ (0.001,0) [0|16.383] "Ah"  HVESP01
 SG_ HVESP01_estOcv_94_7 m23: 22|14@1+ (0.001,0) [0|16.383] "Ah"  HVESP01
 SG_ HVESP01_estOcv_95_7 m23: 36|14@1+ (0.001,0) [0|16.383] "Ah"  HVESP01
 SG_ HVESP01_estOcv_96_7 m23: 50|14@1+ (0.001,0) [0|16.383] "Ah"  HVESP01
 SG_ HVESP01_estOcv_97_7 m24: 8|14@1+ (0.001,0) [0|16.383] "Ah"  HVESP01
 SG_ HVESP01_estOcv_98_7 m24: 22|14@1+ (0.001,0) [0|16.383] "Ah"  HVESP01
 SG_ HVESP01_estOcv_99_7 m24: 36|14@1+ (0.001,0) [0|16.383] "Ah"  HVESP01
 SG_ HVESP01_estOcv_100_7 m24: 50|14@1+ (0.001,0) [0|16.383] "Ah"  HVESP01
 SG_ HVESP01_estOcv_101_7 m25: 8|14@1+ (0.001,0) [0|16.383] "Ah"  HVESP01
 SG_ HVESP01_estOcv_102_7 m25: 22|14@1+ (0.001,0) [0|16.383] "Ah"  HVESP01
 SG_ HVESP01_estOcv_103_7 m25: 36|14@1+ (0.001,0) [0|16.383] "Ah"  HVESP01
 SG_ HVESP01_estOcv_104_7 m25: 50|14@1+ (0.001,0) [0|16.383] "Ah"  HVESP01
 SG_ HVESP01_estOcv_105_7 m26: 8|14@1+ (0.001,0) [0|16.383] "Ah"  HVESP01
 SG_ HVESP01_estOcv_106_7 m26: 22|14@1+ (0.001,0) [0|16.383] "Ah"  HVESP01
 SG_ HVESP01_estOcv_107_7 m26: 36|14@1+ (0.001,0) [0|16.383] "Ah"  HVESP01
 SG_ HVESP01_estOcv_108_7 m26: 50|14@1+ (0.001,0) [0|16.383] "Ah"  HVESP01
 SG_ HVESP01_estOcv_109_7 m27: 8|14@1+ (0.001,0) [0|16.383] "Ah"  HVESP01
 SG_ HVESP01_estOcv_110_7 m27: 22|14@1+ (0.001,0) [0|16.383] "Ah"  HVESP01
 SG_ HVESP01_estOcv_111_7 m27: 36|14@1+ (0.001,0) [0|16.383] "Ah"  HVESP01
 SG_ HVESP01_estOcv_112_7 m27: 50|14@1+ (0.001,0) [0|16.383] "Ah"  HVESP01
 SG_ HVESP01_estOcv_113_7 m28: 8|14@1+ (0.001,0) [0|16.383] "Ah"  HVESP01
 SG_ HVESP01_estOcv_114_7 m28: 22|14@1+ (0.001,0) [0|16.383] "Ah"  HVESP01
 SG_ HVESP01_estOcv_115_7 m28: 36|14@1+ (0.001,0) [0|16.383] "Ah"  HVESP01
 SG_ HVESP01_estOcv_116_7 m28: 50|14@1+ (0.001,0) [0|16.383] "Ah"  HVESP01
 SG_ HVESP01_estOcv_117_7 m29: 8|14@1+ (0.001,0) [0|16.383] "Ah"  HVESP01
 SG_ HVESP01_estOcv_118_7 m29: 22|14@1+ (0.001,0) [0|16.383] "Ah"  HVESP01
 SG_ HVESP01_estOcv_119_7 m29: 36|14@1+ (0.001,0) [0|16.383] "Ah"  HVESP01
 SG_ HVESP01_estOcv_120_7 m29: 50|14@1+ (0.001,0) [0|16.383] "Ah"  HVESP01
 SG_ HVESP01_estOcv_121_7 m30: 8|14@1+ (0.001,0) [0|16.383] "Ah"  HVESP01
 SG_ HVESP01_estOcv_122_7 m30: 22|14@1+ (0.001,0) [0|16.383] "Ah"  HVESP01
 SG_ HVESP01_estOcv_123_7 m30: 36|14@1+ (0.001,0) [0|16.383] "Ah"  HVESP01
 SG_ HVESP01_estOcv_124_7 m30: 50|14@1+ (0.001,0) [0|16.383] "Ah"  HVESP01
 SG_ HVESP01_estOcv_125_7 m31: 8|14@1+ (0.001,0) [0|16.383] "Ah"  HVESP01
 SG_ HVESP01_estOcv_126_7 m31: 22|14@1+ (0.001,0) [0|16.383] "Ah"  HVESP01
 SG_ HVESP01_estOcv_127_7 m31: 36|14@1+ (0.001,0) [0|16.383] "Ah"  HVESP01
 SG_ HVESP01_estOcv_128_7 m31: 50|14@1+ (0.001,0) [0|16.383] "Ah"  HVESP01
 SG_ HVESP01_estOcv_129_7 m32: 8|14@1+ (0.001,0) [0|16.383] "Ah"  HVESP01
 SG_ HVESP01_estOcv_130_7 m32: 22|14@1+ (0.001,0) [0|16.383] "Ah"  HVESP01
 SG_ HVESP01_estOcv_131_7 m32: 36|14@1+ (0.001,0) [0|16.383] "Ah"  HVESP01
 SG_ HVESP01_estOcv_132_7 m32: 50|14@1+ (0.001,0) [0|16.383] "Ah"  HVESP01
 SG_ HVESP01_estOcv_133_7 m33: 8|14@1+ (0.001,0) [0|16.383] "Ah"  HVESP01
 SG_ HVESP01_estOcv_134_7 m33: 22|14@1+ (0.001,0) [0|16.383] "Ah"  HVESP01
 SG_ HVESP01_estOcv_135_7 m33: 36|14@1+ (0.001,0) [0|16.383] "Ah"  HVESP01
 SG_ HVESP01_estOcv_136_7 m33: 50|14@1+ (0.001,0) [0|16.383] "Ah"  HVESP01
 SG_ HVESP01_estOcv_137_7 m34: 8|14@1+ (0.001,0) [0|16.383] "Ah"  HVESP01
 SG_ HVESP01_estOcv_138_7 m34: 22|14@1+ (0.001,0) [0|16.383] "Ah"  HVESP01
 SG_ HVESP01_estOcv_139_7 m34: 36|14@1+ (0.001,0) [0|16.383] "Ah"  HVESP01
 SG_ HVESP01_estOcv_140_7 m34: 50|14@1+ (0.001,0) [0|16.383] "Ah"  HVESP01
 SG_ HVESP01_estOcv_141_7 m35: 8|14@1+ (0.001,0) [0|16.383] "Ah"  HVESP01
 SG_ HVESP01_estOcv_142_7 m35: 22|14@1+ (0.001,0) [0|16.383] "Ah"  HVESP01
 SG_ HVESP01_estOcv_143_7 m35: 36|14@1+ (0.001,0) [0|16.383] "Ah"  HVESP01
 SG_ HVESP01_estOcv_144_7 m35: 50|14@1+ (0.001,0) [0|16.383] "Ah"  HVESP01
 SG_ HVESP01_estOcv_145_7 m36: 8|14@1+ (0.001,0) [0|16.383] "Ah"  HVESP01
 SG_ HVESP01_estOcv_146_7 m36: 22|14@1+ (0.001,0) [0|16.383] "Ah"  HVESP01
 SG_ HVESP01_estOcv_147_7 m36: 36|14@1+ (0.001,0) [0|16.383] "Ah"  HVESP01
 SG_ HVESP01_estOcv_148_7 m36: 50|14@1+ (0.001,0) [0|16.383] "Ah"  HVESP01
 SG_ HVESP01_estOcv_149_7 m37: 8|14@1+ (0.001,0) [0|16.383] "Ah"  HVESP01
 SG_ HVESP01_estOcv_150_7 m37: 22|14@1+ (0.001,0) [0|16.383] "Ah"  HVESP01
 SG_ HVESP01_estOcv_151_7 m37: 36|14@1+ (0.001,0) [0|16.383] "Ah"  HVESP01
 SG_ HVESP01_estOcv_152_7 m37: 50|14@1+ (0.001,0) [0|16.383] "Ah"  HVESP01
 SG_ HVESP01_estOcv_153_7 m38: 8|14@1+ (0.001,0) [0|16.383] "Ah"  HVESP01
 SG_ HVESP01_estOcv_154_7 m38: 22|14@1+ (0.001,0) [0|16.383] "Ah"  HVESP01
 SG_ HVESP01_estOcv_155_7 m38: 36|14@1+ (0.001,0) [0|16.383] "Ah"  HVESP01
 SG_ HVESP01_estOcv_156_7 m38: 50|14@1+ (0.001,0) [0|16.383] "Ah"  HVESP01
 SG_ HVESP01_estOcv_157_7 m39: 8|14@1+ (0.001,0) [0|16.383] "Ah"  HVESP01
 SG_ HVESP01_estOcv_158_7 m39: 22|14@1+ (0.001,0) [0|16.383] "Ah"  HVESP01
 SG_ HVESP01_estOcv_159_7 m39: 36|14@1+ (0.001,0) [0|16.383] "Ah"  HVESP01
 SG_ HVESP01_estOcv_160_7 m39: 50|14@1+ (0.001,0) [0|16.383] "Ah"  HVESP01
 SG_ HVESP01_estOcv_161_7 m40: 8|14@1+ (0.001,0) [0|16.383] "Ah"  HVESP01
 SG_ HVESP01_estOcv_162_7 m40: 22|14@1+ (0.001,0) [0|16.383] "Ah"  HVESP01
 SG_ HVESP01_estOcv_163_7 m40: 36|14@1+ (0.001,0) [0|16.383] "Ah"  HVESP01
 SG_ HVESP01_estOcv_164_7 m40: 50|14@1+ (0.001,0) [0|16.383] "Ah"  HVESP01
 SG_ HVESP01_estOcv_165_7 m41: 8|14@1+ (0.001,0) [0|16.383] "Ah"  HVESP01
 SG_ HVESP01_estOcv_166_7 m41: 22|14@1+ (0.001,0) [0|16.383] "Ah"  HVESP01
 SG_ HVESP01_estOcv_167_7 m41: 36|14@1+ (0.001,0) [0|16.383] "Ah"  HVESP01
 SG_ HVESP01_estOcv_168_7 m41: 50|14@1+ (0.001,0) [0|16.383] "Ah"  HVESP01
 SG_ HVESP01_estOcv_169_7 m42: 8|14@1+ (0.001,0) [0|16.383] "Ah"  HVESP01
 SG_ HVESP01_estOcv_170_7 m42: 22|14@1+ (0.001,0) [0|16.383] "Ah"  HVESP01
 SG_ HVESP01_estOcv_171_7 m42: 36|14@1+ (0.001,0) [0|16.383] "Ah"  HVESP01
 SG_ HVESP01_estOcv_172_7 m42: 50|14@1+ (0.001,0) [0|16.383] "Ah"  HVESP01
 SG_ HVESP01_estOcv_173_7 m43: 8|14@1+ (0.001,0) [0|16.383] "Ah"  HVESP01
 SG_ HVESP01_estOcv_174_7 m43: 22|14@1+ (0.001,0) [0|16.383] "Ah"  HVESP01
 SG_ HVESP01_estOcv_175_7 m43: 36|14@1+ (0.001,0) [0|16.383] "Ah"  HVESP01
 SG_ HVESP01_estOcv_176_7 m43: 50|14@1+ (0.001,0) [0|16.383] "Ah"  HVESP01
 SG_ HVESP01_estOcv_177_7 m44: 8|14@1+ (0.001,0) [0|16.383] "Ah"  HVESP01
 SG_ HVESP01_estOcv_178_7 m44: 22|14@1+ (0.001,0) [0|16.383] "Ah"  HVESP01
 SG_ HVESP01_estOcv_179_7 m44: 36|14@1+ (0.001,0) [0|16.383] "Ah"  HVESP01
 SG_ HVESP01_estOcv_180_7 m44: 50|14@1+ (0.001,0) [0|16.383] "Ah"  HVESP01
 SG_ HVESP01_estOcv_181_7 m45: 8|14@1+ (0.001,0) [0|16.383] "Ah"  HVESP01
 SG_ HVESP01_estOcv_182_7 m45: 22|14@1+ (0.001,0) [0|16.383] "Ah"  HVESP01
 SG_ HVESP01_estOcv_183_7 m45: 36|14@1+ (0.001,0) [0|16.383] "Ah"  HVESP01
 SG_ HVESP01_estOcv_184_7 m45: 50|14@1+ (0.001,0) [0|16.383] "Ah"  HVESP01
 SG_ HVESP01_estOcv_185_7 m46: 8|14@1+ (0.001,0) [0|16.383] "Ah"  HVESP01
 SG_ HVESP01_estOcv_186_7 m46: 22|14@1+ (0.001,0) [0|16.383] "Ah"  HVESP01
 SG_ HVESP01_estOcv_187_7 m46: 36|14@1+ (0.001,0) [0|16.383] "Ah"  HVESP01
 SG_ HVESP01_estOcv_188_7 m46: 50|14@1+ (0.001,0) [0|16.383] "Ah"  HVESP01
 SG_ HVESP01_estOcv_189_7 m47: 8|14@1+ (0.001,0) [0|16.383] "Ah"  HVESP01
 SG_ HVESP01_estOcv_190_7 m47: 22|14@1+ (0.001,0) [0|16.383] "Ah"  HVESP01
 SG_ HVESP01_estOcv_191_7 m47: 36|14@1+ (0.001,0) [0|16.383] "Ah"  HVESP01
 SG_ HVESP01_estOcv_192_7 m47: 50|14@1+ (0.001,0) [0|16.383] "Ah"  HVESP01
 SG_ multiplexoreo_7 M: 0|8@1+ (1,0) [0|255] ""  HVESP01

BO_ 2499750252 HVESP01_EstOcv_8: 8 HVESP01
 SG_ HVESP01_estOcv_01_8 m0: 8|14@1+ (0.001,0) [0|16.383] "Ah"  HVESP01
 SG_ HVESP01_estOcv_02_8 m0: 22|14@1+ (0.001,0) [0|16.383] "Ah"  HVESP01
 SG_ HVESP01_estOcv_03_8 m0: 36|14@1+ (0.001,0) [0|16.383] "Ah"  HVESP01
 SG_ HVESP01_estOcv_04_8 m0: 50|14@1+ (0.001,0) [0|16.383] "Ah"  HVESP01
 SG_ HVESP01_estOcv_05_8 m1: 8|14@1+ (0.001,0) [0|16.383] "Ah"  HVESP01
 SG_ HVESP01_estOcv_06_8 m1: 22|14@1+ (0.001,0) [0|16.383] "Ah"  HVESP01
 SG_ HVESP01_estOcv_07_8 m1: 36|14@1+ (0.001,0) [0|16.383] "Ah"  HVESP01
 SG_ HVESP01_estOcv_08_8 m1: 50|14@1+ (0.001,0) [0|16.383] "Ah"  HVESP01
 SG_ HVESP01_estOcv_09_8 m2: 8|14@1+ (0.001,0) [0|16.383] "Ah"  HVESP01
 SG_ HVESP01_estOcv_10_8 m2: 22|14@1+ (0.001,0) [0|16.383] "Ah"  HVESP01
 SG_ HVESP01_estOcv_11_8 m2: 36|14@1+ (0.001,0) [0|16.383] "Ah"  HVESP01
 SG_ HVESP01_estOcv_12_8 m2: 50|14@1+ (0.001,0) [0|16.383] "Ah"  HVESP01
 SG_ HVESP01_estOcv_13_8 m3: 8|14@1+ (0.001,0) [0|16.383] "Ah"  HVESP01
 SG_ HVESP01_estOcv_14_8 m3: 22|14@1+ (0.001,0) [0|16.383] "Ah"  HVESP01
 SG_ HVESP01_estOcv_15_8 m3: 36|14@1+ (0.001,0) [0|16.383] "Ah"  HVESP01
 SG_ HVESP01_estOcv_16_8 m3: 50|14@1+ (0.001,0) [0|16.383] "Ah"  HVESP01
 SG_ HVESP01_estOcv_17_8 m4: 8|14@1+ (0.001,0) [0|16.383] "Ah"  HVESP01
 SG_ HVESP01_estOcv_18_8 m4: 22|14@1+ (0.001,0) [0|16.383] "Ah"  HVESP01
 SG_ HVESP01_estOcv_19_8 m4: 36|14@1+ (0.001,0) [0|16.383] "Ah"  HVESP01
 SG_ HVESP01_estOcv_20_8 m4: 50|14@1+ (0.001,0) [0|16.383] "Ah"  HVESP01
 SG_ HVESP01_estOcv_21_8 m5: 8|14@1+ (0.001,0) [0|16.383] "Ah"  HVESP01
 SG_ HVESP01_estOcv_22_8 m5: 22|14@1+ (0.001,0) [0|16.383] "Ah"  HVESP01
 SG_ HVESP01_estOcv_23_8 m5: 36|14@1+ (0.001,0) [0|16.383] "Ah"  HVESP01
 SG_ HVESP01_estOcv_24_8 m5: 50|14@1+ (0.001,0) [0|16.383] "Ah"  HVESP01
 SG_ HVESP01_estOcv_25_8 m6: 8|14@1+ (0.001,0) [0|16.383] "Ah"  HVESP01
 SG_ HVESP01_estOcv_26_8 m6: 22|14@1+ (0.001,0) [0|16.383] "Ah"  HVESP01
 SG_ HVESP01_estOcv_27_8 m6: 36|14@1+ (0.001,0) [0|16.383] "Ah"  HVESP01
 SG_ HVESP01_estOcv_28_8 m6: 50|14@1+ (0.001,0) [0|16.383] "Ah"  HVESP01
 SG_ HVESP01_estOcv_29_8 m7: 8|14@1+ (0.001,0) [0|16.383] "Ah"  HVESP01
 SG_ HVESP01_estOcv_30_8 m7: 22|14@1+ (0.001,0) [0|16.383] "Ah"  HVESP01
 SG_ HVESP01_estOcv_31_8 m7: 36|14@1+ (0.001,0) [0|16.383] "Ah"  HVESP01
 SG_ HVESP01_estOcv_32_8 m7: 50|14@1+ (0.001,0) [0|16.383] "Ah"  HVESP01
 SG_ HVESP01_estOcv_33_8 m8: 8|14@1+ (0.001,0) [0|16.383] "Ah"  HVESP01
 SG_ HVESP01_estOcv_34_8 m8: 22|14@1+ (0.001,0) [0|16.383] "Ah"  HVESP01
 SG_ HVESP01_estOcv_35_8 m8: 36|14@1+ (0.001,0) [0|16.383] "Ah"  HVESP01
 SG_ HVESP01_estOcv_36_8 m8: 50|14@1+ (0.001,0) [0|16.383] "Ah"  HVESP01
 SG_ HVESP01_estOcv_37_8 m9: 8|14@1+ (0.001,0) [0|16.383] "Ah"  HVESP01
 SG_ HVESP01_estOcv_38_8 m9: 22|14@1+ (0.001,0) [0|16.383] "Ah"  HVESP01
 SG_ HVESP01_estOcv_39_8 m9: 36|14@1+ (0.001,0) [0|16.383] "Ah"  HVESP01
 SG_ HVESP01_estOcv_40_8 m9: 50|14@1+ (0.001,0) [0|16.383] "Ah"  HVESP01
 SG_ HVESP01_estOcv_41_8 m10: 8|14@1+ (0.001,0) [0|16.383] "Ah"  HVESP01
 SG_ HVESP01_estOcv_42_8 m10: 22|14@1+ (0.001,0) [0|16.383] "Ah"  HVESP01
 SG_ HVESP01_estOcv_43_8 m10: 36|14@1+ (0.001,0) [0|16.383] "Ah"  HVESP01
 SG_ HVESP01_estOcv_44_8 m10: 50|14@1+ (0.001,0) [0|16.383] "Ah"  HVESP01
 SG_ HVESP01_estOcv_45_8 m11: 8|14@1+ (0.001,0) [0|16.383] "Ah"  HVESP01
 SG_ HVESP01_estOcv_46_8 m11: 22|14@1+ (0.001,0) [0|16.383] "Ah"  HVESP01
 SG_ HVESP01_estOcv_47_8 m11: 36|14@1+ (0.001,0) [0|16.383] "Ah"  HVESP01
 SG_ HVESP01_estOcv_48_8 m11: 50|14@1+ (0.001,0) [0|16.383] "Ah"  HVESP01
 SG_ HVESP01_estOcv_49_8 m12: 8|14@1+ (0.001,0) [0|16.383] "Ah"  HVESP01
 SG_ HVESP01_estOcv_50_8 m12: 22|14@1+ (0.001,0) [0|16.383] "Ah"  HVESP01
 SG_ HVESP01_estOcv_51_8 m12: 36|14@1+ (0.001,0) [0|16.383] "Ah"  HVESP01
 SG_ HVESP01_estOcv_52_8 m12: 50|14@1+ (0.001,0) [0|16.383] "Ah"  HVESP01
 SG_ HVESP01_estOcv_53_8 m13: 8|14@1+ (0.001,0) [0|16.383] "Ah"  HVESP01
 SG_ HVESP01_estOcv_54_8 m13: 22|14@1+ (0.001,0) [0|16.383] "Ah"  HVESP01
 SG_ HVESP01_estOcv_55_8 m13: 36|14@1+ (0.001,0) [0|16.383] "Ah"  HVESP01
 SG_ HVESP01_estOcv_56_8 m13: 50|14@1+ (0.001,0) [0|16.383] "Ah"  HVESP01
 SG_ HVESP01_estOcv_57_8 m14: 8|14@1+ (0.001,0) [0|16.383] "Ah"  HVESP01
 SG_ HVESP01_estOcv_58_8 m14: 22|14@1+ (0.001,0) [0|16.383] "Ah"  HVESP01
 SG_ HVESP01_estOcv_59_8 m14: 36|14@1+ (0.001,0) [0|16.383] "Ah"  HVESP01
 SG_ HVESP01_estOcv_60_8 m14: 50|14@1+ (0.001,0) [0|16.383] "Ah"  HVESP01
 SG_ HVESP01_estOcv_61_8 m15: 8|14@1+ (0.001,0) [0|16.383] "Ah"  HVESP01
 SG_ HVESP01_estOcv_62_8 m15: 22|14@1+ (0.001,0) [0|16.383] "Ah"  HVESP01
 SG_ HVESP01_estOcv_63_8 m15: 36|14@1+ (0.001,0) [0|16.383] "Ah"  HVESP01
 SG_ HVESP01_estOcv_64_8 m15: 50|14@1+ (0.001,0) [0|16.383] "Ah"  HVESP01
 SG_ HVESP01_estOcv_65_8 m16: 8|14@1+ (0.001,0) [0|16.383] "Ah"  HVESP01
 SG_ HVESP01_estOcv_66_8 m16: 22|14@1+ (0.001,0) [0|16.383] "Ah"  HVESP01
 SG_ HVESP01_estOcv_67_8 m16: 36|14@1+ (0.001,0) [0|16.383] "Ah"  HVESP01
 SG_ HVESP01_estOcv_68_8 m16: 50|14@1+ (0.001,0) [0|16.383] "Ah"  HVESP01
 SG_ HVESP01_estOcv_69_8 m17: 8|14@1+ (0.001,0) [0|16.383] "Ah"  HVESP01
 SG_ HVESP01_estOcv_70_8 m17: 22|14@1+ (0.001,0) [0|16.383] "Ah"  HVESP01
 SG_ HVESP01_estOcv_71_8 m17: 36|14@1+ (0.001,0) [0|16.383] "Ah"  HVESP01
 SG_ HVESP01_estOcv_72_8 m17: 50|14@1+ (0.001,0) [0|16.383] "Ah"  HVESP01
 SG_ HVESP01_estOcv_73_8 m18: 8|14@1+ (0.001,0) [0|16.383] "Ah"  HVESP01
 SG_ HVESP01_estOcv_74_8 m18: 22|14@1+ (0.001,0) [0|16.383] "Ah"  HVESP01
 SG_ HVESP01_estOcv_75_8 m18: 36|14@1+ (0.001,0) [0|16.383] "Ah"  HVESP01
 SG_ HVESP01_estOcv_76_8 m18: 50|14@1+ (0.001,0) [0|16.383] "Ah"  HVESP01
 SG_ HVESP01_estOcv_77_8 m19: 8|14@1+ (0.001,0) [0|16.383] "Ah"  HVESP01
 SG_ HVESP01_estOcv_78_8 m19: 22|14@1+ (0.001,0) [0|16.383] "Ah"  HVESP01
 SG_ HVESP01_estOcv_79_8 m19: 36|14@1+ (0.001,0) [0|16.383] "Ah"  HVESP01
 SG_ HVESP01_estOcv_80_8 m19: 50|14@1+ (0.001,0) [0|16.383] "Ah"  HVESP01
 SG_ HVESP01_estOcv_81_8 m20: 8|14@1+ (0.001,0) [0|16.383] "Ah"  HVESP01
 SG_ HVESP01_estOcv_82_8 m20: 22|14@1+ (0.001,0) [0|16.383] "Ah"  HVESP01
 SG_ HVESP01_estOcv_83_8 m20: 36|14@1+ (0.001,0) [0|16.383] "Ah"  HVESP01
 SG_ HVESP01_estOcv_84_8 m20: 50|14@1+ (0.001,0) [0|16.383] "Ah"  HVESP01
 SG_ HVESP01_estOcv_85_8 m21: 8|14@1+ (0.001,0) [0|16.383] "Ah"  HVESP01
 SG_ HVESP01_estOcv_86_8 m21: 22|14@1+ (0.001,0) [0|16.383] "Ah"  HVESP01
 SG_ HVESP01_estOcv_87_8 m21: 36|14@1+ (0.001,0) [0|16.383] "Ah"  HVESP01
 SG_ HVESP01_estOcv_88_8 m21: 50|14@1+ (0.001,0) [0|16.383] "Ah"  HVESP01
 SG_ HVESP01_estOcv_89_8 m22: 8|14@1+ (0.001,0) [0|16.383] "Ah"  HVESP01
 SG_ HVESP01_estOcv_90_8 m22: 22|14@1+ (0.001,0) [0|16.383] "Ah"  HVESP01
 SG_ HVESP01_estOcv_91_8 m22: 36|14@1+ (0.001,0) [0|16.383] "Ah"  HVESP01
 SG_ HVESP01_estOcv_92_8 m22: 50|14@1+ (0.001,0) [0|16.383] "Ah"  HVESP01
 SG_ HVESP01_estOcv_93_8 m23: 8|14@1+ (0.001,0) [0|16.383] "Ah"  HVESP01
 SG_ HVESP01_estOcv_94_8 m23: 22|14@1+ (0.001,0) [0|16.383] "Ah"  HVESP01
 SG_ HVESP01_estOcv_95_8 m23: 36|14@1+ (0.001,0) [0|16.383] "Ah"  HVESP01
 SG_ HVESP01_estOcv_96_8 m23: 50|14@1+ (0.001,0) [0|16.383] "Ah"  HVESP01
 SG_ HVESP01_estOcv_97_8 m24: 8|14@1+ (0.001,0) [0|16.383] "Ah"  HVESP01
 SG_ HVESP01_estOcv_98_8 m24: 22|14@1+ (0.001,0) [0|16.383] "Ah"  HVESP01
 SG_ HVESP01_estOcv_99_8 m24: 36|14@1+ (0.001,0) [0|16.383] "Ah"  HVESP01
 SG_ HVESP01_estOcv_100_8 m24: 50|14@1+ (0.001,0) [0|16.383] "Ah"  HVESP01
 SG_ HVESP01_estOcv_101_8 m25: 8|14@1+ (0.001,0) [0|16.383] "Ah"  HVESP01
 SG_ HVESP01_estOcv_102_8 m25: 22|14@1+ (0.001,0) [0|16.383] "Ah"  HVESP01
 SG_ HVESP01_estOcv_103_8 m25: 36|14@1+ (0.001,0) [0|16.383] "Ah"  HVESP01
 SG_ HVESP01_estOcv_104_8 m25: 50|14@1+ (0.001,0) [0|16.383] "Ah"  HVESP01
 SG_ HVESP01_estOcv_105_8 m26: 8|14@1+ (0.001,0) [0|16.383] "Ah"  HVESP01
 SG_ HVESP01_estOcv_106_8 m26: 22|14@1+ (0.001,0) [0|16.383] "Ah"  HVESP01
 SG_ HVESP01_estOcv_107_8 m26: 36|14@1+ (0.001,0) [0|16.383] "Ah"  HVESP01
 SG_ HVESP01_estOcv_108_8 m26: 50|14@1+ (0.001,0) [0|16.383] "Ah"  HVESP01
 SG_ HVESP01_estOcv_109_8 m27: 8|14@1+ (0.001,0) [0|16.383] "Ah"  HVESP01
 SG_ HVESP01_estOcv_110_8 m27: 22|14@1+ (0.001,0) [0|16.383] "Ah"  HVESP01
 SG_ HVESP01_estOcv_111_8 m27: 36|14@1+ (0.001,0) [0|16.383] "Ah"  HVESP01
 SG_ HVESP01_estOcv_112_8 m27: 50|14@1+ (0.001,0) [0|16.383] "Ah"  HVESP01
 SG_ HVESP01_estOcv_113_8 m28: 8|14@1+ (0.001,0) [0|16.383] "Ah"  HVESP01
 SG_ HVESP01_estOcv_114_8 m28: 22|14@1+ (0.001,0) [0|16.383] "Ah"  HVESP01
 SG_ HVESP01_estOcv_115_8 m28: 36|14@1+ (0.001,0) [0|16.383] "Ah"  HVESP01
 SG_ HVESP01_estOcv_116_8 m28: 50|14@1+ (0.001,0) [0|16.383] "Ah"  HVESP01
 SG_ HVESP01_estOcv_117_8 m29: 8|14@1+ (0.001,0) [0|16.383] "Ah"  HVESP01
 SG_ HVESP01_estOcv_118_8 m29: 22|14@1+ (0.001,0) [0|16.383] "Ah"  HVESP01
 SG_ HVESP01_estOcv_119_8 m29: 36|14@1+ (0.001,0) [0|16.383] "Ah"  HVESP01
 SG_ HVESP01_estOcv_120_8 m29: 50|14@1+ (0.001,0) [0|16.383] "Ah"  HVESP01
 SG_ HVESP01_estOcv_121_8 m30: 8|14@1+ (0.001,0) [0|16.383] "Ah"  HVESP01
 SG_ HVESP01_estOcv_122_8 m30: 22|14@1+ (0.001,0) [0|16.383] "Ah"  HVESP01
 SG_ HVESP01_estOcv_123_8 m30: 36|14@1+ (0.001,0) [0|16.383] "Ah"  HVESP01
 SG_ HVESP01_estOcv_124_8 m30: 50|14@1+ (0.001,0) [0|16.383] "Ah"  HVESP01
 SG_ HVESP01_estOcv_125_8 m31: 8|14@1+ (0.001,0) [0|16.383] "Ah"  HVESP01
 SG_ HVESP01_estOcv_126_8 m31: 22|14@1+ (0.001,0) [0|16.383] "Ah"  HVESP01
 SG_ HVESP01_estOcv_127_8 m31: 36|14@1+ (0.001,0) [0|16.383] "Ah"  HVESP01
 SG_ HVESP01_estOcv_128_8 m31: 50|14@1+ (0.001,0) [0|16.383] "Ah"  HVESP01
 SG_ HVESP01_estOcv_129_8 m32: 8|14@1+ (0.001,0) [0|16.383] "Ah"  HVESP01
 SG_ HVESP01_estOcv_130_8 m32: 22|14@1+ (0.001,0) [0|16.383] "Ah"  HVESP01
 SG_ HVESP01_estOcv_131_8 m32: 36|14@1+ (0.001,0) [0|16.383] "Ah"  HVESP01
 SG_ HVESP01_estOcv_132_8 m32: 50|14@1+ (0.001,0) [0|16.383] "Ah"  HVESP01
 SG_ HVESP01_estOcv_133_8 m33: 8|14@1+ (0.001,0) [0|16.383] "Ah"  HVESP01
 SG_ HVESP01_estOcv_134_8 m33: 22|14@1+ (0.001,0) [0|16.383] "Ah"  HVESP01
 SG_ HVESP01_estOcv_135_8 m33: 36|14@1+ (0.001,0) [0|16.383] "Ah"  HVESP01
 SG_ HVESP01_estOcv_136_8 m33: 50|14@1+ (0.001,0) [0|16.383] "Ah"  HVESP01
 SG_ HVESP01_estOcv_137_8 m34: 8|14@1+ (0.001,0) [0|16.383] "Ah"  HVESP01
 SG_ HVESP01_estOcv_138_8 m34: 22|14@1+ (0.001,0) [0|16.383] "Ah"  HVESP01
 SG_ HVESP01_estOcv_139_8 m34: 36|14@1+ (0.001,0) [0|16.383] "Ah"  HVESP01
 SG_ HVESP01_estOcv_140_8 m34: 50|14@1+ (0.001,0) [0|16.383] "Ah"  HVESP01
 SG_ HVESP01_estOcv_141_8 m35: 8|14@1+ (0.001,0) [0|16.383] "Ah"  HVESP01
 SG_ HVESP01_estOcv_142_8 m35: 22|14@1+ (0.001,0) [0|16.383] "Ah"  HVESP01
 SG_ HVESP01_estOcv_143_8 m35: 36|14@1+ (0.001,0) [0|16.383] "Ah"  HVESP01
 SG_ HVESP01_estOcv_144_8 m35: 50|14@1+ (0.001,0) [0|16.383] "Ah"  HVESP01
 SG_ HVESP01_estOcv_145_8 m36: 8|14@1+ (0.001,0) [0|16.383] "Ah"  HVESP01
 SG_ HVESP01_estOcv_146_8 m36: 22|14@1+ (0.001,0) [0|16.383] "Ah"  HVESP01
 SG_ HVESP01_estOcv_147_8 m36: 36|14@1+ (0.001,0) [0|16.383] "Ah"  HVESP01
 SG_ HVESP01_estOcv_148_8 m36: 50|14@1+ (0.001,0) [0|16.383] "Ah"  HVESP01
 SG_ HVESP01_estOcv_149_8 m37: 8|14@1+ (0.001,0) [0|16.383] "Ah"  HVESP01
 SG_ HVESP01_estOcv_150_8 m37: 22|14@1+ (0.001,0) [0|16.383] "Ah"  HVESP01
 SG_ HVESP01_estOcv_151_8 m37: 36|14@1+ (0.001,0) [0|16.383] "Ah"  HVESP01
 SG_ HVESP01_estOcv_152_8 m37: 50|14@1+ (0.001,0) [0|16.383] "Ah"  HVESP01
 SG_ HVESP01_estOcv_153_8 m38: 8|14@1+ (0.001,0) [0|16.383] "Ah"  HVESP01
 SG_ HVESP01_estOcv_154_8 m38: 22|14@1+ (0.001,0) [0|16.383] "Ah"  HVESP01
 SG_ HVESP01_estOcv_155_8 m38: 36|14@1+ (0.001,0) [0|16.383] "Ah"  HVESP01
 SG_ HVESP01_estOcv_156_8 m38: 50|14@1+ (0.001,0) [0|16.383] "Ah"  HVESP01
 SG_ HVESP01_estOcv_157_8 m39: 8|14@1+ (0.001,0) [0|16.383] "Ah"  HVESP01
 SG_ HVESP01_estOcv_158_8 m39: 22|14@1+ (0.001,0) [0|16.383] "Ah"  HVESP01
 SG_ HVESP01_estOcv_159_8 m39: 36|14@1+ (0.001,0) [0|16.383] "Ah"  HVESP01
 SG_ HVESP01_estOcv_160_8 m39: 50|14@1+ (0.001,0) [0|16.383] "Ah"  HVESP01
 SG_ HVESP01_estOcv_161_8 m40: 8|14@1+ (0.001,0) [0|16.383] "Ah"  HVESP01
 SG_ HVESP01_estOcv_162_8 m40: 22|14@1+ (0.001,0) [0|16.383] "Ah"  HVESP01
 SG_ HVESP01_estOcv_163_8 m40: 36|14@1+ (0.001,0) [0|16.383] "Ah"  HVESP01
 SG_ HVESP01_estOcv_164_8 m40: 50|14@1+ (0.001,0) [0|16.383] "Ah"  HVESP01
 SG_ HVESP01_estOcv_165_8 m41: 8|14@1+ (0.001,0) [0|16.383] "Ah"  HVESP01
 SG_ HVESP01_estOcv_166_8 m41: 22|14@1+ (0.001,0) [0|16.383] "Ah"  HVESP01
 SG_ HVESP01_estOcv_167_8 m41: 36|14@1+ (0.001,0) [0|16.383] "Ah"  HVESP01
 SG_ HVESP01_estOcv_168_8 m41: 50|14@1+ (0.001,0) [0|16.383] "Ah"  HVESP01
 SG_ HVESP01_estOcv_169_8 m42: 8|14@1+ (0.001,0) [0|16.383] "Ah"  HVESP01
 SG_ HVESP01_estOcv_170_8 m42: 22|14@1+ (0.001,0) [0|16.383] "Ah"  HVESP01
 SG_ HVESP01_estOcv_171_8 m42: 36|14@1+ (0.001,0) [0|16.383] "Ah"  HVESP01
 SG_ HVESP01_estOcv_172_8 m42: 50|14@1+ (0.001,0) [0|16.383] "Ah"  HVESP01
 SG_ HVESP01_estOcv_173_8 m43: 8|14@1+ (0.001,0) [0|16.383] "Ah"  HVESP01
 SG_ HVESP01_estOcv_174_8 m43: 22|14@1+ (0.001,0) [0|16.383] "Ah"  HVESP01
 SG_ HVESP01_estOcv_175_8 m43: 36|14@1+ (0.001,0) [0|16.383] "Ah"  HVESP01
 SG_ HVESP01_estOcv_176_8 m43: 50|14@1+ (0.001,0) [0|16.383] "Ah"  HVESP01
 SG_ HVESP01_estOcv_177_8 m44: 8|14@1+ (0.001,0) [0|16.383] "Ah"  HVESP01
 SG_ HVESP01_estOcv_178_8 m44: 22|14@1+ (0.001,0) [0|16.383] "Ah"  HVESP01
 SG_ HVESP01_estOcv_179_8 m44: 36|14@1+ (0.001,0) [0|16.383] "Ah"  HVESP01
 SG_ HVESP01_estOcv_180_8 m44: 50|14@1+ (0.001,0) [0|16.383] "Ah"  HVESP01
 SG_ HVESP01_estOcv_181_8 m45: 8|14@1+ (0.001,0) [0|16.383] "Ah"  HVESP01
 SG_ HVESP01_estOcv_182_8 m45: 22|14@1+ (0.001,0) [0|16.383] "Ah"  HVESP01
 SG_ HVESP01_estOcv_183_8 m45: 36|14@1+ (0.001,0) [0|16.383] "Ah"  HVESP01
 SG_ HVESP01_estOcv_184_8 m45: 50|14@1+ (0.001,0) [0|16.383] "Ah"  HVESP01
 SG_ HVESP01_estOcv_185_8 m46: 8|14@1+ (0.001,0) [0|16.383] "Ah"  HVESP01
 SG_ HVESP01_estOcv_186_8 m46: 22|14@1+ (0.001,0) [0|16.383] "Ah"  HVESP01
 SG_ HVESP01_estOcv_187_8 m46: 36|14@1+ (0.001,0) [0|16.383] "Ah"  HVESP01
 SG_ HVESP01_estOcv_188_8 m46: 50|14@1+ (0.001,0) [0|16.383] "Ah"  HVESP01
 SG_ HVESP01_estOcv_189_8 m47: 8|14@1+ (0.001,0) [0|16.383] "Ah"  HVESP01
 SG_ HVESP01_estOcv_190_8 m47: 22|14@1+ (0.001,0) [0|16.383] "Ah"  HVESP01
 SG_ HVESP01_estOcv_191_8 m47: 36|14@1+ (0.001,0) [0|16.383] "Ah"  HVESP01
 SG_ HVESP01_estOcv_192_8 m47: 50|14@1+ (0.001,0) [0|16.383] "Ah"  HVESP01
 SG_ multiplexoreo_8 M: 0|8@1+ (1,0) [0|255] ""  HVESP01

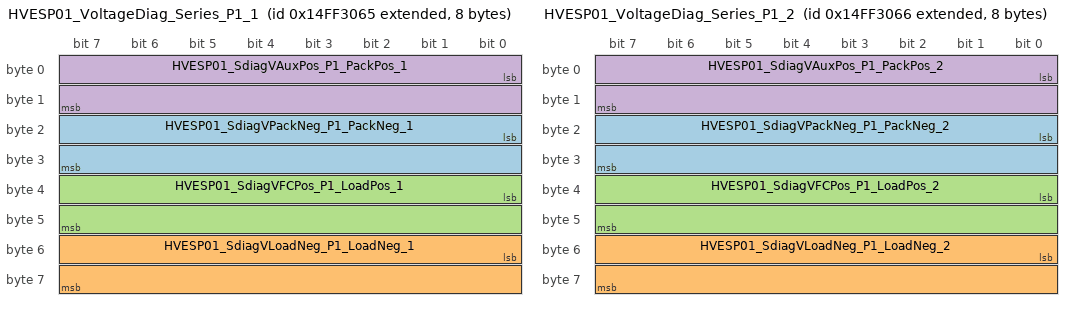
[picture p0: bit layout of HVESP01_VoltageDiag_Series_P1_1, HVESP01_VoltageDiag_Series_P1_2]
BO_ 2499752037 HVESP01_VoltageDiag_Series_P1_1: 8 HVESP01
 SG_ HVESP01_SdiagVPackNeg_P1_PackNeg_1 : 16|16@1+ (0.01,0) [0|655.35] "v"  HVESP01
 SG_ HVESP01_SdiagVLoadNeg_P1_LoadNeg_1 : 48|16@1+ (0.01,0) [0|655.35] "v"  HVESP01
 SG_ HVESP01_SdiagVFCPos_P1_LoadPos_1 : 32|16@1+ (0.01,0) [0|655.35] "v"  HVESP01
 SG_ HVESP01_SdiagVAuxPos_P1_PackPos_1 : 0|16@1+ (0.01,0) [0|655.35] "v"  HVESP01

BO_ 2499752038 HVESP01_VoltageDiag_Series_P1_2: 8 HVESP01
 SG_ HVESP01_SdiagVPackNeg_P1_PackNeg_2 : 16|16@1+ (0.01,0) [0|655.35] "v"  HVESP01
 SG_ HVESP01_SdiagVLoadNeg_P1_LoadNeg_2 : 48|16@1+ (0.01,0) [0|655.35] "v"  HVESP01
 SG_ HVESP01_SdiagVFCPos_P1_LoadPos_2 : 32|16@1+ (0.01,0) [0|655.35] "v"  HVESP01
 SG_ HVESP01_SdiagVAuxPos_P1_PackPos_2 : 0|16@1+ (0.01,0) [0|655.35] "v"  HVESP01

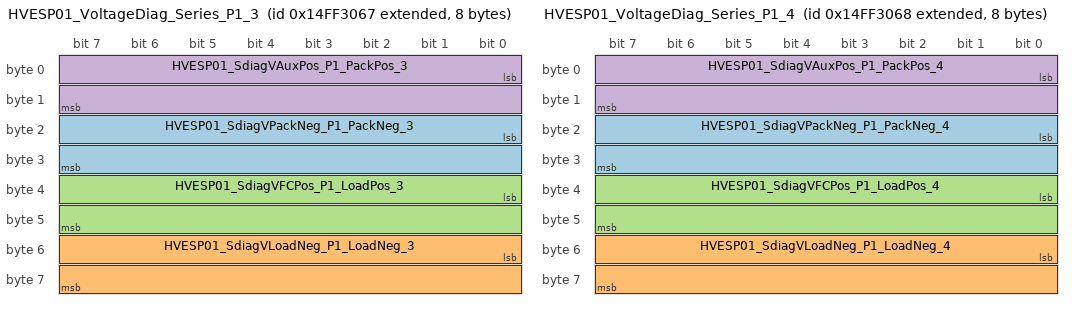
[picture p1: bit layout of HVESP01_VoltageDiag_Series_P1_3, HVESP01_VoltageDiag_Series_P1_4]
BO_ 2499752039 HVESP01_VoltageDiag_Series_P1_3: 8 HVESP01
 SG_ HVESP01_SdiagVPackNeg_P1_PackNeg_3 : 16|16@1+ (0.01,0) [0|655.35] "v"  HVESP01
 SG_ HVESP01_SdiagVLoadNeg_P1_LoadNeg_3 : 48|16@1+ (0.01,0) [0|655.35] "v"  HVESP01
 SG_ HVESP01_SdiagVFCPos_P1_LoadPos_3 : 32|16@1+ (0.01,0) [0|655.35] "v"  HVESP01
 SG_ HVESP01_SdiagVAuxPos_P1_PackPos_3 : 0|16@1+ (0.01,0) [0|655.35] "v"  HVESP01

BO_ 2499752040 HVESP01_VoltageDiag_Series_P1_4: 8 HVESP01
 SG_ HVESP01_SdiagVPackNeg_P1_PackNeg_4 : 16|16@1+ (0.01,0) [0|655.35] "v"  HVESP01
 SG_ HVESP01_SdiagVLoadNeg_P1_LoadNeg_4 : 48|16@1+ (0.01,0) [0|655.35] "v"  HVESP01
 SG_ HVESP01_SdiagVFCPos_P1_LoadPos_4 : 32|16@1+ (0.01,0) [0|655.35] "v"  HVESP01
 SG_ HVESP01_SdiagVAuxPos_P1_PackPos_4 : 0|16@1+ (0.01,0) [0|655.35] "v"  HVESP01

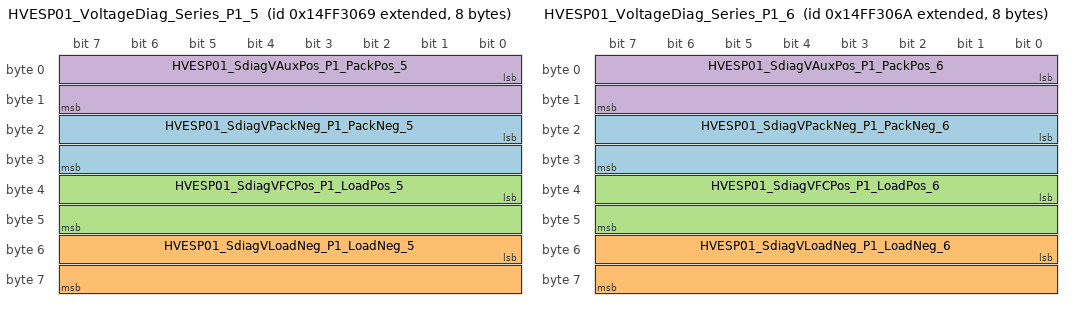
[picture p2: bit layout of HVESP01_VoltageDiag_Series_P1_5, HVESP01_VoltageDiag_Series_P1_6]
BO_ 2499752041 HVESP01_VoltageDiag_Series_P1_5: 8 HVESP01
 SG_ HVESP01_SdiagVPackNeg_P1_PackNeg_5 : 16|16@1+ (0.01,0) [0|655.35] "v"  HVESP01
 SG_ HVESP01_SdiagVLoadNeg_P1_LoadNeg_5 : 48|16@1+ (0.01,0) [0|655.35] "v"  HVESP01
 SG_ HVESP01_SdiagVFCPos_P1_LoadPos_5 : 32|16@1+ (0.01,0) [0|655.35] "v"  HVESP01
 SG_ HVESP01_SdiagVAuxPos_P1_PackPos_5 : 0|16@1+ (0.01,0) [0|655.35] "v"  HVESP01

BO_ 2499752042 HVESP01_VoltageDiag_Series_P1_6: 8 HVESP01
 SG_ HVESP01_SdiagVPackNeg_P1_PackNeg_6 : 16|16@1+ (0.01,0) [0|655.35] "v"  HVESP01
 SG_ HVESP01_SdiagVLoadNeg_P1_LoadNeg_6 : 48|16@1+ (0.01,0) [0|655.35] "v"  HVESP01
 SG_ HVESP01_SdiagVFCPos_P1_LoadPos_6 : 32|16@1+ (0.01,0) [0|655.35] "v"  HVESP01
 SG_ HVESP01_SdiagVAuxPos_P1_PackPos_6 : 0|16@1+ (0.01,0) [0|655.35] "v"  HVESP01

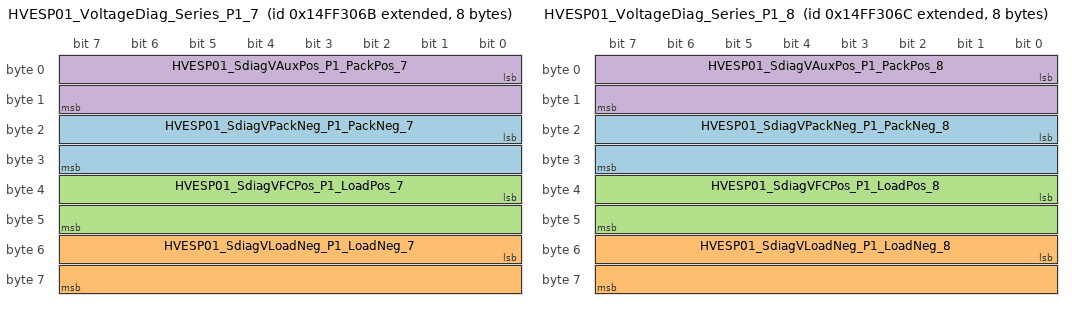
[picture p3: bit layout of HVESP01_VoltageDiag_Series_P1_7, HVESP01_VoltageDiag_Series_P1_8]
BO_ 2499752043 HVESP01_VoltageDiag_Series_P1_7: 8 HVESP01
 SG_ HVESP01_SdiagVPackNeg_P1_PackNeg_7 : 16|16@1+ (0.01,0) [0|655.35] "v"  HVESP01
 SG_ HVESP01_SdiagVLoadNeg_P1_LoadNeg_7 : 48|16@1+ (0.01,0) [0|655.35] "v"  HVESP01
 SG_ HVESP01_SdiagVFCPos_P1_LoadPos_7 : 32|16@1+ (0.01,0) [0|655.35] "v"  HVESP01
 SG_ HVESP01_SdiagVAuxPos_P1_PackPos_7 : 0|16@1+ (0.01,0) [0|655.35] "v"  HVESP01

BO_ 2499752044 HVESP01_VoltageDiag_Series_P1_8: 8 HVESP01
 SG_ HVESP01_SdiagVPackNeg_P1_PackNeg_8 : 16|16@1+ (0.01,0) [0|655.35] "v"  HVESP01
 SG_ HVESP01_SdiagVLoadNeg_P1_LoadNeg_8 : 48|16@1+ (0.01,0) [0|655.35] "v"  HVESP01
 SG_ HVESP01_SdiagVFCPos_P1_LoadPos_8 : 32|16@1+ (0.01,0) [0|655.35] "v"  HVESP01
 SG_ HVESP01_SdiagVAuxPos_P1_PackPos_8 : 0|16@1+ (0.01,0) [0|655.35] "v"  HVESP01

BO_ 2499756133 HVESP01_VoltageDiag_Series_P2_1: 8 HVESP01
 SG_ HVESP01_SdiagVPackPos_P2_PackPos_1 : 32|16@1+ (0.01,0) [0|655.35] "v"  HVESP01
 SG_ HVESP01_SdiagVLoadPos_P2_LoadPos_1 : 0|16@1+ (0.01,0) [0|655.35] "v"  HVESP01
 SG_ HVESP01_SdiagVFCNeg_P2_LoadNeg_1 : 48|16@1+ (0.01,0) [0|655.35] "v"  HVESP01
 SG_ HVESP01_SdiagVAuxNeg_P2_PackNeg_1 : 16|16@1+ (0.01,0) [0|655.35] "v"  HVESP01

BO_ 2499756134 HVESP01_VoltageDiag_Series_P2_2: 8 HVESP01
 SG_ HVESP01_SdiagVPackPos_P2_PackPos_2 : 32|16@1+ (0.01,0) [0|655.35] "v"  HVESP01
 SG_ HVESP01_SdiagVLoadPos_P2_LoadPos_2 : 0|16@1+ (0.01,0) [0|655.35] "v"  HVESP01
 SG_ HVESP01_SdiagVFCNeg_P2_LoadNeg_2 : 48|16@1+ (0.01,0) [0|655.35] "v"  HVESP01
 SG_ HVESP01_SdiagVAuxNeg_P2_PackNeg_2 : 16|16@1+ (0.01,0) [0|655.35] "v"  HVESP01

BO_ 2499756135 HVESP01_VoltageDiag_Series_P2_3: 8 HVESP01
 SG_ HVESP01_SdiagVPackPos_P2_PackPos_3 : 32|16@1+ (0.01,0) [0|655.35] "v"  HVESP01
 SG_ HVESP01_SdiagVLoadPos_P2_LoadPos_3 : 0|16@1+ (0.01,0) [0|655.35] "v"  HVESP01
 SG_ HVESP01_SdiagVFCNeg_P2_LoadNeg_3 : 48|16@1+ (0.01,0) [0|655.35] "v"  HVESP01
 SG_ HVESP01_SdiagVAuxNeg_P2_PackNeg_3 : 16|16@1+ (0.01,0) [0|655.35] "v"  HVESP01

BO_ 2499756136 HVESP01_VoltageDiag_Series_P2_4: 8 HVESP01
 SG_ HVESP01_SdiagVPackPos_P2_PackPos_4 : 32|16@1+ (0.01,0) [0|655.35] "v"  HVESP01
 SG_ HVESP01_SdiagVLoadPos_P2_LoadPos_4 : 0|16@1+ (0.01,0) [0|655.35] "v"  HVESP01
 SG_ HVESP01_SdiagVFCNeg_P2_LoadNeg_4 : 48|16@1+ (0.01,0) [0|655.35] "v"  HVESP01
 SG_ HVESP01_SdiagVAuxNeg_P2_PackNeg_4 : 16|16@1+ (0.01,0) [0|655.35] "v"  HVESP01

BO_ 2499756137 HVESP01_VoltageDiag_Series_P2_5: 8 HVESP01
 SG_ HVESP01_SdiagVPackPos_P2_PackPos_5 : 32|16@1+ (0.01,0) [0|655.35] "v"  HVESP01
 SG_ HVESP01_SdiagVLoadPos_P2_LoadPos_5 : 0|16@1+ (0.01,0) [0|655.35] "v"  HVESP01
 SG_ HVESP01_SdiagVFCNeg_P2_LoadNeg_5 : 48|16@1+ (0.01,0) [0|655.35] "v"  HVESP01
 SG_ HVESP01_SdiagVAuxNeg_P2_PackNeg_5 : 16|16@1+ (0.01,0) [0|655.35] "v"  HVESP01

BO_ 2499756138 HVESP01_VoltageDiag_Series_P2_6: 8 HVESP01
 SG_ HVESP01_SdiagVPackPos_P2_PackPos_6 : 32|16@1+ (0.01,0) [0|655.35] "v"  HVESP01
 SG_ HVESP01_SdiagVLoadPos_P2_LoadPos_6 : 0|16@1+ (0.01,0) [0|655.35] "v"  HVESP01
 SG_ HVESP01_SdiagVFCNeg_P2_LoadNeg_6 : 48|16@1+ (0.01,0) [0|655.35] "v"  HVESP01
 SG_ HVESP01_SdiagVAuxNeg_P2_PackNeg_6 : 16|16@1+ (0.01,0) [0|655.35] "v"  HVESP01

BO_ 2499756139 HVESP01_VoltageDiag_Series_P2_7: 8 HVESP01
 SG_ HVESP01_SdiagVPackPos_P2_PackPos_7 : 32|16@1+ (0.01,0) [0|655.35] "v"  HVESP01
 SG_ HVESP01_SdiagVLoadPos_P2_LoadPos_7 : 0|16@1+ (0.01,0) [0|655.35] "v"  HVESP01
 SG_ HVESP01_SdiagVFCNeg_P2_LoadNeg_7 : 48|16@1+ (0.01,0) [0|655.35] "v"  HVESP01
 SG_ HVESP01_SdiagVAuxNeg_P2_PackNeg_7 : 16|16@1+ (0.01,0) [0|655.35] "v"  HVESP01

BO_ 2499756140 HVESP01_VoltageDiag_Series_P2_8: 8 HVESP01
 SG_ HVESP01_SdiagVPackPos_P2_PackPos_8 : 32|16@1+ (0.01,0) [0|655.35] "v"  HVESP01
 SG_ HVESP01_SdiagVLoadPos_P2_LoadPos_8 : 0|16@1+ (0.01,0) [0|655.35] "v"  HVESP01
 SG_ HVESP01_SdiagVFCNeg_P2_LoadNeg_8 : 48|16@1+ (0.01,0) [0|655.35] "v"  HVESP01
 SG_ HVESP01_SdiagVAuxNeg_P2_PackNeg_8 : 16|16@1+ (0.01,0) [0|655.35] "v"  HVESP01

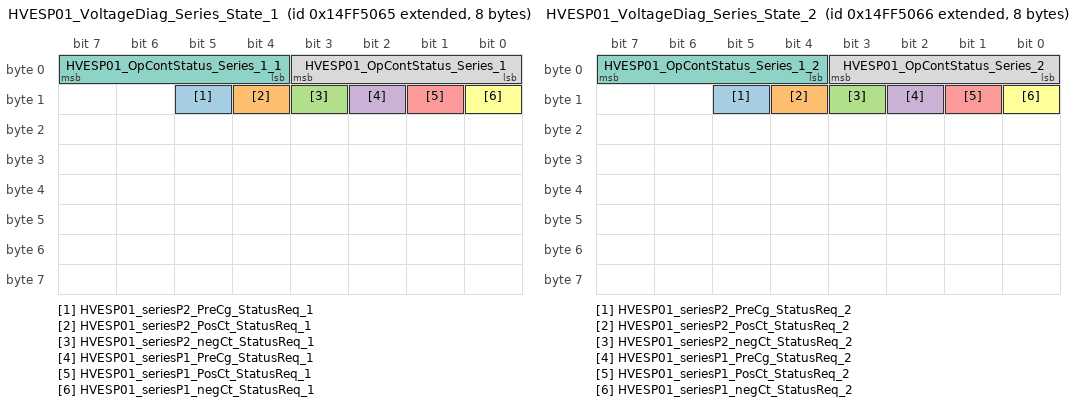
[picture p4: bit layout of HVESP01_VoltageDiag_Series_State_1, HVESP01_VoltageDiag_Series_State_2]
BO_ 2499760229 HVESP01_VoltageDiag_Series_State_1: 8 HVESP01
 SG_ HVESP01_seriesP2_PreCg_StatusReq_1 : 13|1@1+ (1,0) [0|1] ""  HVESP01
 SG_ HVESP01_seriesP2_PosCt_StatusReq_1 : 12|1@1+ (1,0) [0|1] ""  HVESP01
 SG_ HVESP01_seriesP2_negCt_StatusReq_1 : 11|1@1+ (1,0) [0|1] ""  HVESP01
 SG_ HVESP01_seriesP1_PreCg_StatusReq_1 : 10|1@1+ (1,0) [0|1] ""  HVESP01
 SG_ HVESP01_seriesP1_PosCt_StatusReq_1 : 9|1@1+ (1,0) [0|1] ""  HVESP01
 SG_ HVESP01_seriesP1_negCt_StatusReq_1 : 8|1@1+ (1,0) [0|1] ""  HVESP01
 SG_ HVESP01_OpContStatus_Series_1_1 : 4|4@1+ (1,0) [0|15] ""  HVESP01
 SG_ HVESP01_OpContStatus_Series_1 : 0|4@1+ (1,0) [0|15] ""  HVESP01

BO_ 2499760230 HVESP01_VoltageDiag_Series_State_2: 8 HVESP01
 SG_ HVESP01_seriesP2_PreCg_StatusReq_2 : 13|1@1+ (1,0) [0|1] ""  HVESP01
 SG_ HVESP01_seriesP2_PosCt_StatusReq_2 : 12|1@1+ (1,0) [0|1] ""  HVESP01
 SG_ HVESP01_seriesP2_negCt_StatusReq_2 : 11|1@1+ (1,0) [0|1] ""  HVESP01
 SG_ HVESP01_seriesP1_PreCg_StatusReq_2 : 10|1@1+ (1,0) [0|1] ""  HVESP01
 SG_ HVESP01_seriesP1_PosCt_StatusReq_2 : 9|1@1+ (1,0) [0|1] ""  HVESP01
 SG_ HVESP01_seriesP1_negCt_StatusReq_2 : 8|1@1+ (1,0) [0|1] ""  HVESP01
 SG_ HVESP01_OpContStatus_Series_1_2 : 4|4@1+ (1,0) [0|15] ""  HVESP01
 SG_ HVESP01_OpContStatus_Series_2 : 0|4@1+ (1,0) [0|15] ""  HVESP01

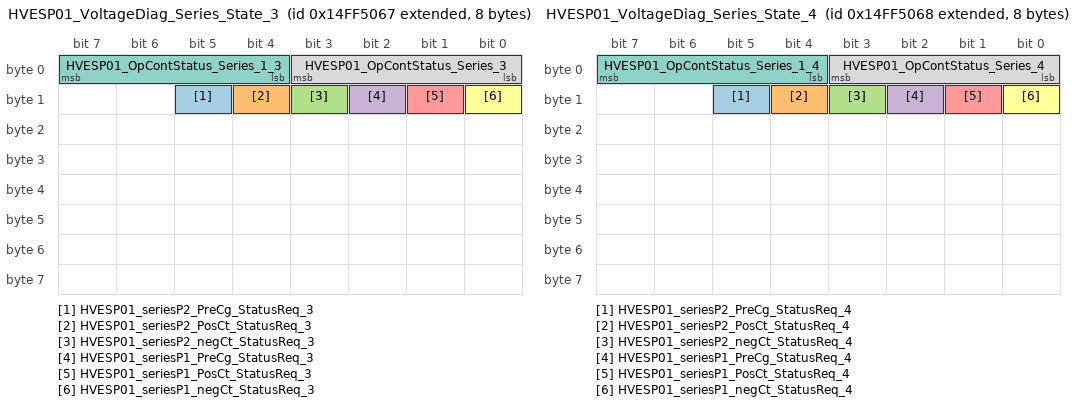
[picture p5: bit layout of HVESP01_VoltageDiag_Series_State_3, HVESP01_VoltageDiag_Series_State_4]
BO_ 2499760231 HVESP01_VoltageDiag_Series_State_3: 8 HVESP01
 SG_ HVESP01_seriesP2_PreCg_StatusReq_3 : 13|1@1+ (1,0) [0|1] ""  HVESP01
 SG_ HVESP01_seriesP2_PosCt_StatusReq_3 : 12|1@1+ (1,0) [0|1] ""  HVESP01
 SG_ HVESP01_seriesP2_negCt_StatusReq_3 : 11|1@1+ (1,0) [0|1] ""  HVESP01
 SG_ HVESP01_seriesP1_PreCg_StatusReq_3 : 10|1@1+ (1,0) [0|1] ""  HVESP01
 SG_ HVESP01_seriesP1_PosCt_StatusReq_3 : 9|1@1+ (1,0) [0|1] ""  HVESP01
 SG_ HVESP01_seriesP1_negCt_StatusReq_3 : 8|1@1+ (1,0) [0|1] ""  HVESP01
 SG_ HVESP01_OpContStatus_Series_1_3 : 4|4@1+ (1,0) [0|15] ""  HVESP01
 SG_ HVESP01_OpContStatus_Series_3 : 0|4@1+ (1,0) [0|15] ""  HVESP01

BO_ 2499760232 HVESP01_VoltageDiag_Series_State_4: 8 HVESP01
 SG_ HVESP01_seriesP2_PreCg_StatusReq_4 : 13|1@1+ (1,0) [0|1] ""  HVESP01
 SG_ HVESP01_seriesP2_PosCt_StatusReq_4 : 12|1@1+ (1,0) [0|1] ""  HVESP01
 SG_ HVESP01_seriesP2_negCt_StatusReq_4 : 11|1@1+ (1,0) [0|1] ""  HVESP01
 SG_ HVESP01_seriesP1_PreCg_StatusReq_4 : 10|1@1+ (1,0) [0|1] ""  HVESP01
 SG_ HVESP01_seriesP1_PosCt_StatusReq_4 : 9|1@1+ (1,0) [0|1] ""  HVESP01
 SG_ HVESP01_seriesP1_negCt_StatusReq_4 : 8|1@1+ (1,0) [0|1] ""  HVESP01
 SG_ HVESP01_OpContStatus_Series_1_4 : 4|4@1+ (1,0) [0|15] ""  HVESP01
 SG_ HVESP01_OpContStatus_Series_4 : 0|4@1+ (1,0) [0|15] ""  HVESP01

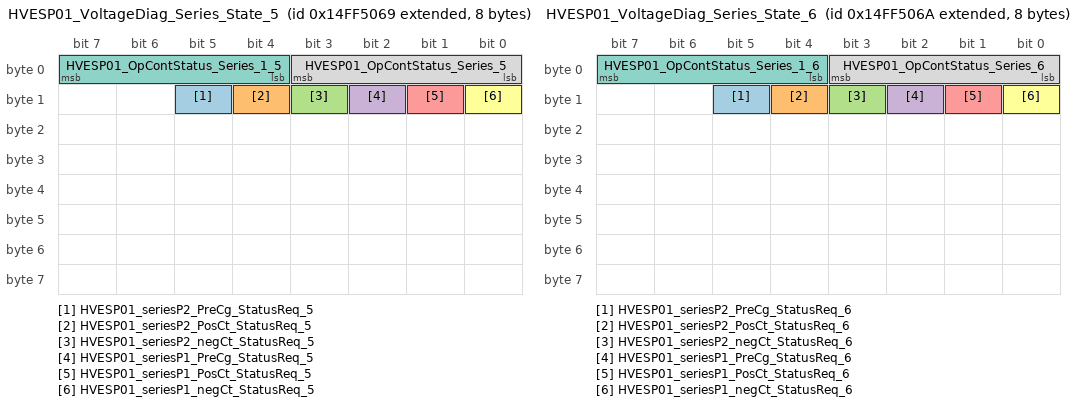
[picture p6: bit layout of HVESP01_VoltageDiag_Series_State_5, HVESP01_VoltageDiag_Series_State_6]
BO_ 2499760233 HVESP01_VoltageDiag_Series_State_5: 8 HVESP01
 SG_ HVESP01_seriesP2_PreCg_StatusReq_5 : 13|1@1+ (1,0) [0|1] ""  HVESP01
 SG_ HVESP01_seriesP2_PosCt_StatusReq_5 : 12|1@1+ (1,0) [0|1] ""  HVESP01
 SG_ HVESP01_seriesP2_negCt_StatusReq_5 : 11|1@1+ (1,0) [0|1] ""  HVESP01
 SG_ HVESP01_seriesP1_PreCg_StatusReq_5 : 10|1@1+ (1,0) [0|1] ""  HVESP01
 SG_ HVESP01_seriesP1_PosCt_StatusReq_5 : 9|1@1+ (1,0) [0|1] ""  HVESP01
 SG_ HVESP01_seriesP1_negCt_StatusReq_5 : 8|1@1+ (1,0) [0|1] ""  HVESP01
 SG_ HVESP01_OpContStatus_Series_1_5 : 4|4@1+ (1,0) [0|15] ""  HVESP01
 SG_ HVESP01_OpContStatus_Series_5 : 0|4@1+ (1,0) [0|15] ""  HVESP01

BO_ 2499760234 HVESP01_VoltageDiag_Series_State_6: 8 HVESP01
 SG_ HVESP01_seriesP2_PreCg_StatusReq_6 : 13|1@1+ (1,0) [0|1] ""  HVESP01
 SG_ HVESP01_seriesP2_PosCt_StatusReq_6 : 12|1@1+ (1,0) [0|1] ""  HVESP01
 SG_ HVESP01_seriesP2_negCt_StatusReq_6 : 11|1@1+ (1,0) [0|1] ""  HVESP01
 SG_ HVESP01_seriesP1_PreCg_StatusReq_6 : 10|1@1+ (1,0) [0|1] ""  HVESP01
 SG_ HVESP01_seriesP1_PosCt_StatusReq_6 : 9|1@1+ (1,0) [0|1] ""  HVESP01
 SG_ HVESP01_seriesP1_negCt_StatusReq_6 : 8|1@1+ (1,0) [0|1] ""  HVESP01
 SG_ HVESP01_OpContStatus_Series_1_6 : 4|4@1+ (1,0) [0|15] ""  HVESP01
 SG_ HVESP01_OpContStatus_Series_6 : 0|4@1+ (1,0) [0|15] ""  HVESP01

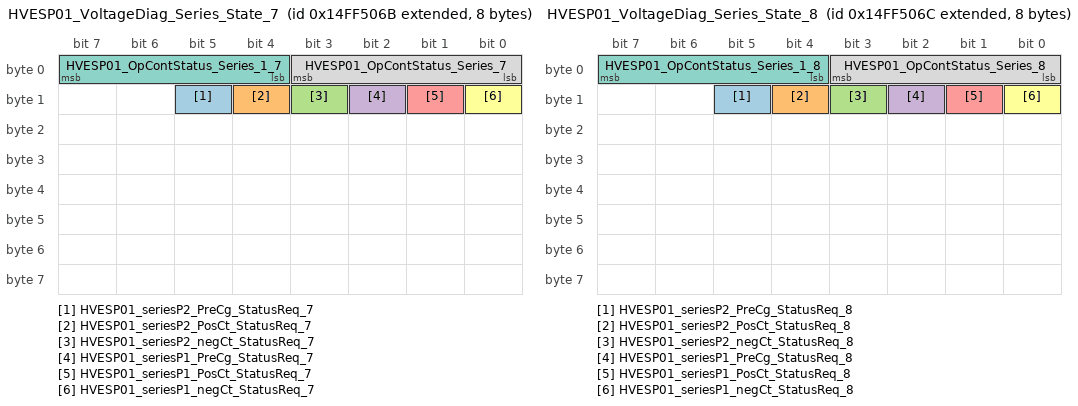
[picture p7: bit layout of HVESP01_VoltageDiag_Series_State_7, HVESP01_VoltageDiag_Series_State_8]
BO_ 2499760235 HVESP01_VoltageDiag_Series_State_7: 8 HVESP01
 SG_ HVESP01_seriesP2_PreCg_StatusReq_7 : 13|1@1+ (1,0) [0|1] ""  HVESP01
 SG_ HVESP01_seriesP2_PosCt_StatusReq_7 : 12|1@1+ (1,0) [0|1] ""  HVESP01
 SG_ HVESP01_seriesP2_negCt_StatusReq_7 : 11|1@1+ (1,0) [0|1] ""  HVESP01
 SG_ HVESP01_seriesP1_PreCg_StatusReq_7 : 10|1@1+ (1,0) [0|1] ""  HVESP01
 SG_ HVESP01_seriesP1_PosCt_StatusReq_7 : 9|1@1+ (1,0) [0|1] ""  HVESP01
 SG_ HVESP01_seriesP1_negCt_StatusReq_7 : 8|1@1+ (1,0) [0|1] ""  HVESP01
 SG_ HVESP01_OpContStatus_Series_1_7 : 4|4@1+ (1,0) [0|15] ""  HVESP01
 SG_ HVESP01_OpContStatus_Series_7 : 0|4@1+ (1,0) [0|15] ""  HVESP01

BO_ 2499760236 HVESP01_VoltageDiag_Series_State_8: 8 HVESP01
 SG_ HVESP01_seriesP2_PreCg_StatusReq_8 : 13|1@1+ (1,0) [0|1] ""  HVESP01
 SG_ HVESP01_seriesP2_PosCt_StatusReq_8 : 12|1@1+ (1,0) [0|1] ""  HVESP01
 SG_ HVESP01_seriesP2_negCt_StatusReq_8 : 11|1@1+ (1,0) [0|1] ""  HVESP01
 SG_ HVESP01_seriesP1_PreCg_StatusReq_8 : 10|1@1+ (1,0) [0|1] ""  HVESP01
 SG_ HVESP01_seriesP1_PosCt_StatusReq_8 : 9|1@1+ (1,0) [0|1] ""  HVESP01
 SG_ HVESP01_seriesP1_negCt_StatusReq_8 : 8|1@1+ (1,0) [0|1] ""  HVESP01
 SG_ HVESP01_OpContStatus_Series_1_8 : 4|4@1+ (1,0) [0|15] ""  HVESP01
 SG_ HVESP01_OpContStatus_Series_8 : 0|4@1+ (1,0) [0|15] ""  HVESP01

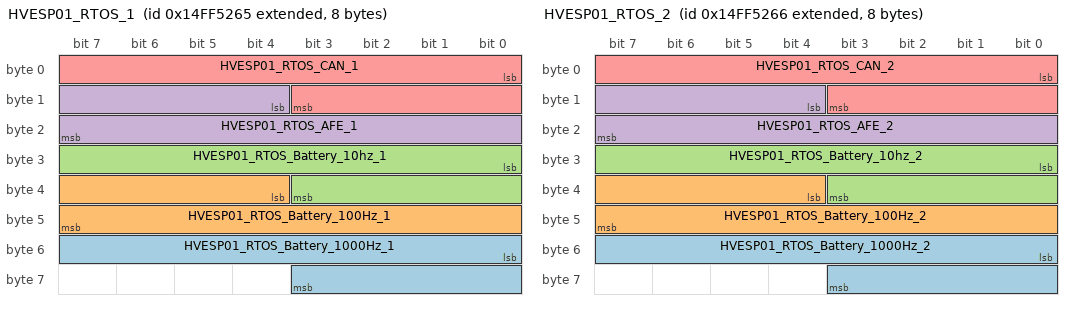
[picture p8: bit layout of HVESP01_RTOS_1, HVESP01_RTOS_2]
BO_ 2499760741 HVESP01_RTOS_1: 8 HVESP01
 SG_ HVESP01_RTOS_Battery_1000Hz_1 : 48|12@1+ (1,0) [0|4095] ""  HVESP01
 SG_ HVESP01_RTOS_Battery_100Hz_1 : 36|12@1+ (1,0) [0|4095] ""  HVESP01
 SG_ HVESP01_RTOS_Battery_10hz_1 : 24|12@1+ (1,0) [0|4095] ""  HVESP01
 SG_ HVESP01_RTOS_AFE_1 : 12|12@1+ (1,0) [0|4095] ""  HVESP01
 SG_ HVESP01_RTOS_CAN_1 : 0|12@1+ (1,0) [0|4095] ""  HVESP01

BO_ 2499760742 HVESP01_RTOS_2: 8 HVESP01
 SG_ HVESP01_RTOS_Battery_1000Hz_2 : 48|12@1+ (1,0) [0|4095] ""  HVESP01
 SG_ HVESP01_RTOS_Battery_100Hz_2 : 36|12@1+ (1,0) [0|4095] ""  HVESP01
 SG_ HVESP01_RTOS_Battery_10hz_2 : 24|12@1+ (1,0) [0|4095] ""  HVESP01
 SG_ HVESP01_RTOS_AFE_2 : 12|12@1+ (1,0) [0|4095] ""  HVESP01
 SG_ HVESP01_RTOS_CAN_2 : 0|12@1+ (1,0) [0|4095] ""  HVESP01

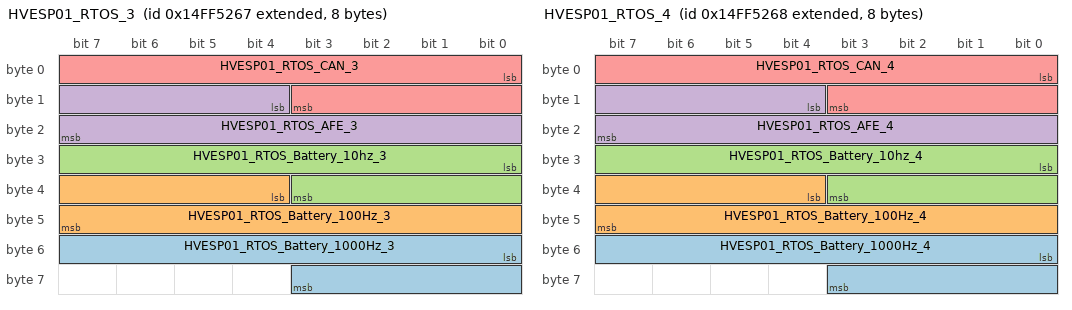
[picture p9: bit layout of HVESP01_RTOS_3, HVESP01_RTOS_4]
BO_ 2499760743 HVESP01_RTOS_3: 8 HVESP01
 SG_ HVESP01_RTOS_Battery_1000Hz_3 : 48|12@1+ (1,0) [0|4095] ""  HVESP01
 SG_ HVESP01_RTOS_Battery_100Hz_3 : 36|12@1+ (1,0) [0|4095] ""  HVESP01
 SG_ HVESP01_RTOS_Battery_10hz_3 : 24|12@1+ (1,0) [0|4095] ""  HVESP01
 SG_ HVESP01_RTOS_AFE_3 : 12|12@1+ (1,0) [0|4095] ""  HVESP01
 SG_ HVESP01_RTOS_CAN_3 : 0|12@1+ (1,0) [0|4095] ""  HVESP01

BO_ 2499760744 HVESP01_RTOS_4: 8 HVESP01
 SG_ HVESP01_RTOS_Battery_1000Hz_4 : 48|12@1+ (1,0) [0|4095] ""  HVESP01
 SG_ HVESP01_RTOS_Battery_100Hz_4 : 36|12@1+ (1,0) [0|4095] ""  HVESP01
 SG_ HVESP01_RTOS_Battery_10hz_4 : 24|12@1+ (1,0) [0|4095] ""  HVESP01
 SG_ HVESP01_RTOS_AFE_4 : 12|12@1+ (1,0) [0|4095] ""  HVESP01
 SG_ HVESP01_RTOS_CAN_4 : 0|12@1+ (1,0) [0|4095] ""  HVESP01

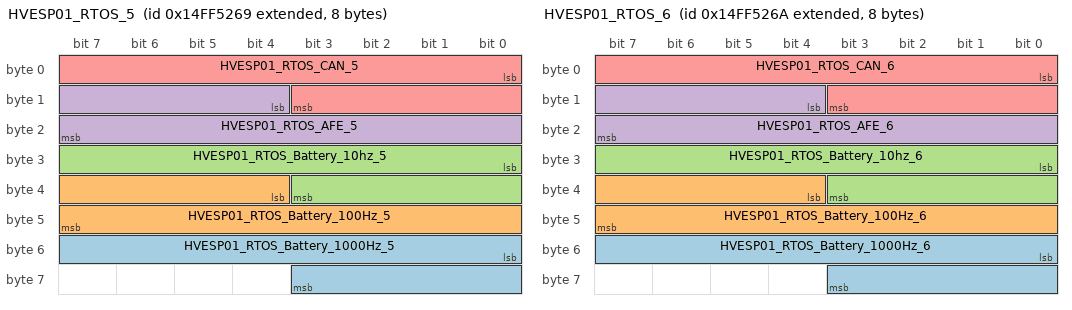
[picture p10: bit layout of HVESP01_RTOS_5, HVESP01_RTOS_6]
BO_ 2499760745 HVESP01_RTOS_5: 8 HVESP01
 SG_ HVESP01_RTOS_Battery_1000Hz_5 : 48|12@1+ (1,0) [0|4095] ""  HVESP01
 SG_ HVESP01_RTOS_Battery_100Hz_5 : 36|12@1+ (1,0) [0|4095] ""  HVESP01
 SG_ HVESP01_RTOS_Battery_10hz_5 : 24|12@1+ (1,0) [0|4095] ""  HVESP01
 SG_ HVESP01_RTOS_AFE_5 : 12|12@1+ (1,0) [0|4095] ""  HVESP01
 SG_ HVESP01_RTOS_CAN_5 : 0|12@1+ (1,0) [0|4095] ""  HVESP01

BO_ 2499760746 HVESP01_RTOS_6: 8 HVESP01
 SG_ HVESP01_RTOS_Battery_1000Hz_6 : 48|12@1+ (1,0) [0|4095] ""  HVESP01
 SG_ HVESP01_RTOS_Battery_100Hz_6 : 36|12@1+ (1,0) [0|4095] ""  HVESP01
 SG_ HVESP01_RTOS_Battery_10hz_6 : 24|12@1+ (1,0) [0|4095] ""  HVESP01
 SG_ HVESP01_RTOS_AFE_6 : 12|12@1+ (1,0) [0|4095] ""  HVESP01
 SG_ HVESP01_RTOS_CAN_6 : 0|12@1+ (1,0) [0|4095] ""  HVESP01

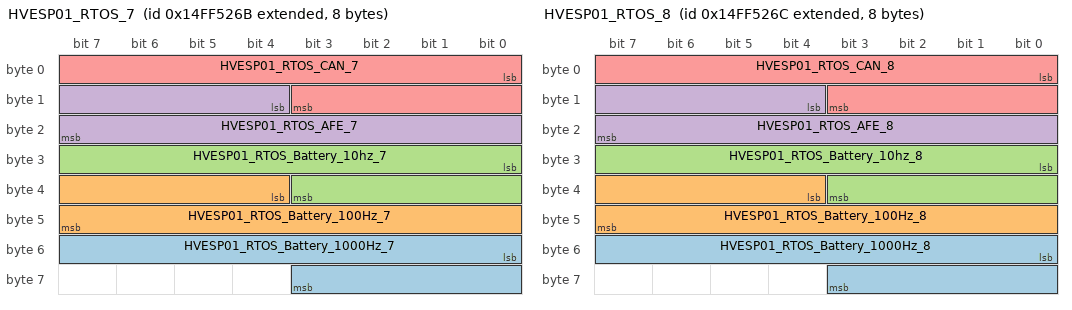
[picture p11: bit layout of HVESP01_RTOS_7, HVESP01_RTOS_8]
BO_ 2499760747 HVESP01_RTOS_7: 8 HVESP01
 SG_ HVESP01_RTOS_Battery_1000Hz_7 : 48|12@1+ (1,0) [0|4095] ""  HVESP01
 SG_ HVESP01_RTOS_Battery_100Hz_7 : 36|12@1+ (1,0) [0|4095] ""  HVESP01
 SG_ HVESP01_RTOS_Battery_10hz_7 : 24|12@1+ (1,0) [0|4095] ""  HVESP01
 SG_ HVESP01_RTOS_AFE_7 : 12|12@1+ (1,0) [0|4095] ""  HVESP01
 SG_ HVESP01_RTOS_CAN_7 : 0|12@1+ (1,0) [0|4095] ""  HVESP01

BO_ 2499760748 HVESP01_RTOS_8: 8 HVESP01
 SG_ HVESP01_RTOS_Battery_1000Hz_8 : 48|12@1+ (1,0) [0|4095] ""  HVESP01
 SG_ HVESP01_RTOS_Battery_100Hz_8 : 36|12@1+ (1,0) [0|4095] ""  HVESP01
 SG_ HVESP01_RTOS_Battery_10hz_8 : 24|12@1+ (1,0) [0|4095] ""  HVESP01
 SG_ HVESP01_RTOS_AFE_8 : 12|12@1+ (1,0) [0|4095] ""  HVESP01
 SG_ HVESP01_RTOS_CAN_8 : 0|12@1+ (1,0) [0|4095] ""  HVESP01

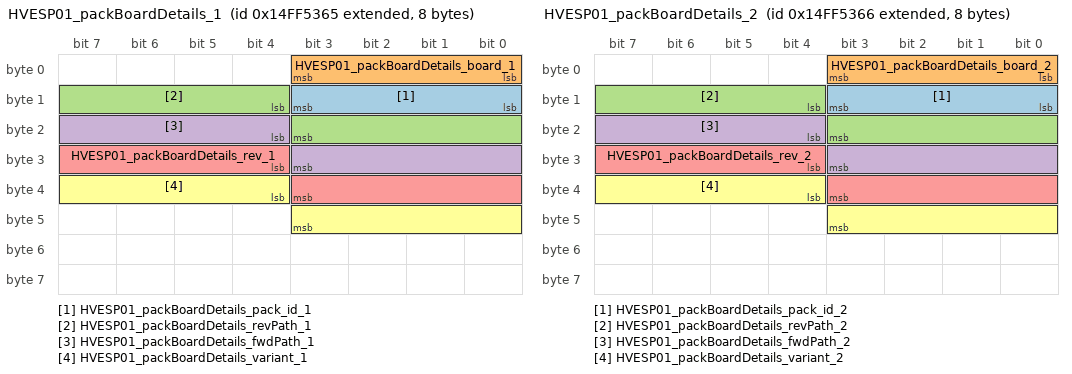
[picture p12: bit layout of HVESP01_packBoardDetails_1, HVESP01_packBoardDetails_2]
BO_ 2499760997 HVESP01_packBoardDetails_1: 8 HVESP01
 SG_ HVESP01_packBoardDetails_pack_id_1 : 8|4@1+ (1,0) [0|15] ""  HVESP01
 SG_ HVESP01_packBoardDetails_board_1 : 0|4@1+ (1,0) [0|15] ""  HVESP01
 SG_ HVESP01_packBoardDetails_revPath_1 : 12|8@1+ (1,0) [0|255] ""  HVESP01
 SG_ HVESP01_packBoardDetails_fwdPath_1 : 20|8@1+ (1,0) [0|255] ""  HVESP01
 SG_ HVESP01_packBoardDetails_rev_1 : 28|8@1+ (1,0) [0|255] ""  HVESP01
 SG_ HVESP01_packBoardDetails_variant_1 : 36|8@1+ (1,0) [0|255] ""  HVESP01

BO_ 2499760998 HVESP01_packBoardDetails_2: 8 HVESP01
 SG_ HVESP01_packBoardDetails_pack_id_2 : 8|4@1+ (1,0) [0|15] ""  HVESP01
 SG_ HVESP01_packBoardDetails_board_2 : 0|4@1+ (1,0) [0|15] ""  HVESP01
 SG_ HVESP01_packBoardDetails_revPath_2 : 12|8@1+ (1,0) [0|255] ""  HVESP01
 SG_ HVESP01_packBoardDetails_fwdPath_2 : 20|8@1+ (1,0) [0|255] ""  HVESP01
 SG_ HVESP01_packBoardDetails_rev_2 : 28|8@1+ (1,0) [0|255] ""  HVESP01
 SG_ HVESP01_packBoardDetails_variant_2 : 36|8@1+ (1,0) [0|255] ""  HVESP01

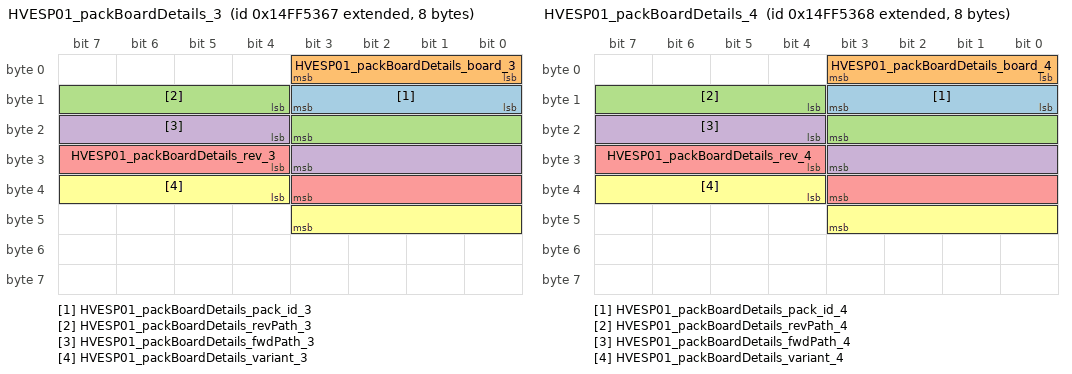
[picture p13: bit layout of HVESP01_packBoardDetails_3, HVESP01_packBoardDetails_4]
BO_ 2499760999 HVESP01_packBoardDetails_3: 8 HVESP01
 SG_ HVESP01_packBoardDetails_pack_id_3 : 8|4@1+ (1,0) [0|15] ""  HVESP01
 SG_ HVESP01_packBoardDetails_board_3 : 0|4@1+ (1,0) [0|15] ""  HVESP01
 SG_ HVESP01_packBoardDetails_revPath_3 : 12|8@1+ (1,0) [0|255] ""  HVESP01
 SG_ HVESP01_packBoardDetails_fwdPath_3 : 20|8@1+ (1,0) [0|255] ""  HVESP01
 SG_ HVESP01_packBoardDetails_rev_3 : 28|8@1+ (1,0) [0|255] ""  HVESP01
 SG_ HVESP01_packBoardDetails_variant_3 : 36|8@1+ (1,0) [0|255] ""  HVESP01

BO_ 2499761000 HVESP01_packBoardDetails_4: 8 HVESP01
 SG_ HVESP01_packBoardDetails_pack_id_4 : 8|4@1+ (1,0) [0|15] ""  HVESP01
 SG_ HVESP01_packBoardDetails_board_4 : 0|4@1+ (1,0) [0|15] ""  HVESP01
 SG_ HVESP01_packBoardDetails_revPath_4 : 12|8@1+ (1,0) [0|255] ""  HVESP01
 SG_ HVESP01_packBoardDetails_fwdPath_4 : 20|8@1+ (1,0) [0|255] ""  HVESP01
 SG_ HVESP01_packBoardDetails_rev_4 : 28|8@1+ (1,0) [0|255] ""  HVESP01
 SG_ HVESP01_packBoardDetails_variant_4 : 36|8@1+ (1,0) [0|255] ""  HVESP01

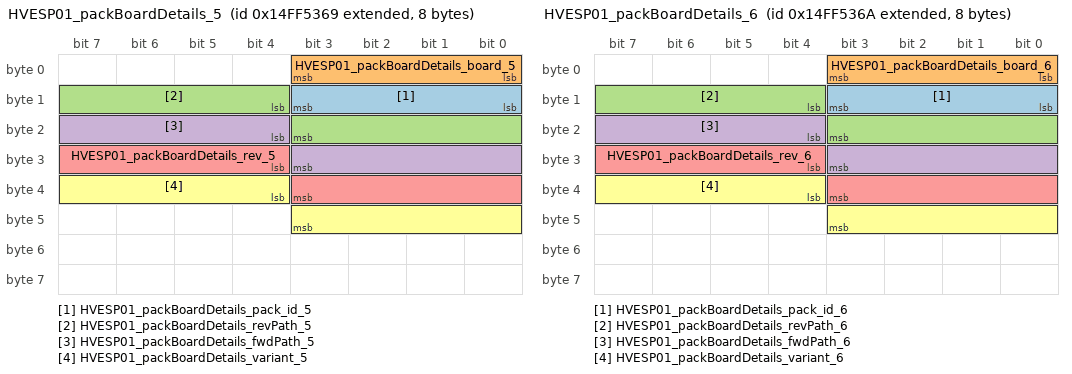
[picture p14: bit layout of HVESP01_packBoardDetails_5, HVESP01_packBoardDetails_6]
BO_ 2499761001 HVESP01_packBoardDetails_5: 8 HVESP01
 SG_ HVESP01_packBoardDetails_pack_id_5 : 8|4@1+ (1,0) [0|15] ""  HVESP01
 SG_ HVESP01_packBoardDetails_board_5 : 0|4@1+ (1,0) [0|15] ""  HVESP01
 SG_ HVESP01_packBoardDetails_revPath_5 : 12|8@1+ (1,0) [0|255] ""  HVESP01
 SG_ HVESP01_packBoardDetails_fwdPath_5 : 20|8@1+ (1,0) [0|255] ""  HVESP01
 SG_ HVESP01_packBoardDetails_rev_5 : 28|8@1+ (1,0) [0|255] ""  HVESP01
 SG_ HVESP01_packBoardDetails_variant_5 : 36|8@1+ (1,0) [0|255] ""  HVESP01

BO_ 2499761002 HVESP01_packBoardDetails_6: 8 HVESP01
 SG_ HVESP01_packBoardDetails_pack_id_6 : 8|4@1+ (1,0) [0|15] ""  HVESP01
 SG_ HVESP01_packBoardDetails_board_6 : 0|4@1+ (1,0) [0|15] ""  HVESP01
 SG_ HVESP01_packBoardDetails_revPath_6 : 12|8@1+ (1,0) [0|255] ""  HVESP01
 SG_ HVESP01_packBoardDetails_fwdPath_6 : 20|8@1+ (1,0) [0|255] ""  HVESP01
 SG_ HVESP01_packBoardDetails_rev_6 : 28|8@1+ (1,0) [0|255] ""  HVESP01
 SG_ HVESP01_packBoardDetails_variant_6 : 36|8@1+ (1,0) [0|255] ""  HVESP01

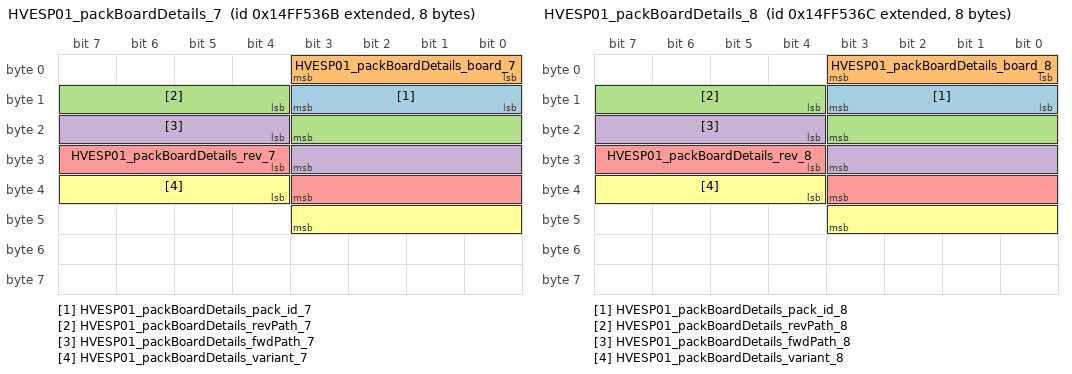
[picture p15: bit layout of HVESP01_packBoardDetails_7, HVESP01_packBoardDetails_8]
BO_ 2499761003 HVESP01_packBoardDetails_7: 8 HVESP01
 SG_ HVESP01_packBoardDetails_pack_id_7 : 8|4@1+ (1,0) [0|15] ""  HVESP01
 SG_ HVESP01_packBoardDetails_board_7 : 0|4@1+ (1,0) [0|15] ""  HVESP01
 SG_ HVESP01_packBoardDetails_revPath_7 : 12|8@1+ (1,0) [0|255] ""  HVESP01
 SG_ HVESP01_packBoardDetails_fwdPath_7 : 20|8@1+ (1,0) [0|255] ""  HVESP01
 SG_ HVESP01_packBoardDetails_rev_7 : 28|8@1+ (1,0) [0|255] ""  HVESP01
 SG_ HVESP01_packBoardDetails_variant_7 : 36|8@1+ (1,0) [0|255] ""  HVESP01

BO_ 2499761004 HVESP01_packBoardDetails_8: 8 HVESP01
 SG_ HVESP01_packBoardDetails_pack_id_8 : 8|4@1+ (1,0) [0|15] ""  HVESP01
 SG_ HVESP01_packBoardDetails_board_8 : 0|4@1+ (1,0) [0|15] ""  HVESP01
 SG_ HVESP01_packBoardDetails_revPath_8 : 12|8@1+ (1,0) [0|255] ""  HVESP01
 SG_ HVESP01_packBoardDetails_fwdPath_8 : 20|8@1+ (1,0) [0|255] ""  HVESP01
 SG_ HVESP01_packBoardDetails_rev_8 : 28|8@1+ (1,0) [0|255] ""  HVESP01
 SG_ HVESP01_packBoardDetails_variant_8 : 36|8@1+ (1,0) [0|255] ""  HVESP01

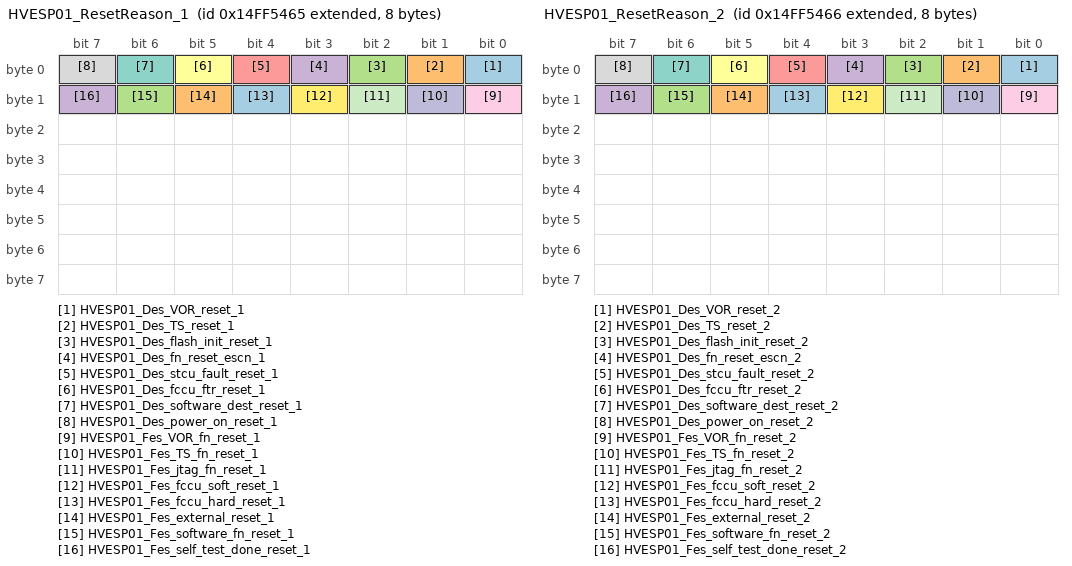
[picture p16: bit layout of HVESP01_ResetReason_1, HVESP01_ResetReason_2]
BO_ 2499761253 HVESP01_ResetReason_1: 8 HVESP01
 SG_ HVESP01_Des_VOR_reset_1 : 0|1@0+ (1,0) [0|1] "B"  HVESP01
 SG_ HVESP01_Des_TS_reset_1 : 1|1@0+ (1,0) [0|1] "B"  HVESP01
 SG_ HVESP01_Des_flash_init_reset_1 : 2|1@0+ (1,0) [0|1] "B"  HVESP01
 SG_ HVESP01_Des_fn_reset_escn_1 : 3|1@0+ (1,0) [0|1] "B"  HVESP01
 SG_ HVESP01_Des_stcu_fault_reset_1 : 4|1@0+ (1,0) [0|1] "B"  HVESP01
 SG_ HVESP01_Des_fccu_ftr_reset_1 : 5|1@0+ (1,0) [0|1] "B"  HVESP01
 SG_ HVESP01_Des_software_dest_reset_1 : 6|1@0+ (1,0) [0|1] "B"  HVESP01
 SG_ HVESP01_Des_power_on_reset_1 : 7|1@0+ (1,0) [0|1] "B"  HVESP01
 SG_ HVESP01_Fes_VOR_fn_reset_1 : 8|1@0+ (1,0) [0|1] "B"  HVESP01
 SG_ HVESP01_Fes_TS_fn_reset_1 : 9|1@0+ (1,0) [0|1] "B"  HVESP01
 SG_ HVESP01_Fes_jtag_fn_reset_1 : 10|1@0+ (1,0) [0|1] "B"  HVESP01
 SG_ HVESP01_Fes_fccu_soft_reset_1 : 11|1@0+ (1,0) [0|1] "B"  HVESP01
 SG_ HVESP01_Fes_fccu_hard_reset_1 : 12|1@0+ (1,0) [0|1] "B"  HVESP01
 SG_ HVESP01_Fes_external_reset_1 : 13|1@0+ (1,0) [0|1] "B"  HVESP01
 SG_ HVESP01_Fes_software_fn_reset_1 : 14|1@0+ (1,0) [0|1] "B"  HVESP01
 SG_ HVESP01_Fes_self_test_done_reset_1 : 15|1@0+ (1,0) [0|1] "B"  HVESP01

BO_ 2499761254 HVESP01_ResetReason_2: 8 HVESP01
 SG_ HVESP01_Des_VOR_reset_2 : 0|1@0+ (1,0) [0|1] "B"  HVESP01
 SG_ HVESP01_Des_TS_reset_2 : 1|1@0+ (1,0) [0|1] "B"  HVESP01
 SG_ HVESP01_Des_flash_init_reset_2 : 2|1@0+ (1,0) [0|1] "B"  HVESP01
 SG_ HVESP01_Des_fn_reset_escn_2 : 3|1@0+ (1,0) [0|1] "B"  HVESP01
 SG_ HVESP01_Des_stcu_fault_reset_2 : 4|1@0+ (1,0) [0|1] "B"  HVESP01
 SG_ HVESP01_Des_fccu_ftr_reset_2 : 5|1@0+ (1,0) [0|1] "B"  HVESP01
 SG_ HVESP01_Des_software_dest_reset_2 : 6|1@0+ (1,0) [0|1] "B"  HVESP01
 SG_ HVESP01_Des_power_on_reset_2 : 7|1@0+ (1,0) [0|1] "B"  HVESP01
 SG_ HVESP01_Fes_VOR_fn_reset_2 : 8|1@0+ (1,0) [0|1] "B"  HVESP01
 SG_ HVESP01_Fes_TS_fn_reset_2 : 9|1@0+ (1,0) [0|1] "B"  HVESP01
 SG_ HVESP01_Fes_jtag_fn_reset_2 : 10|1@0+ (1,0) [0|1] "B"  HVESP01
 SG_ HVESP01_Fes_fccu_soft_reset_2 : 11|1@0+ (1,0) [0|1] "B"  HVESP01
 SG_ HVESP01_Fes_fccu_hard_reset_2 : 12|1@0+ (1,0) [0|1] "B"  HVESP01
 SG_ HVESP01_Fes_external_reset_2 : 13|1@0+ (1,0) [0|1] "B"  HVESP01
 SG_ HVESP01_Fes_software_fn_reset_2 : 14|1@0+ (1,0) [0|1] "B"  HVESP01
 SG_ HVESP01_Fes_self_test_done_reset_2 : 15|1@0+ (1,0) [0|1] "B"  HVESP01

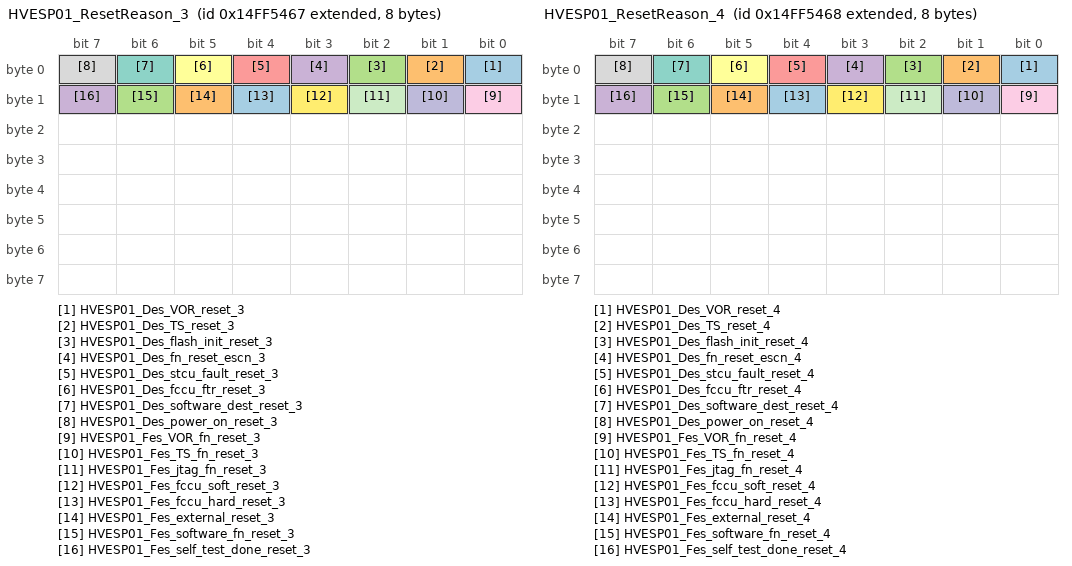
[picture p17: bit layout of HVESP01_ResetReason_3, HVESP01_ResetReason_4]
BO_ 2499761255 HVESP01_ResetReason_3: 8 HVESP01
 SG_ HVESP01_Des_VOR_reset_3 : 0|1@0+ (1,0) [0|1] "B"  HVESP01
 SG_ HVESP01_Des_TS_reset_3 : 1|1@0+ (1,0) [0|1] "B"  HVESP01
 SG_ HVESP01_Des_flash_init_reset_3 : 2|1@0+ (1,0) [0|1] "B"  HVESP01
 SG_ HVESP01_Des_fn_reset_escn_3 : 3|1@0+ (1,0) [0|1] "B"  HVESP01
 SG_ HVESP01_Des_stcu_fault_reset_3 : 4|1@0+ (1,0) [0|1] "B"  HVESP01
 SG_ HVESP01_Des_fccu_ftr_reset_3 : 5|1@0+ (1,0) [0|1] "B"  HVESP01
 SG_ HVESP01_Des_software_dest_reset_3 : 6|1@0+ (1,0) [0|1] "B"  HVESP01
 SG_ HVESP01_Des_power_on_reset_3 : 7|1@0+ (1,0) [0|1] "B"  HVESP01
 SG_ HVESP01_Fes_VOR_fn_reset_3 : 8|1@0+ (1,0) [0|1] "B"  HVESP01
 SG_ HVESP01_Fes_TS_fn_reset_3 : 9|1@0+ (1,0) [0|1] "B"  HVESP01
 SG_ HVESP01_Fes_jtag_fn_reset_3 : 10|1@0+ (1,0) [0|1] "B"  HVESP01
 SG_ HVESP01_Fes_fccu_soft_reset_3 : 11|1@0+ (1,0) [0|1] "B"  HVESP01
 SG_ HVESP01_Fes_fccu_hard_reset_3 : 12|1@0+ (1,0) [0|1] "B"  HVESP01
 SG_ HVESP01_Fes_external_reset_3 : 13|1@0+ (1,0) [0|1] "B"  HVESP01
 SG_ HVESP01_Fes_software_fn_reset_3 : 14|1@0+ (1,0) [0|1] "B"  HVESP01
 SG_ HVESP01_Fes_self_test_done_reset_3 : 15|1@0+ (1,0) [0|1] "B"  HVESP01

BO_ 2499761256 HVESP01_ResetReason_4: 8 HVESP01
 SG_ HVESP01_Des_VOR_reset_4 : 0|1@0+ (1,0) [0|1] "B"  HVESP01
 SG_ HVESP01_Des_TS_reset_4 : 1|1@0+ (1,0) [0|1] "B"  HVESP01
 SG_ HVESP01_Des_flash_init_reset_4 : 2|1@0+ (1,0) [0|1] "B"  HVESP01
 SG_ HVESP01_Des_fn_reset_escn_4 : 3|1@0+ (1,0) [0|1] "B"  HVESP01
 SG_ HVESP01_Des_stcu_fault_reset_4 : 4|1@0+ (1,0) [0|1] "B"  HVESP01
 SG_ HVESP01_Des_fccu_ftr_reset_4 : 5|1@0+ (1,0) [0|1] "B"  HVESP01
 SG_ HVESP01_Des_software_dest_reset_4 : 6|1@0+ (1,0) [0|1] "B"  HVESP01
 SG_ HVESP01_Des_power_on_reset_4 : 7|1@0+ (1,0) [0|1] "B"  HVESP01
 SG_ HVESP01_Fes_VOR_fn_reset_4 : 8|1@0+ (1,0) [0|1] "B"  HVESP01
 SG_ HVESP01_Fes_TS_fn_reset_4 : 9|1@0+ (1,0) [0|1] "B"  HVESP01
 SG_ HVESP01_Fes_jtag_fn_reset_4 : 10|1@0+ (1,0) [0|1] "B"  HVESP01
 SG_ HVESP01_Fes_fccu_soft_reset_4 : 11|1@0+ (1,0) [0|1] "B"  HVESP01
 SG_ HVESP01_Fes_fccu_hard_reset_4 : 12|1@0+ (1,0) [0|1] "B"  HVESP01
 SG_ HVESP01_Fes_external_reset_4 : 13|1@0+ (1,0) [0|1] "B"  HVESP01
 SG_ HVESP01_Fes_software_fn_reset_4 : 14|1@0+ (1,0) [0|1] "B"  HVESP01
 SG_ HVESP01_Fes_self_test_done_reset_4 : 15|1@0+ (1,0) [0|1] "B"  HVESP01

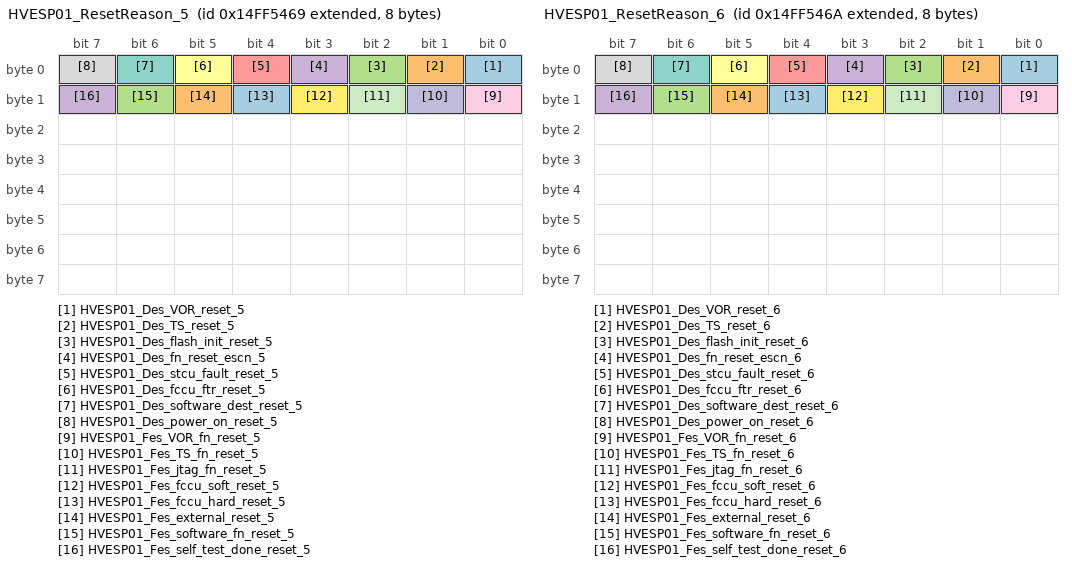
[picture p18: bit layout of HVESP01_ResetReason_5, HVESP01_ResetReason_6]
BO_ 2499761257 HVESP01_ResetReason_5: 8 HVESP01
 SG_ HVESP01_Des_VOR_reset_5 : 0|1@0+ (1,0) [0|1] "B"  HVESP01
 SG_ HVESP01_Des_TS_reset_5 : 1|1@0+ (1,0) [0|1] "B"  HVESP01
 SG_ HVESP01_Des_flash_init_reset_5 : 2|1@0+ (1,0) [0|1] "B"  HVESP01
 SG_ HVESP01_Des_fn_reset_escn_5 : 3|1@0+ (1,0) [0|1] "B"  HVESP01
 SG_ HVESP01_Des_stcu_fault_reset_5 : 4|1@0+ (1,0) [0|1] "B"  HVESP01
 SG_ HVESP01_Des_fccu_ftr_reset_5 : 5|1@0+ (1,0) [0|1] "B"  HVESP01
 SG_ HVESP01_Des_software_dest_reset_5 : 6|1@0+ (1,0) [0|1] "B"  HVESP01
 SG_ HVESP01_Des_power_on_reset_5 : 7|1@0+ (1,0) [0|1] "B"  HVESP01
 SG_ HVESP01_Fes_VOR_fn_reset_5 : 8|1@0+ (1,0) [0|1] "B"  HVESP01
 SG_ HVESP01_Fes_TS_fn_reset_5 : 9|1@0+ (1,0) [0|1] "B"  HVESP01
 SG_ HVESP01_Fes_jtag_fn_reset_5 : 10|1@0+ (1,0) [0|1] "B"  HVESP01
 SG_ HVESP01_Fes_fccu_soft_reset_5 : 11|1@0+ (1,0) [0|1] "B"  HVESP01
 SG_ HVESP01_Fes_fccu_hard_reset_5 : 12|1@0+ (1,0) [0|1] "B"  HVESP01
 SG_ HVESP01_Fes_external_reset_5 : 13|1@0+ (1,0) [0|1] "B"  HVESP01
 SG_ HVESP01_Fes_software_fn_reset_5 : 14|1@0+ (1,0) [0|1] "B"  HVESP01
 SG_ HVESP01_Fes_self_test_done_reset_5 : 15|1@0+ (1,0) [0|1] "B"  HVESP01

BO_ 2499761258 HVESP01_ResetReason_6: 8 HVESP01
 SG_ HVESP01_Des_VOR_reset_6 : 0|1@0+ (1,0) [0|1] "B"  HVESP01
 SG_ HVESP01_Des_TS_reset_6 : 1|1@0+ (1,0) [0|1] "B"  HVESP01
 SG_ HVESP01_Des_flash_init_reset_6 : 2|1@0+ (1,0) [0|1] "B"  HVESP01
 SG_ HVESP01_Des_fn_reset_escn_6 : 3|1@0+ (1,0) [0|1] "B"  HVESP01
 SG_ HVESP01_Des_stcu_fault_reset_6 : 4|1@0+ (1,0) [0|1] "B"  HVESP01
 SG_ HVESP01_Des_fccu_ftr_reset_6 : 5|1@0+ (1,0) [0|1] "B"  HVESP01
 SG_ HVESP01_Des_software_dest_reset_6 : 6|1@0+ (1,0) [0|1] "B"  HVESP01
 SG_ HVESP01_Des_power_on_reset_6 : 7|1@0+ (1,0) [0|1] "B"  HVESP01
 SG_ HVESP01_Fes_VOR_fn_reset_6 : 8|1@0+ (1,0) [0|1] "B"  HVESP01
 SG_ HVESP01_Fes_TS_fn_reset_6 : 9|1@0+ (1,0) [0|1] "B"  HVESP01
 SG_ HVESP01_Fes_jtag_fn_reset_6 : 10|1@0+ (1,0) [0|1] "B"  HVESP01
 SG_ HVESP01_Fes_fccu_soft_reset_6 : 11|1@0+ (1,0) [0|1] "B"  HVESP01
 SG_ HVESP01_Fes_fccu_hard_reset_6 : 12|1@0+ (1,0) [0|1] "B"  HVESP01
 SG_ HVESP01_Fes_external_reset_6 : 13|1@0+ (1,0) [0|1] "B"  HVESP01
 SG_ HVESP01_Fes_software_fn_reset_6 : 14|1@0+ (1,0) [0|1] "B"  HVESP01
 SG_ HVESP01_Fes_self_test_done_reset_6 : 15|1@0+ (1,0) [0|1] "B"  HVESP01

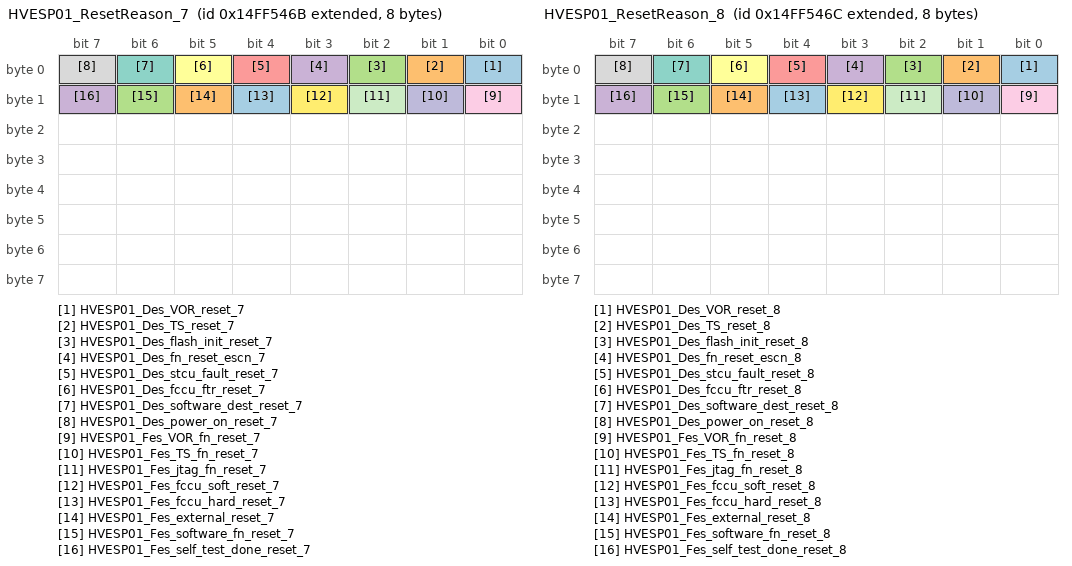
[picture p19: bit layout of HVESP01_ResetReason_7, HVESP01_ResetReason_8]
BO_ 2499761259 HVESP01_ResetReason_7: 8 HVESP01
 SG_ HVESP01_Des_VOR_reset_7 : 0|1@0+ (1,0) [0|1] "B"  HVESP01
 SG_ HVESP01_Des_TS_reset_7 : 1|1@0+ (1,0) [0|1] "B"  HVESP01
 SG_ HVESP01_Des_flash_init_reset_7 : 2|1@0+ (1,0) [0|1] "B"  HVESP01
 SG_ HVESP01_Des_fn_reset_escn_7 : 3|1@0+ (1,0) [0|1] "B"  HVESP01
 SG_ HVESP01_Des_stcu_fault_reset_7 : 4|1@0+ (1,0) [0|1] "B"  HVESP01
 SG_ HVESP01_Des_fccu_ftr_reset_7 : 5|1@0+ (1,0) [0|1] "B"  HVESP01
 SG_ HVESP01_Des_software_dest_reset_7 : 6|1@0+ (1,0) [0|1] "B"  HVESP01
 SG_ HVESP01_Des_power_on_reset_7 : 7|1@0+ (1,0) [0|1] "B"  HVESP01
 SG_ HVESP01_Fes_VOR_fn_reset_7 : 8|1@0+ (1,0) [0|1] "B"  HVESP01
 SG_ HVESP01_Fes_TS_fn_reset_7 : 9|1@0+ (1,0) [0|1] "B"  HVESP01
 SG_ HVESP01_Fes_jtag_fn_reset_7 : 10|1@0+ (1,0) [0|1] "B"  HVESP01
 SG_ HVESP01_Fes_fccu_soft_reset_7 : 11|1@0+ (1,0) [0|1] "B"  HVESP01
 SG_ HVESP01_Fes_fccu_hard_reset_7 : 12|1@0+ (1,0) [0|1] "B"  HVESP01
 SG_ HVESP01_Fes_external_reset_7 : 13|1@0+ (1,0) [0|1] "B"  HVESP01
 SG_ HVESP01_Fes_software_fn_reset_7 : 14|1@0+ (1,0) [0|1] "B"  HVESP01
 SG_ HVESP01_Fes_self_test_done_reset_7 : 15|1@0+ (1,0) [0|1] "B"  HVESP01

BO_ 2499761260 HVESP01_ResetReason_8: 8 HVESP01
 SG_ HVESP01_Des_VOR_reset_8 : 0|1@0+ (1,0) [0|1] "B"  HVESP01
 SG_ HVESP01_Des_TS_reset_8 : 1|1@0+ (1,0) [0|1] "B"  HVESP01
 SG_ HVESP01_Des_flash_init_reset_8 : 2|1@0+ (1,0) [0|1] "B"  HVESP01
 SG_ HVESP01_Des_fn_reset_escn_8 : 3|1@0+ (1,0) [0|1] "B"  HVESP01
 SG_ HVESP01_Des_stcu_fault_reset_8 : 4|1@0+ (1,0) [0|1] "B"  HVESP01
 SG_ HVESP01_Des_fccu_ftr_reset_8 : 5|1@0+ (1,0) [0|1] "B"  HVESP01
 SG_ HVESP01_Des_software_dest_reset_8 : 6|1@0+ (1,0) [0|1] "B"  HVESP01
 SG_ HVESP01_Des_power_on_reset_8 : 7|1@0+ (1,0) [0|1] "B"  HVESP01
 SG_ HVESP01_Fes_VOR_fn_reset_8 : 8|1@0+ (1,0) [0|1] "B"  HVESP01
 SG_ HVESP01_Fes_TS_fn_reset_8 : 9|1@0+ (1,0) [0|1] "B"  HVESP01
 SG_ HVESP01_Fes_jtag_fn_reset_8 : 10|1@0+ (1,0) [0|1] "B"  HVESP01
 SG_ HVESP01_Fes_fccu_soft_reset_8 : 11|1@0+ (1,0) [0|1] "B"  HVESP01
 SG_ HVESP01_Fes_fccu_hard_reset_8 : 12|1@0+ (1,0) [0|1] "B"  HVESP01
 SG_ HVESP01_Fes_external_reset_8 : 13|1@0+ (1,0) [0|1] "B"  HVESP01
 SG_ HVESP01_Fes_software_fn_reset_8 : 14|1@0+ (1,0) [0|1] "B"  HVESP01
 SG_ HVESP01_Fes_self_test_done_reset_8 : 15|1@0+ (1,0) [0|1] "B"  HVESP01

BA_DEF_ BO_  "GenMsgDiag" ENUM "No","Yes";
BA_DEF_ BO_  "GenMsgInstanced" STRING ;
BA_DEF_ SG_  "SigType" ENUM "Default","Range","RangeSigned","ASCII","Discrete","Control","ReferencePGN","DTC","StringDelimiter","StringLength","StringLengthControl","MessageCounter","MessageChecksum";
BA_DEF_ SG_  "GenSigEVName" STRING ;
BA_DEF_ SG_  "GenSigILSupport" ENUM "No","Yes";
BA_DEF_ SG_  "GenSigSendType" ENUM "Cyclic","OnWrite","OnWriteWithRepetition","OnChange","OnChangeWithRepetition","IfActive","IfActiveWithRepetition","NoSigSendType";
BA_DEF_ BO_  "GenMsgILSupport" ENUM "No","Yes";
BA_DEF_ BO_  "GenMsgSendType" ENUM "cyclic","NotUsed","IfActive","NotUsed","NotUsed","NotUsed","NotUsed","NotUsed","noMsgSendType";
BA_DEF_ BO_  "GenMsgRequestable" INT 0 1;
BA_DEF_ BO_  "GenMsgCycleTime" INT 0 3600000;
BA_DEF_ BO_  "VFrameFormat" ENUM "StandardCAN","ExtendedCAN","reserved","J1939PG";
BA_DEF_ SG_  "SystemSignalLongSymbol" STRING ;
BA_DEF_DEF_  "GenMsgDiag" "No";
BA_DEF_DEF_  "GenMsgInstanced" "No";
BA_DEF_DEF_  "SigType" "Default";
BA_DEF_DEF_  "GenSigEVName" "Env@Nodename_@Signame";
BA_DEF_DEF_  "GenSigILSupport" "Yes";
BA_DEF_DEF_  "GenSigSendType" "NoSigSendType";
BA_DEF_DEF_  "GenMsgILSupport" "Yes";
BA_DEF_DEF_  "GenMsgSendType" "noMsgSendType";
BA_DEF_DEF_  "GenMsgRequestable" 1;
BA_DEF_DEF_  "GenMsgCycleTime" 0;
BA_DEF_DEF_  "VFrameFormat" "J1939PG";
BA_DEF_DEF_  "SystemSignalLongSymbol" "";
BA_ "GenMsgDiag" BO_ 2499750245 1;
BA_ "GenMsgDiag" BO_ 2499750246 1;
BA_ "GenMsgDiag" BO_ 2499750247 1;
BA_ "GenMsgDiag" BO_ 2499750248 1;
BA_ "GenMsgDiag" BO_ 2499750249 1;
BA_ "GenMsgDiag" BO_ 2499750250 1;
BA_ "GenMsgDiag" BO_ 2499750251 1;
BA_ "GenMsgDiag" BO_ 2499750252 1;
BA_ "GenMsgDiag" BO_ 2499760741 1;
BA_ "GenMsgDiag" BO_ 2499760742 1;
BA_ "GenMsgDiag" BO_ 2499760743 1;
BA_ "GenMsgDiag" BO_ 2499760744 1;
BA_ "GenMsgDiag" BO_ 2499760745 1;
BA_ "GenMsgDiag" BO_ 2499760746 1;
BA_ "GenMsgDiag" BO_ 2499760747 1;
BA_ "GenMsgDiag" BO_ 2499760748 1;
BA_ "GenMsgDiag" BO_ 2499761253 1;
BA_ "GenMsgDiag" BO_ 2499761254 1;
BA_ "GenMsgDiag" BO_ 2499761255 1;
BA_ "GenMsgDiag" BO_ 2499761256 1;
BA_ "GenMsgDiag" BO_ 2499761257 1;
BA_ "GenMsgDiag" BO_ 2499761258 1;
BA_ "GenMsgDiag" BO_ 2499761259 1;
BA_ "GenMsgDiag" BO_ 2499761260 1;
BA_ "GenMsgInstanced" BO_ 2499750245 "False";
BA_ "GenMsgInstanced" BO_ 2499750246 "False";
BA_ "GenMsgInstanced" BO_ 2499750247 "False";
BA_ "GenMsgInstanced" BO_ 2499750248 "False";
BA_ "GenMsgInstanced" BO_ 2499750249 "False";
BA_ "GenMsgInstanced" BO_ 2499750250 "False";
BA_ "GenMsgInstanced" BO_ 2499750251 "False";
BA_ "GenMsgInstanced" BO_ 2499750252 "False";
BA_ "GenMsgInstanced" BO_ 2499752037 "False";
BA_ "GenMsgInstanced" BO_ 2499752038 "False";
BA_ "GenMsgInstanced" BO_ 2499752039 "False";
BA_ "GenMsgInstanced" BO_ 2499752040 "False";
BA_ "GenMsgInstanced" BO_ 2499752041 "False";
BA_ "GenMsgInstanced" BO_ 2499752042 "False";
BA_ "GenMsgInstanced" BO_ 2499752043 "False";
BA_ "GenMsgInstanced" BO_ 2499752044 "False";
BA_ "GenMsgInstanced" BO_ 2499756133 "False";
BA_ "GenMsgInstanced" BO_ 2499756134 "False";
BA_ "GenMsgInstanced" BO_ 2499756135 "False";
BA_ "GenMsgInstanced" BO_ 2499756136 "False";
BA_ "GenMsgInstanced" BO_ 2499756137 "False";
BA_ "GenMsgInstanced" BO_ 2499756138 "False";
BA_ "GenMsgInstanced" BO_ 2499756139 "False";
BA_ "GenMsgInstanced" BO_ 2499756140 "False";
BA_ "GenMsgInstanced" BO_ 2499760229 "False";
BA_ "GenMsgInstanced" BO_ 2499760230 "False";
BA_ "GenMsgInstanced" BO_ 2499760231 "False";
BA_ "GenMsgInstanced" BO_ 2499760232 "False";
BA_ "GenMsgInstanced" BO_ 2499760233 "False";
BA_ "GenMsgInstanced" BO_ 2499760234 "False";
BA_ "GenMsgInstanced" BO_ 2499760235 "False";
BA_ "GenMsgInstanced" BO_ 2499760236 "False";
BA_ "GenMsgInstanced" BO_ 2499760741 "False";
BA_ "GenMsgInstanced" BO_ 2499760742 "False";
BA_ "GenMsgInstanced" BO_ 2499760743 "False";
BA_ "GenMsgInstanced" BO_ 2499760744 "False";
BA_ "GenMsgInstanced" BO_ 2499760745 "False";
BA_ "GenMsgInstanced" BO_ 2499760746 "False";
BA_ "GenMsgInstanced" BO_ 2499760747 "False";
BA_ "GenMsgInstanced" BO_ 2499760748 "False";
BA_ "GenMsgInstanced" BO_ 2499760997 "False";
BA_ "GenMsgInstanced" BO_ 2499760998 "False";
BA_ "GenMsgInstanced" BO_ 2499760999 "False";
BA_ "GenMsgInstanced" BO_ 2499761000 "False";
BA_ "GenMsgInstanced" BO_ 2499761001 "False";
BA_ "GenMsgInstanced" BO_ 2499761002 "False";
BA_ "GenMsgInstanced" BO_ 2499761003 "False";
BA_ "GenMsgInstanced" BO_ 2499761004 "False";
BA_ "GenMsgInstanced" BO_ 2499761253 "False";
BA_ "GenMsgInstanced" BO_ 2499761254 "False";
BA_ "GenMsgInstanced" BO_ 2499761255 "False";
BA_ "GenMsgInstanced" BO_ 2499761256 "False";
BA_ "GenMsgInstanced" BO_ 2499761257 "False";
BA_ "GenMsgInstanced" BO_ 2499761258 "False";
BA_ "GenMsgInstanced" BO_ 2499761259 "False";
BA_ "GenMsgInstanced" BO_ 2499761260 "False";
BA_ "GenMsgSendType" BO_ 2499760741 0;
BA_ "GenMsgSendType" BO_ 2499760742 0;
BA_ "GenMsgSendType" BO_ 2499760743 0;
BA_ "GenMsgSendType" BO_ 2499760744 0;
BA_ "GenMsgSendType" BO_ 2499760745 0;
BA_ "GenMsgSendType" BO_ 2499760746 0;
BA_ "GenMsgSendType" BO_ 2499760747 0;
BA_ "GenMsgSendType" BO_ 2499760748 0;
BA_ "GenMsgSendType" BO_ 2499760997 0;
BA_ "GenMsgSendType" BO_ 2499760998 0;
BA_ "GenMsgSendType" BO_ 2499760999 0;
BA_ "GenMsgSendType" BO_ 2499761000 0;
BA_ "GenMsgSendType" BO_ 2499761001 0;
BA_ "GenMsgSendType" BO_ 2499761002 0;
BA_ "GenMsgSendType" BO_ 2499761003 0;
BA_ "GenMsgSendType" BO_ 2499761004 0;
BA_ "GenMsgSendType" BO_ 2499761253 0;
BA_ "GenMsgSendType" BO_ 2499761254 0;
BA_ "GenMsgSendType" BO_ 2499761255 0;
BA_ "GenMsgSendType" BO_ 2499761256 0;
BA_ "GenMsgSendType" BO_ 2499761257 0;
BA_ "GenMsgSendType" BO_ 2499761258 0;
BA_ "GenMsgSendType" BO_ 2499761259 0;
BA_ "GenMsgSendType" BO_ 2499761260 0;
BA_ "GenMsgCycleTime" BO_ 2499752037 100;
BA_ "GenMsgCycleTime" BO_ 2499752038 100;
BA_ "GenMsgCycleTime" BO_ 2499752039 100;
BA_ "GenMsgCycleTime" BO_ 2499752040 100;
BA_ "GenMsgCycleTime" BO_ 2499752041 100;
BA_ "GenMsgCycleTime" BO_ 2499752042 100;
BA_ "GenMsgCycleTime" BO_ 2499752043 100;
BA_ "GenMsgCycleTime" BO_ 2499752044 100;
BA_ "GenMsgCycleTime" BO_ 2499756133 100;
BA_ "GenMsgCycleTime" BO_ 2499756134 100;
BA_ "GenMsgCycleTime" BO_ 2499756135 100;
BA_ "GenMsgCycleTime" BO_ 2499756136 100;
BA_ "GenMsgCycleTime" BO_ 2499756137 100;
BA_ "GenMsgCycleTime" BO_ 2499756138 100;
BA_ "GenMsgCycleTime" BO_ 2499756139 100;
BA_ "GenMsgCycleTime" BO_ 2499756140 100;
BA_ "GenMsgCycleTime" BO_ 2499760229 100;
BA_ "GenMsgCycleTime" BO_ 2499760230 100;
BA_ "GenMsgCycleTime" BO_ 2499760231 100;
BA_ "GenMsgCycleTime" BO_ 2499760232 100;
BA_ "GenMsgCycleTime" BO_ 2499760233 100;
BA_ "GenMsgCycleTime" BO_ 2499760234 100;
BA_ "GenMsgCycleTime" BO_ 2499760235 100;
BA_ "GenMsgCycleTime" BO_ 2499760236 100;
BA_ "GenMsgCycleTime" BO_ 2499760741 1000;
BA_ "GenMsgCycleTime" BO_ 2499760742 1000;
BA_ "GenMsgCycleTime" BO_ 2499760743 1000;
BA_ "GenMsgCycleTime" BO_ 2499760744 1000;
BA_ "GenMsgCycleTime" BO_ 2499760745 1000;
BA_ "GenMsgCycleTime" BO_ 2499760746 1000;
BA_ "GenMsgCycleTime" BO_ 2499760747 1000;
BA_ "GenMsgCycleTime" BO_ 2499760748 1000;
BA_ "GenMsgCycleTime" BO_ 2499760997 1000;
BA_ "GenMsgCycleTime" BO_ 2499760998 1000;
BA_ "GenMsgCycleTime" BO_ 2499760999 1000;
BA_ "GenMsgCycleTime" BO_ 2499761000 1000;
BA_ "GenMsgCycleTime" BO_ 2499761001 1000;
BA_ "GenMsgCycleTime" BO_ 2499761002 1000;
BA_ "GenMsgCycleTime" BO_ 2499761003 1000;
BA_ "GenMsgCycleTime" BO_ 2499761004 1000;
BA_ "GenMsgCycleTime" BO_ 2499761253 100;
BA_ "GenMsgCycleTime" BO_ 2499761254 100;
BA_ "GenMsgCycleTime" BO_ 2499761255 100;
BA_ "GenMsgCycleTime" BO_ 2499761256 100;
BA_ "GenMsgCycleTime" BO_ 2499761257 100;
BA_ "GenMsgCycleTime" BO_ 2499761258 100;
BA_ "GenMsgCycleTime" BO_ 2499761259 100;
BA_ "GenMsgCycleTime" BO_ 2499761260 100;
BA_ "VFrameFormat" BO_ 2499750245 1;
BA_ "VFrameFormat" BO_ 2499750246 1;
BA_ "VFrameFormat" BO_ 2499750247 1;
BA_ "VFrameFormat" BO_ 2499750248 1;
BA_ "VFrameFormat" BO_ 2499750249 1;
BA_ "VFrameFormat" BO_ 2499750250 1;
BA_ "VFrameFormat" BO_ 2499750251 1;
BA_ "VFrameFormat" BO_ 2499750252 1;
BA_ "VFrameFormat" BO_ 2499752037 1;
BA_ "VFrameFormat" BO_ 2499752038 1;
BA_ "VFrameFormat" BO_ 2499752039 1;
BA_ "VFrameFormat" BO_ 2499752040 1;
BA_ "VFrameFormat" BO_ 2499752041 1;
BA_ "VFrameFormat" BO_ 2499752042 1;
BA_ "VFrameFormat" BO_ 2499752043 1;
BA_ "VFrameFormat" BO_ 2499752044 1;
BA_ "VFrameFormat" BO_ 2499756133 1;
BA_ "VFrameFormat" BO_ 2499756134 1;
BA_ "VFrameFormat" BO_ 2499756135 1;
BA_ "VFrameFormat" BO_ 2499756136 1;
BA_ "VFrameFormat" BO_ 2499756137 1;
BA_ "VFrameFormat" BO_ 2499756138 1;
BA_ "VFrameFormat" BO_ 2499756139 1;
BA_ "VFrameFormat" BO_ 2499756140 1;
BA_ "VFrameFormat" BO_ 2499760229 1;
BA_ "VFrameFormat" BO_ 2499760230 1;
BA_ "VFrameFormat" BO_ 2499760231 1;
BA_ "VFrameFormat" BO_ 2499760232 1;
BA_ "VFrameFormat" BO_ 2499760233 1;
BA_ "VFrameFormat" BO_ 2499760234 1;
BA_ "VFrameFormat" BO_ 2499760235 1;
BA_ "VFrameFormat" BO_ 2499760236 1;
BA_ "SystemSignalLongSymbol" SG_ 2499760997 HVESP01_packBoardDetails_revPath_1 "HVESP01_packBoardDetails_revPathBreak";
BA_ "SystemSignalLongSymbol" SG_ 2499760997 HVESP01_packBoardDetails_fwdPath_1 "HVESP01_packBoardDetails_fwdPathBreak";
BA_ "SystemSignalLongSymbol" SG_ 2499760998 HVESP01_packBoardDetails_fwdPath_2 "HVESP01_packBoardDetails_fwdPathBreak";
BA_ "SystemSignalLongSymbol" SG_ 2499760998 HVESP01_packBoardDetails_revPath_2 "HVESP01_packBoardDetails_revPathBreak";
BA_ "SystemSignalLongSymbol" SG_ 2499760999 HVESP01_packBoardDetails_fwdPath_3 "HVESP01_packBoardDetails_fwdPathBreak";
BA_ "SystemSignalLongSymbol" SG_ 2499760999 HVESP01_packBoardDetails_revPath_3 "HVESP01_packBoardDetails_revPathBreak";
BA_ "SystemSignalLongSymbol" SG_ 2499761000 HVESP01_packBoardDetails_revPath_4 "HVESP01_packBoardDetails_revPathBreak";
BA_ "SystemSignalLongSymbol" SG_ 2499761000 HVESP01_packBoardDetails_fwdPath_4 "HVESP01_packBoardDetails_fwdPathBreak";
BA_ "SystemSignalLongSymbol" SG_ 2499761001 HVESP01_packBoardDetails_fwdPath_5 "HVESP01_packBoardDetails_fwdPathBreak";
BA_ "SystemSignalLongSymbol" SG_ 2499761001 HVESP01_packBoardDetails_revPath_5 "HVESP01_packBoardDetails_revPathBreak";
BA_ "SystemSignalLongSymbol" SG_ 2499761002 HVESP01_packBoardDetails_fwdPath_6 "HVESP01_packBoardDetails_fwdPathBreak";
BA_ "SystemSignalLongSymbol" SG_ 2499761002 HVESP01_packBoardDetails_revPath_6 "HVESP01_packBoardDetails_revPathBreak";
BA_ "SystemSignalLongSymbol" SG_ 2499761003 HVESP01_packBoardDetails_fwdPath_7 "HVESP01_packBoardDetails_fwdPathBreak";
BA_ "SystemSignalLongSymbol" SG_ 2499761003 HVESP01_packBoardDetails_revPath_7 "HVESP01_packBoardDetails_revPathBreak";
BA_ "SystemSignalLongSymbol" SG_ 2499761004 HVESP01_packBoardDetails_revPath_8 "HVESP01_packBoardDetails_revPathBreak";
BA_ "SystemSignalLongSymbol" SG_ 2499761004 HVESP01_packBoardDetails_fwdPath_8 "HVESP01_packBoardDetails_fwdPathBreak";
VAL_ 2499760229 HVESP01_seriesP2_negCt_StatusReq_1  3 "DontCare"  2 "EmergencyContactorClose"  1 "CloseContactor"  0 "OpenContactor"  ;
VAL_ 2499760229 HVESP01_seriesP1_PosCt_StatusReq_1  3 "DontCare"  2 "EmergencyContactorClose"  1 "CloseContactor"  0 "OpenContactor"  ;
VAL_ 2499760229 HVESP01_seriesP1_PreCg_StatusReq_1  3 "DontCare"  2 "EmergencyContactorClose"  1 "CloseContactor"  0 "OpenContactor"  ;
VAL_ 2499760229 HVESP01_seriesP2_PosCt_StatusReq_1  3 "DontCare"  2 "EmergencyContactorClose"  1 "CloseContactor"  0 "OpenContactor"  ;
VAL_ 2499760229 HVESP01_seriesP1_negCt_StatusReq_1  3 "DontCare"  2 "EmergencyContactorClose"  1 "CloseContactor"  0 "OpenContactor"  ;
VAL_ 2499760229 HVESP01_seriesP2_PreCg_StatusReq_1  3 "DontCare"  2 "EmergencyContactorClose"  1 "CloseContactor"  0 "OpenContactor"  ;
VAL_ 2499760230 HVESP01_seriesP1_negCt_StatusReq_2  3 "DontCare"  2 "EmergencyContactorClose"  1 "CloseContactor"  0 "OpenContactor"  ;
VAL_ 2499760230 HVESP01_seriesP1_PosCt_StatusReq_2  3 "DontCare"  2 "EmergencyContactorClose"  1 "CloseContactor"  0 "OpenContactor"  ;
VAL_ 2499760230 HVESP01_seriesP2_negCt_StatusReq_2  3 "DontCare"  2 "EmergencyContactorClose"  1 "CloseContactor"  0 "OpenContactor"  ;
VAL_ 2499760230 HVESP01_seriesP1_PreCg_StatusReq_2  3 "DontCare"  2 "EmergencyContactorClose"  1 "CloseContactor"  0 "OpenContactor"  ;
VAL_ 2499760230 HVESP01_seriesP2_PosCt_StatusReq_2  3 "DontCare"  2 "EmergencyContactorClose"  1 "CloseContactor"  0 "OpenContactor"  ;
VAL_ 2499760230 HVESP01_seriesP2_PreCg_StatusReq_2  3 "DontCare"  2 "EmergencyContactorClose"  1 "CloseContactor"  0 "OpenContactor"  ;
VAL_ 2499760231 HVESP01_seriesP2_PreCg_StatusReq_3  3 "DontCare"  2 "EmergencyContactorClose"  1 "CloseContactor"  0 "OpenContactor"  ;
VAL_ 2499760231 HVESP01_seriesP2_negCt_StatusReq_3  3 "DontCare"  2 "EmergencyContactorClose"  1 "CloseContactor"  0 "OpenContactor"  ;
VAL_ 2499760231 HVESP01_seriesP1_negCt_StatusReq_3  3 "DontCare"  2 "EmergencyContactorClose"  1 "CloseContactor"  0 "OpenContactor"  ;
VAL_ 2499760231 HVESP01_seriesP1_PosCt_StatusReq_3  3 "DontCare"  2 "EmergencyContactorClose"  1 "CloseContactor"  0 "OpenContactor"  ;
VAL_ 2499760231 HVESP01_seriesP2_PosCt_StatusReq_3  3 "DontCare"  2 "EmergencyContactorClose"  1 "CloseContactor"  0 "OpenContactor"  ;
VAL_ 2499760231 HVESP01_seriesP1_PreCg_StatusReq_3  3 "DontCare"  2 "EmergencyContactorClose"  1 "CloseContactor"  0 "OpenContactor"  ;
VAL_ 2499760232 HVESP01_seriesP1_PosCt_StatusReq_4  3 "DontCare"  2 "EmergencyContactorClose"  1 "CloseContactor"  0 "OpenContactor"  ;
VAL_ 2499760232 HVESP01_seriesP1_PreCg_StatusReq_4  3 "DontCare"  2 "EmergencyContactorClose"  1 "CloseContactor"  0 "OpenContactor"  ;
VAL_ 2499760232 HVESP01_seriesP2_PosCt_StatusReq_4  3 "DontCare"  2 "EmergencyContactorClose"  1 "CloseContactor"  0 "OpenContactor"  ;
VAL_ 2499760232 HVESP01_seriesP2_PreCg_StatusReq_4  3 "DontCare"  2 "EmergencyContactorClose"  1 "CloseContactor"  0 "OpenContactor"  ;
VAL_ 2499760232 HVESP01_seriesP2_negCt_StatusReq_4  3 "DontCare"  2 "EmergencyContactorClose"  1 "CloseContactor"  0 "OpenContactor"  ;
VAL_ 2499760232 HVESP01_seriesP1_negCt_StatusReq_4  3 "DontCare"  2 "EmergencyContactorClose"  1 "CloseContactor"  0 "OpenContactor"  ;
VAL_ 2499760233 HVESP01_seriesP2_PreCg_StatusReq_5  3 "DontCare"  2 "EmergencyContactorClose"  1 "CloseContactor"  0 "OpenContactor"  ;
VAL_ 2499760233 HVESP01_seriesP2_negCt_StatusReq_5  3 "DontCare"  2 "EmergencyContactorClose"  1 "CloseContactor"  0 "OpenContactor"  ;
VAL_ 2499760233 HVESP01_seriesP1_PreCg_StatusReq_5  3 "DontCare"  2 "EmergencyContactorClose"  1 "CloseContactor"  0 "OpenContactor"  ;
VAL_ 2499760233 HVESP01_seriesP1_negCt_StatusReq_5  3 "DontCare"  2 "EmergencyContactorClose"  1 "CloseContactor"  0 "OpenContactor"  ;
VAL_ 2499760233 HVESP01_seriesP1_PosCt_StatusReq_5  3 "DontCare"  2 "EmergencyContactorClose"  1 "CloseContactor"  0 "OpenContactor"  ;
VAL_ 2499760233 HVESP01_seriesP2_PosCt_StatusReq_5  3 "DontCare"  2 "EmergencyContactorClose"  1 "CloseContactor"  0 "OpenContactor"  ;
VAL_ 2499760234 HVESP01_seriesP2_PreCg_StatusReq_6  3 "DontCare"  2 "EmergencyContactorClose"  1 "CloseContactor"  0 "OpenContactor"  ;
VAL_ 2499760234 HVESP01_seriesP1_negCt_StatusReq_6  3 "DontCare"  2 "EmergencyContactorClose"  1 "CloseContactor"  0 "OpenContactor"  ;
VAL_ 2499760234 HVESP01_seriesP2_PosCt_StatusReq_6  3 "DontCare"  2 "EmergencyContactorClose"  1 "CloseContactor"  0 "OpenContactor"  ;
VAL_ 2499760234 HVESP01_seriesP2_negCt_StatusReq_6  3 "DontCare"  2 "EmergencyContactorClose"  1 "CloseContactor"  0 "OpenContactor"  ;
VAL_ 2499760234 HVESP01_seriesP1_PosCt_StatusReq_6  3 "DontCare"  2 "EmergencyContactorClose"  1 "CloseContactor"  0 "OpenContactor"  ;
VAL_ 2499760234 HVESP01_seriesP1_PreCg_StatusReq_6  3 "DontCare"  2 "EmergencyContactorClose"  1 "CloseContactor"  0 "OpenContactor"  ;
VAL_ 2499760235 HVESP01_seriesP1_negCt_StatusReq_7  3 "DontCare"  2 "EmergencyContactorClose"  1 "CloseContactor"  0 "OpenContactor"  ;
VAL_ 2499760235 HVESP01_seriesP2_negCt_StatusReq_7  3 "DontCare"  2 "EmergencyContactorClose"  1 "CloseContactor"  0 "OpenContactor"  ;
VAL_ 2499760235 HVESP01_seriesP2_PosCt_StatusReq_7  3 "DontCare"  2 "EmergencyContactorClose"  1 "CloseContactor"  0 "OpenContactor"  ;
VAL_ 2499760235 HVESP01_seriesP1_PreCg_StatusReq_7  3 "DontCare"  2 "EmergencyContactorClose"  1 "CloseContactor"  0 "OpenContactor"  ;
VAL_ 2499760235 HVESP01_seriesP1_PosCt_StatusReq_7  3 "DontCare"  2 "EmergencyContactorClose"  1 "CloseContactor"  0 "OpenContactor"  ;
VAL_ 2499760235 HVESP01_seriesP2_PreCg_StatusReq_7  3 "DontCare"  2 "EmergencyContactorClose"  1 "CloseContactor"  0 "OpenContactor"  ;
VAL_ 2499760236 HVESP01_seriesP1_PosCt_StatusReq_8  3 "DontCare"  2 "EmergencyContactorClose"  1 "CloseContactor"  0 "OpenContactor"  ;
VAL_ 2499760236 HVESP01_seriesP1_PreCg_StatusReq_8  3 "DontCare"  2 "EmergencyContactorClose"  1 "CloseContactor"  0 "OpenContactor"  ;
VAL_ 2499760236 HVESP01_seriesP1_negCt_StatusReq_8  3 "DontCare"  2 "EmergencyContactorClose"  1 "CloseContactor"  0 "OpenContactor"  ;
VAL_ 2499760236 HVESP01_seriesP2_PreCg_StatusReq_8  3 "DontCare"  2 "EmergencyContactorClose"  1 "CloseContactor"  0 "OpenContactor"  ;
VAL_ 2499760236 HVESP01_seriesP2_PosCt_StatusReq_8  3 "DontCare"  2 "EmergencyContactorClose"  1 "CloseContactor"  0 "OpenContactor"  ;
VAL_ 2499760236 HVESP01_seriesP2_negCt_StatusReq_8  3 "DontCare"  2 "EmergencyContactorClose"  1 "CloseContactor"  0 "OpenContactor"  ;
VAL_ 2499760997 HVESP01_packBoardDetails_board_1  3 "Unknown"  2 "Core"  1 "JuiceBox"  0 "BaldEagle"  ;
VAL_ 2499760998 HVESP01_packBoardDetails_board_2  3 "Unknown"  2 "Core"  1 "JuiceBox"  0 "BaldEagle"  ;
VAL_ 2499760999 HVESP01_packBoardDetails_board_3  3 "Unknown"  2 "Core"  1 "JuiceBox"  0 "BaldEagle"  ;
VAL_ 2499761000 HVESP01_packBoardDetails_board_4  3 "Unknown"  2 "Core"  1 "JuiceBox"  0 "BaldEagle"  ;
VAL_ 2499761001 HVESP01_packBoardDetails_board_5  3 "Unknown"  2 "Core"  1 "JuiceBox"  0 "BaldEagle"  ;
VAL_ 2499761002 HVESP01_packBoardDetails_board_6  3 "Unknown"  2 "Core"  1 "JuiceBox"  0 "BaldEagle"  ;
VAL_ 2499761003 HVESP01_packBoardDetails_board_7  3 "Unknown"  2 "Core"  1 "JuiceBox"  0 "BaldEagle"  ;
VAL_ 2499761004 HVESP01_packBoardDetails_board_8  3 "Unknown"  2 "Core"  1 "JuiceBox"  0 "BaldEagle"  ;
